VERSION "2021.24.4"

NS_ :

BS_:

BU_: VEH CH Receiver X

BA_DEF_ BO_ "GenMsgSendType" ENUM "Cyclic";
BA_DEF_ BO_ "GenMsgCycleTime" INT 0 10000;

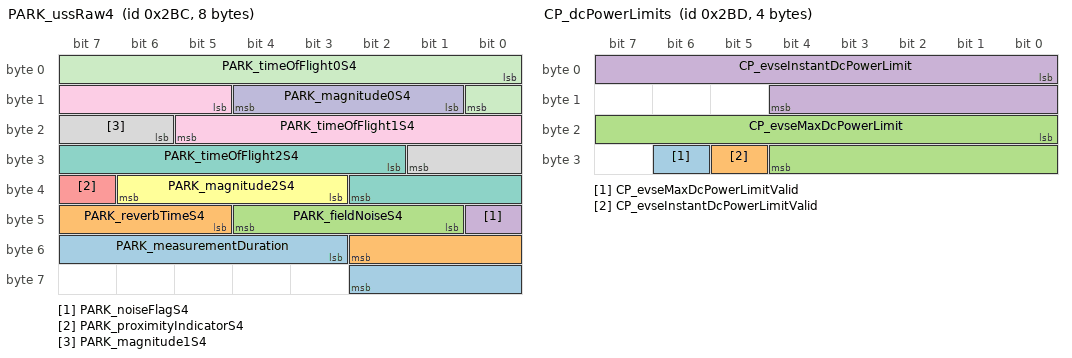
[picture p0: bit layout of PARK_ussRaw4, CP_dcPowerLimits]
BO_ 700 PARK_ussRaw4: 8 Vector__XXX
 SG_ PARK_measurementDuration : 51|8@1+ (0.0512,0) [0|0] "" Vector__XXX
 SG_ PARK_reverbTimeS4 : 45|6@1+ (0.0512,0) [0|0] "" Vector__XXX
 SG_ PARK_fieldNoiseS4 : 41|4@1+ (1,0) [0|0] "" Vector__XXX
 SG_ PARK_noiseFlagS4 : 40|1@1+ (1,0) [0|0] "" Vector__XXX
 SG_ PARK_proximityIndicatorS4 : 39|1@1+ (1,0) [0|0] "" Vector__XXX
 SG_ PARK_magnitude2S4 : 35|4@1+ (2,0) [0|0] "" Vector__XXX
 SG_ PARK_timeOfFlight2S4 : 26|9@1+ (0.0512,0) [0|0] "" Vector__XXX
 SG_ PARK_magnitude1S4 : 22|4@1+ (2,0) [0|0] "" Vector__XXX
 SG_ PARK_timeOfFlight1S4 : 13|9@1+ (0.0512,0) [0|0] "" Vector__XXX
 SG_ PARK_magnitude0S4 : 9|4@1+ (2,0) [0|0] "" Vector__XXX
 SG_ PARK_timeOfFlight0S4 : 0|9@1+ (0.0512,0) [0|0] "" Vector__XXX

BO_ 701 CP_dcPowerLimits: 4 Vector__XXX
 SG_ CP_evseMaxDcPowerLimitValid : 30|1@1+ (1,0) [0|0] "" Vector__XXX
 SG_ CP_evseInstantDcPowerLimitValid : 29|1@1+ (1,0) [0|0] "" Vector__XXX
 SG_ CP_evseMaxDcPowerLimit : 16|13@1+ (0.25,0) [0|0] "" Vector__XXX
 SG_ CP_evseInstantDcPowerLimit : 0|13@1+ (0.25,0) [0|0] "" Vector__XXX

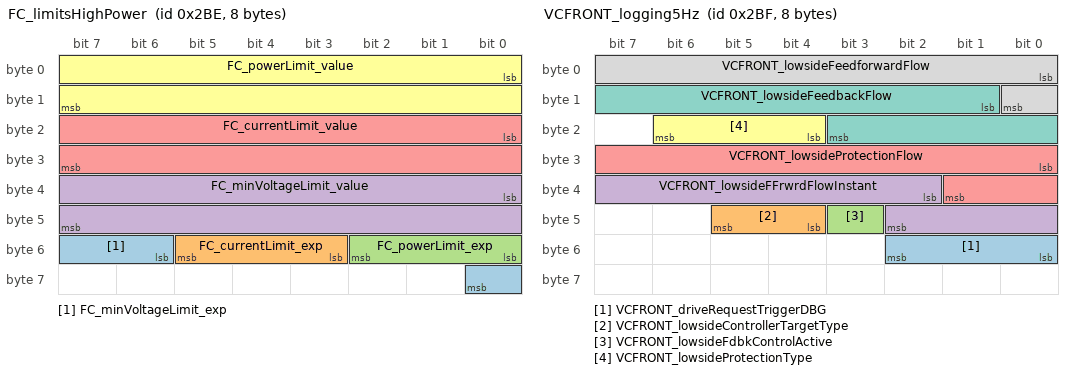
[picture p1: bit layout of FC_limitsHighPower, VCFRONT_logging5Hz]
BO_ 702 FC_limitsHighPower: 8 Vector__XXX
 SG_ FC_minVoltageLimit_exp : 54|3@1- (1,0) [0|0] "" Vector__XXX
 SG_ FC_currentLimit_exp : 51|3@1- (1,0) [0|0] "" Vector__XXX
 SG_ FC_powerLimit_exp : 48|3@1- (1,0) [0|0] "" Vector__XXX
 SG_ FC_minVoltageLimit_value : 32|16@1- (1,0) [0|0] "" Vector__XXX
 SG_ FC_currentLimit_value : 16|16@1- (1,0) [0|0] "" Vector__XXX
 SG_ FC_powerLimit_value : 0|16@1- (1,0) [0|0] "" Vector__XXX

BO_ 703 VCFRONT_logging5Hz: 8 Vector__XXX
 SG_ VCFRONT_driveRequestTriggerDBG : 48|3@1+ (1,0) [0|0] "" Vector__XXX
 SG_ VCFRONT_lowsideControllerTargetType : 44|2@1+ (1,0) [0|0] "" Vector__XXX
 SG_ VCFRONT_lowsideFdbkControlActive : 43|1@1+ (1,0) [0|0] "" Vector__XXX
 SG_ VCFRONT_lowsideFFrwrdFlowInstant : 34|9@1+ (0.2,0) [0|0] "" Vector__XXX
 SG_ VCFRONT_lowsideProtectionFlow : 24|10@1+ (0.1,0) [0|0] "" Vector__XXX
 SG_ VCFRONT_lowsideProtectionType : 20|3@1+ (1,0) [0|0] "" Vector__XXX
 SG_ VCFRONT_lowsideFeedbackFlow : 9|11@1- (0.1,0) [0|0] "" Vector__XXX
 SG_ VCFRONT_lowsideFeedforwardFlow : 0|9@1+ (0.2,0) [0|0] "" Vector__XXX

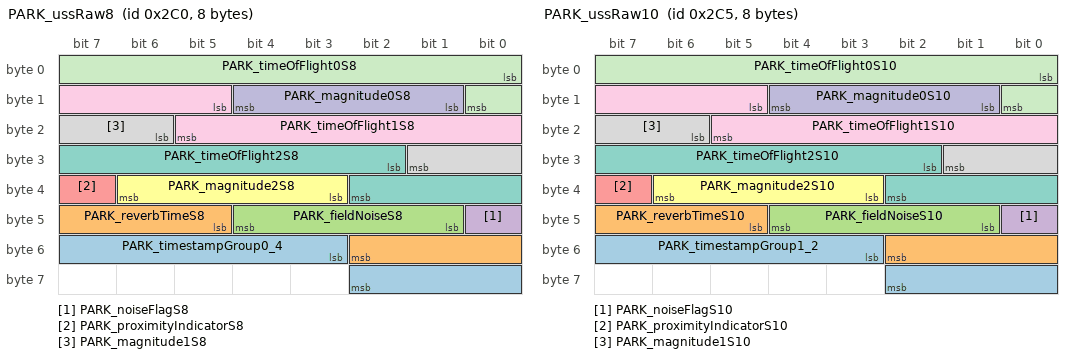
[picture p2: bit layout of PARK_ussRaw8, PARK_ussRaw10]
BO_ 704 PARK_ussRaw8: 8 Vector__XXX
 SG_ PARK_timestampGroup0_4 : 51|8@1+ (1,0) [0|0] "" Vector__XXX
 SG_ PARK_reverbTimeS8 : 45|6@1+ (0.0512,0) [0|0] "" Vector__XXX
 SG_ PARK_fieldNoiseS8 : 41|4@1+ (1,0) [0|0] "" Vector__XXX
 SG_ PARK_noiseFlagS8 : 40|1@1+ (1,0) [0|0] "" Vector__XXX
 SG_ PARK_proximityIndicatorS8 : 39|1@1+ (1,0) [0|0] "" Vector__XXX
 SG_ PARK_magnitude2S8 : 35|4@1+ (2,0) [0|0] "" Vector__XXX
 SG_ PARK_timeOfFlight2S8 : 26|9@1+ (0.0512,0) [0|0] "" Vector__XXX
 SG_ PARK_magnitude1S8 : 22|4@1+ (2,0) [0|0] "" Vector__XXX
 SG_ PARK_timeOfFlight1S8 : 13|9@1+ (0.0512,0) [0|0] "" Vector__XXX
 SG_ PARK_magnitude0S8 : 9|4@1+ (2,0) [0|0] "" Vector__XXX
 SG_ PARK_timeOfFlight0S8 : 0|9@1+ (0.0512,0) [0|0] "" Vector__XXX

BO_ 706 VCLEFT_windowStatus: 8 Vector__XXX
 SG_ VCLEFT_windowCalibratedLR m0 : 63|1@1+ (1,0) [0|0] "" Vector__XXX
 SG_ VCLEFT_windowSpeedTableStatusLR m1 : 62|2@1+ (1,0) [0|0] "" Vector__XXX
 SG_ VCLEFT_windowSpeedTableStatusLF m1 : 60|2@1+ (1,0) [0|0] "" Vector__XXX
 SG_ VCLEFT_windowVehGearStateLR m1 : 58|2@1+ (1,0) [0|0] "" Vector__XXX
 SG_ VCLEFT_windowVehGearStateLF m1 : 56|2@1+ (1,0) [0|0] "" Vector__XXX
 SG_ VCLEFT_windowPositionLR m0 : 54|9@1- (1.25,265) [0|0] "" Vector__XXX
 SG_ VCLEFT_windowPositionStateLR m1 : 52|3@1+ (1,0) [0|0] "" Vector__XXX
 SG_ VCLEFT_windowPositionStateLF m1 : 49|3@1+ (1,0) [0|0] "" Vector__XXX
 SG_ VCLEFT_windowCurrentLR m0 : 48|6@1- (0.5,0) [0|0] "" Vector__XXX
 SG_ VCLEFT_windowCtrlUnavailableLR m1 : 45|3@1+ (1,0) [0|0] "" Vector__XXX
 SG_ VCLEFT_windowControlStateLR m1 : 42|2@1+ (1,0) [0|0] "" Vector__XXX
 SG_ VCLEFT_windowDutyLR m0 : 40|6@1- (5,0) [0|0] "" Vector__XXX
 SG_ VCLEFT_windowCtrlUnavailableLF m1 : 38|3@1+ (1,0) [0|0] "" Vector__XXX
 SG_ VCLEFT_windowControlStateLF m1 : 35|2@1+ (1,0) [0|0] "" Vector__XXX
 SG_ VCLEFT_windowStateLR m0 : 33|4@1+ (1,0) [0|0] "" Vector__XXX
 SG_ VCLEFT_windowCalibratedLF m0 : 32|1@1+ (1,0) [0|0] "" Vector__XXX
 SG_ VCLEFT_windowStopReqReasonLR m1 : 31|4@1+ (1,0) [0|0] "" Vector__XXX
 SG_ VCLEFT_windowStopReasonLR m1 : 28|3@1+ (1,0) [0|0] "" Vector__XXX
 SG_ VCLEFT_windowThermalModeLR m1 : 26|2@1+ (1,0) [0|0] "" Vector__XXX
 SG_ VCLEFT_windowPositionLF m0 : 22|9@1- (1.25,265) [0|0] "" Vector__XXX
 SG_ VCLEFT_windowThermalTCLR m1 : 18|8@1+ (1,0) [0|0] "" Vector__XXX
 SG_ VCLEFT_windowCurrentLF m0 : 16|6@1- (0.5,0) [0|0] "" Vector__XXX
 SG_ VCLEFT_windowStopReqReasonLF m1 : 14|4@1+ (1,0) [0|0] "" Vector__XXX
 SG_ VCLEFT_windowTrimClearActiveRequest m0 : 14|2@1+ (1,0) [0|0] "" Vector__XXX
 SG_ VCLEFT_windowStopReasonLF m1 : 11|3@1+ (1,0) [0|0] "" Vector__XXX
 SG_ VCLEFT_windowThermalModeLF m1 : 9|2@1+ (1,0) [0|0] "" Vector__XXX
 SG_ VCLEFT_windowDutyLF m0 : 8|6@1- (5,0) [0|0] "" Vector__XXX
 SG_ VCLEFT_windowTrimClearMoveRequest m0 : 5|2@1+ (1,0) [0|0] "" Vector__XXX
 SG_ VCLEFT_windowStateLF m0 : 1|4@1+ (1,0) [0|0] "" Vector__XXX
 SG_ VCLEFT_windowThermalTCLF m1 : 1|8@1+ (1,0) [0|0] "" Vector__XXX
 SG_ VCLEFT_windowStatusIndex M : 0|1@1+ (1,0) [0|0] "" Vector__XXX

BO_ 707 VCRIGHT_windowStatus: 8 Vector__XXX
 SG_ VCRIGHT_windowCalibratedRR m0 : 63|1@1+ (1,0) [0|0] "" Vector__XXX
 SG_ VCRIGHT_windowSpeedTableStatusRR m1 : 62|2@1+ (1,0) [0|0] "" Vector__XXX
 SG_ VCRIGHT_windowSpeedTableStatusRF m1 : 60|2@1+ (1,0) [0|0] "" Vector__XXX
 SG_ VCRIGHT_windowVehGearStateRR m1 : 58|2@1+ (1,0) [0|0] "" Vector__XXX
 SG_ VCRIGHT_windowVehGearStateRF m1 : 56|2@1+ (1,0) [0|0] "" Vector__XXX
 SG_ VCRIGHT_windowPositionRR m0 : 54|9@1- (1.25,265) [0|0] "" Vector__XXX
 SG_ VCRIGHT_windowPositionStateRR m1 : 52|3@1+ (1,0) [0|0] "" Vector__XXX
 SG_ VCRIGHT_windowPositionStateRF m1 : 49|3@1+ (1,0) [0|0] "" Vector__XXX
 SG_ VCRIGHT_windowCurrentRR m0 : 48|6@1- (0.5,0) [0|0] "" Vector__XXX
 SG_ VCRIGHT_windowCtrlUnavailableRR m1 : 45|3@1+ (1,0) [0|0] "" Vector__XXX
 SG_ VCRIGHT_windowControlStateRR m1 : 42|2@1+ (1,0) [0|0] "" Vector__XXX
 SG_ VCRIGHT_windowDutyRR m0 : 40|6@1- (5,0) [0|0] "" Vector__XXX
 SG_ VCRIGHT_windowCtrlUnavailableRF m1 : 38|3@1+ (1,0) [0|0] "" Vector__XXX
 SG_ VCRIGHT_windowControlStateRF m1 : 35|2@1+ (1,0) [0|0] "" Vector__XXX
 SG_ VCRIGHT_windowStateRR m0 : 33|4@1+ (1,0) [0|0] "" Vector__XXX
 SG_ VCRIGHT_windowCalibratedRF m0 : 32|1@1+ (1,0) [0|0] "" Vector__XXX
 SG_ VCRIGHT_windowStopReqReasonRR m1 : 31|4@1+ (1,0) [0|0] "" Vector__XXX
 SG_ VCRIGHT_windowStopReasonRR m1 : 28|3@1+ (1,0) [0|0] "" Vector__XXX
 SG_ VCRIGHT_windowThermalModeRR m1 : 26|2@1+ (1,0) [0|0] "" Vector__XXX
 SG_ VCRIGHT_windowPositionRF m0 : 22|9@1- (1.25,265) [0|0] "" Vector__XXX
 SG_ VCRIGHT_windowThermalTCRR m1 : 18|8@1+ (1,0) [0|0] "" Vector__XXX
 SG_ VCRIGHT_windowCurrentRF m0 : 16|6@1- (0.5,0) [0|0] "" Vector__XXX
 SG_ VCRIGHT_windowStopReqReasonRF m1 : 14|4@1+ (1,0) [0|0] "" Vector__XXX
 SG_ VCRIGHT_windowTrimClearActiveRequest m0 : 14|2@1+ (1,0) [0|0] "" Vector__XXX
 SG_ VCRIGHT_windowStopReasonRF m1 : 11|3@1+ (1,0) [0|0] "" Vector__XXX
 SG_ VCRIGHT_windowThermalModeRF m1 : 9|2@1+ (1,0) [0|0] "" Vector__XXX
 SG_ VCRIGHT_windowDutyRF m0 : 8|6@1- (5,0) [0|0] "" Vector__XXX
 SG_ VCRIGHT_windowTrimClearMoveRequest m0 : 5|2@1+ (1,0) [0|0] "" Vector__XXX
 SG_ VCRIGHT_windowStateRF m0 : 1|4@1+ (1,0) [0|0] "" Vector__XXX
 SG_ VCRIGHT_windowThermalTCRF m1 : 1|8@1+ (1,0) [0|0] "" Vector__XXX
 SG_ VCRIGHT_windowStatusIndex M : 0|1@1+ (1,0) [0|0] "" Vector__XXX

BO_ 709 PARK_ussRaw10: 8 Vector__XXX
 SG_ PARK_timestampGroup1_2 : 51|8@1+ (1,0) [0|0] "" Vector__XXX
 SG_ PARK_reverbTimeS10 : 45|6@1+ (0.0512,0) [0|0] "" Vector__XXX
 SG_ PARK_fieldNoiseS10 : 41|4@1+ (1,0) [0|0] "" Vector__XXX
 SG_ PARK_noiseFlagS10 : 40|1@1+ (1,0) [0|0] "" Vector__XXX
 SG_ PARK_proximityIndicatorS10 : 39|1@1+ (1,0) [0|0] "" Vector__XXX
 SG_ PARK_magnitude2S10 : 35|4@1+ (2,0) [0|0] "" Vector__XXX
 SG_ PARK_timeOfFlight2S10 : 26|9@1+ (0.0512,0) [0|0] "" Vector__XXX
 SG_ PARK_magnitude1S10 : 22|4@1+ (2,0) [0|0] "" Vector__XXX
 SG_ PARK_timeOfFlight1S10 : 13|9@1+ (0.0512,0) [0|0] "" Vector__XXX
 SG_ PARK_magnitude0S10 : 9|4@1+ (2,0) [0|0] "" Vector__XXX
 SG_ PARK_timeOfFlight0S10 : 0|9@1+ (0.0512,0) [0|0] "" Vector__XXX

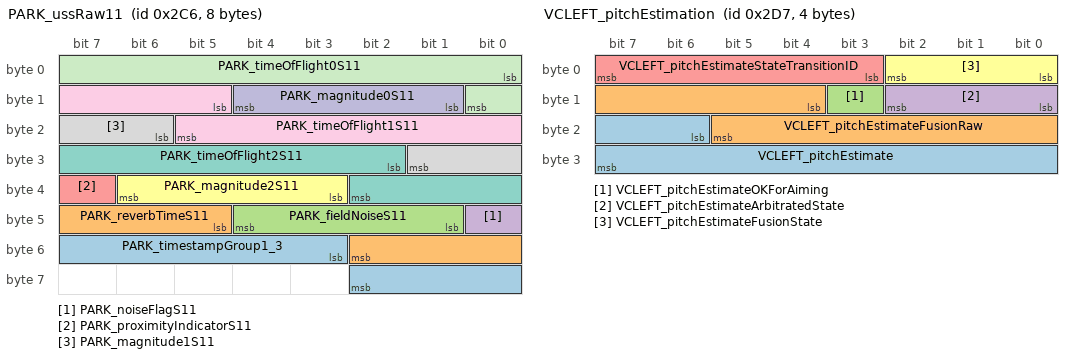
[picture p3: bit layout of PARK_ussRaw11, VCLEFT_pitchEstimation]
BO_ 710 PARK_ussRaw11: 8 Vector__XXX
 SG_ PARK_timestampGroup1_3 : 51|8@1+ (1,0) [0|0] "" Vector__XXX
 SG_ PARK_reverbTimeS11 : 45|6@1+ (0.0512,0) [0|0] "" Vector__XXX
 SG_ PARK_fieldNoiseS11 : 41|4@1+ (1,0) [0|0] "" Vector__XXX
 SG_ PARK_noiseFlagS11 : 40|1@1+ (1,0) [0|0] "" Vector__XXX
 SG_ PARK_proximityIndicatorS11 : 39|1@1+ (1,0) [0|0] "" Vector__XXX
 SG_ PARK_magnitude2S11 : 35|4@1+ (2,0) [0|0] "" Vector__XXX
 SG_ PARK_timeOfFlight2S11 : 26|9@1+ (0.0512,0) [0|0] "" Vector__XXX
 SG_ PARK_magnitude1S11 : 22|4@1+ (2,0) [0|0] "" Vector__XXX
 SG_ PARK_timeOfFlight1S11 : 13|9@1+ (0.0512,0) [0|0] "" Vector__XXX
 SG_ PARK_magnitude0S11 : 9|4@1+ (2,0) [0|0] "" Vector__XXX
 SG_ PARK_timeOfFlight0S11 : 0|9@1+ (0.0512,0) [0|0] "" Vector__XXX

BO_ 711 CMPD_faultsAndExtras: 8 Vector__XXX
 SG_ CMPD_inputLVVoltage : 56|8@1+ (0.1,0) [0|0] "" Vector__XXX
 SG_ CMPD_inverterTemperature : 48|8@1+ (1,-40) [0|0] "" Vector__XXX
 SG_ CMPD_IGBTTemperature : 40|8@1+ (1,-40) [0|0] "" Vector__XXX
 SG_ CMPD_overloadDetectionOfSpeed : 32|1@1+ (1,0) [0|0] "" Vector__XXX
 SG_ CMPD_overloadRestrictionCurrent : 31|1@1+ (1,0) [0|0] "" Vector__XXX
 SG_ CMPD_overloadLossOfSync : 30|1@1+ (1,0) [0|0] "" Vector__XXX
 SG_ CMPD_overloadStartFaultDetection : 29|1@1+ (1,0) [0|0] "" Vector__XXX
 SG_ CMPD_overloadStatus : 27|2@1+ (1,0) [0|0] "" Vector__XXX
 SG_ CMPD_overCurrent : 26|1@1+ (1,0) [0|0] "" Vector__XXX
 SG_ CMPD_failedStartRepeated : 25|1@1+ (1,0) [0|0] "" Vector__XXX
 SG_ CMPD_failedStart : 24|1@1+ (1,0) [0|0] "" Vector__XXX
 SG_ CMPD_underTemperature : 23|1@1+ (1,0) [0|0] "" Vector__XXX
 SG_ CMPD_overTemperature : 22|1@1+ (1,0) [0|0] "" Vector__XXX
 SG_ CMPD_warnOverTemperature : 21|1@1+ (1,0) [0|0] "" Vector__XXX
 SG_ CMPD_shortCircuit : 20|1@1+ (1,0) [0|0] "" Vector__XXX
 SG_ CMPD_inverterOpenCircuit : 19|1@1+ (1,0) [0|0] "" Vector__XXX
 SG_ CMPD_internalPowerSupplyFault : 18|1@1+ (1,0) [0|0] "" Vector__XXX
 SG_ CMPD_selfTestFailCPU : 17|1@1+ (1,0) [0|0] "" Vector__XXX
 SG_ CMPD_currentSnsError : 16|1@1+ (1,0) [0|0] "" Vector__XXX
 SG_ CMPD_tempSnsFaultCPU : 15|1@1+ (1,0) [0|0] "" Vector__XXX
 SG_ CMPD_tempSnsFaultIPM2 : 14|1@1+ (1,0) [0|0] "" Vector__XXX
 SG_ CMPD_tempSnsFaultIPM1 : 13|1@1+ (1,0) [0|0] "" Vector__XXX
 SG_ CMPD_HVUnderVoltage : 12|1@1+ (1,0) [0|0] "" Vector__XXX
 SG_ CMPD_HVOverVoltage : 11|1@1+ (1,0) [0|0] "" Vector__XXX
 SG_ CMPD_LVOverVoltage : 10|1@1+ (1,0) [0|0] "" Vector__XXX
 SG_ CMPD_LVUnderVoltage : 9|1@1+ (1,0) [0|0] "" Vector__XXX
 SG_ CMPD_VCFRONTCANTimeout : 8|1@1+ (1,0) [0|0] "" Vector__XXX
 SG_ CMPD_limitOverCurrentHVDC : 2|1@1+ (1,0) [0|0] "" Vector__XXX
 SG_ CMPD_limitOverCurrentPhase : 1|1@1+ (1,0) [0|0] "" Vector__XXX
 SG_ CMPD_limitUnderVoltage : 0|1@1+ (1,0) [0|0] "" Vector__XXX

BO_ 727 VCLEFT_pitchEstimation: 4 Vector__XXX
 SG_ VCLEFT_pitchEstimate : 22|10@1- (0.0002,0) [0|0] "" Vector__XXX
 SG_ VCLEFT_pitchEstimateFusionRaw : 12|10@1- (0.0002,0) [0|0] "" Vector__XXX
 SG_ VCLEFT_pitchEstimateOKForAiming : 11|1@1+ (1,0) [0|0] "" Vector__XXX
 SG_ VCLEFT_pitchEstimateArbitratedState : 8|3@1+ (1,0) [0|0] "" Vector__XXX
 SG_ VCLEFT_pitchEstimateStateTransitionID : 3|5@1+ (1,0) [0|0] "" Vector__XXX
 SG_ VCLEFT_pitchEstimateFusionState : 0|3@1+ (1,0) [0|0] "" Vector__XXX

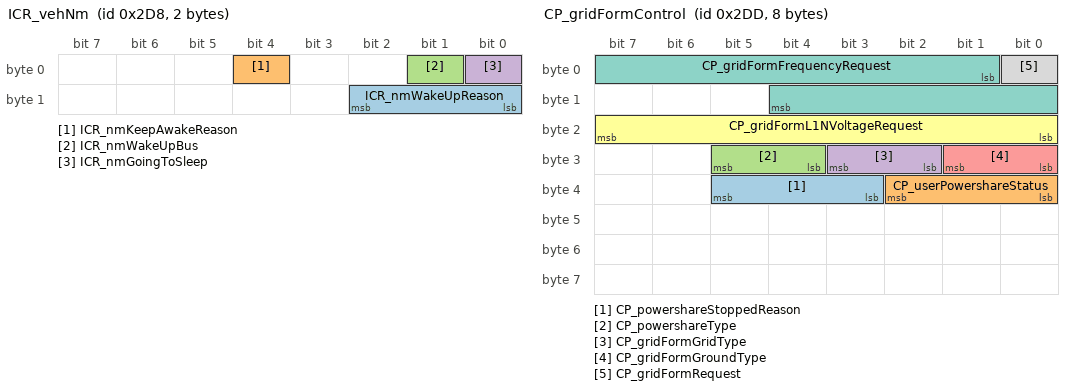
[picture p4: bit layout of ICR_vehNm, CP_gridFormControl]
BO_ 728 ICR_vehNm: 2 Vector__XXX
 SG_ ICR_nmWakeUpReason : 8|3@1+ (1,0) [0|0] "" Vector__XXX
 SG_ ICR_nmKeepAwakeReason : 4|1@1+ (1,0) [0|0] "" Vector__XXX
 SG_ ICR_nmWakeUpBus : 1|1@1+ (1,0) [0|0] "" Vector__XXX
 SG_ ICR_nmGoingToSleep : 0|1@1+ (1,0) [0|0] "" Vector__XXX

BO_ 733 CP_gridFormControl: 8 Vector__XXX
 SG_ CP_powershareStoppedReason : 35|3@1+ (1,0) [0|0] "" Vector__XXX
 SG_ CP_userPowershareStatus : 32|3@1+ (1,0) [0|0] "" Vector__XXX
 SG_ CP_powershareType : 28|2@1+ (1,0) [0|0] "" Vector__XXX
 SG_ CP_gridFormGridType : 26|2@1+ (1,0) [0|0] "" Vector__XXX
 SG_ CP_gridFormGroundType : 24|2@1+ (1,0) [0|0] "" Vector__XXX
 SG_ CP_gridFormL1NVoltageRequest : 16|8@1+ (1,40) [0|0] "" Vector__XXX
 SG_ CP_gridFormFrequencyRequest : 1|12@1+ (0.01,40) [0|0] "" Vector__XXX
 SG_ CP_gridFormRequest : 0|1@1+ (1,0) [0|0] "" Vector__XXX

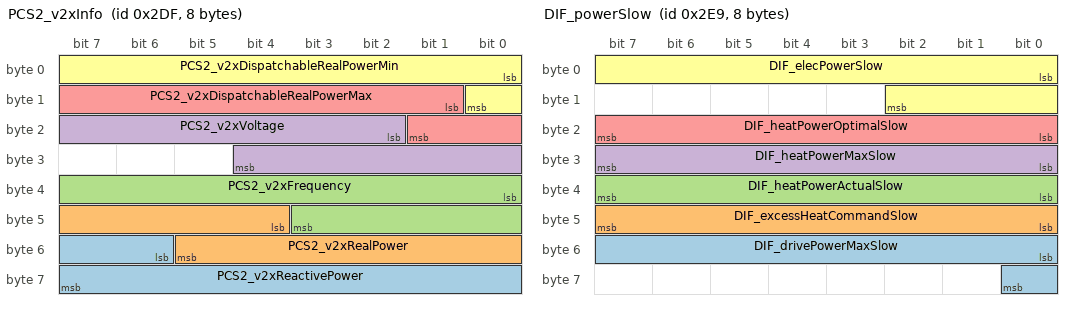
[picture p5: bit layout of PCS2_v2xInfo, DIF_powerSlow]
BO_ 735 PCS2_v2xInfo: 8 Vector__XXX
 SG_ PCS2_v2xReactivePower : 54|10@1- (0.05,0) [0|0] "" Vector__XXX
 SG_ PCS2_v2xRealPower : 44|10@1- (0.05,0) [0|0] "" Vector__XXX
 SG_ PCS2_v2xFrequency : 32|12@1+ (0.01,40) [0|0] "" Vector__XXX
 SG_ PCS2_v2xVoltage : 18|11@1+ (0.2,0) [0|0] "" Vector__XXX
 SG_ PCS2_v2xDispatchableRealPowerMax : 9|9@1+ (0.05,0) [0|0] "" Vector__XXX
 SG_ PCS2_v2xDispatchableRealPowerMin : 0|9@1- (0.05,-9.95) [0|0] "" Vector__XXX

BO_ 738 VCLEFT_seatStatus2: 8 Vector__XXX
 SG_ VC_AH_1RowLeftSeatHeatVentHealth m0 : 62|2@1+ (1,0) [0|0] "" Vector__XXX
 SG_ VC_AH_2RowCenterSeatHeatVentHealth m4 : 62|2@1+ (1,0) [0|0] "" Vector__XXX
 SG_ VC_AH_2RowLeftSeatHeatVentHealth m3 : 62|2@1+ (1,0) [0|0] "" Vector__XXX
 SG_ VC_AH_2RowRightSeatHeatVentHealth m5 : 62|2@1+ (1,0) [0|0] "" Vector__XXX
 SG_ VCLEFT_2RowSeatCenterSwitchVoltage m7 : 54|10@1+ (0.01,0) [0|0] "" Vector__XXX
 SG_ VCLEFT_rearCenterBuckleVoltage m2 : 52|8@1+ (0.02,0) [0|0] "" Vector__XXX
 SG_ VCLEFT_frontSeatHeatPowered m0 : 45|1@1+ (1,0) [0|0] "" Vector__XXX
 SG_ VCLEFT_rearCHeatPowered m4 : 45|1@1+ (1,0) [0|0] "" Vector__XXX
 SG_ VCLEFT_rearLBackHeatPowered m1 : 45|1@1+ (1,0) [0|0] "" Vector__XXX
 SG_ VCLEFT_rearLHeatPowered m3 : 45|1@1+ (1,0) [0|0] "" Vector__XXX
 SG_ VCLEFT_rearRCushionHeatPowered m5 : 45|1@1+ (1,0) [0|0] "" Vector__XXX
 SG_ VCLEFT_2RowSeatEasyEntrySwitchVoltage m7 : 44|10@1+ (0.01,0) [0|0] "" Vector__XXX
 SG_ VCLEFT_frontSeatHeatInhibited m0 : 44|1@1+ (1,0) [0|0] "" Vector__XXX
 SG_ VCLEFT_rearCHeatInhibited m4 : 44|1@1+ (1,0) [0|0] "" Vector__XXX
 SG_ VCLEFT_rearLBackHeatInhibited m1 : 44|1@1+ (1,0) [0|0] "" Vector__XXX
 SG_ VCLEFT_rearLHeatInhibited m3 : 44|1@1+ (1,0) [0|0] "" Vector__XXX
 SG_ VCLEFT_rearRCushionHeatInhibited m5 : 44|1@1+ (1,0) [0|0] "" Vector__XXX
 SG_ VCLEFT_rearRightOccupancyVoltage m2 : 44|8@1+ (0.02,0) [0|0] "" Vector__XXX
 SG_ VCLEFT_2RowSeatCenterActuatorDuty m6 : 40|12@1- (0.1,0) [0|0] "" Vector__XXX
 SG_ VCLEFT_frontSeatHeatTmpTarget m0 : 36|8@1- (0.5,0) [0|0] "" Vector__XXX
 SG_ VCLEFT_rearCHeatTmpTarget m4 : 36|8@1- (0.5,0) [0|0] "" Vector__XXX
 SG_ VCLEFT_rearCenterOccupancyVoltage m2 : 36|8@1+ (0.02,0) [0|0] "" Vector__XXX
 SG_ VCLEFT_rearLBackHeatTmpTarget m1 : 36|8@1- (0.5,0) [0|0] "" Vector__XXX
 SG_ VCLEFT_rearLHeatTmpTarget m3 : 36|8@1- (0.5,0) [0|0] "" Vector__XXX
 SG_ VCLEFT_rearRCushionHeatTmpTarget m5 : 36|8@1- (0.5,0) [0|0] "" Vector__XXX
 SG_ VCLEFT_2RowSeatReclineSwitchVoltage m7 : 34|10@1+ (0.01,0) [0|0] "" Vector__XXX
 SG_ VCLEFT_2RowSeatTrackPositionSwitch m9 : 31|2@1+ (1,0) [0|0] "" Vector__XXX
 SG_ VCLEFT_2RowSeatCenterActuatorCurrent m6 : 28|12@1- (0.01,0) [0|0] "" Vector__XXX
 SG_ VCLEFT_2RowSeatEasyEntryState m9 : 28|3@1+ (1,0) [0|0] "" Vector__XXX
 SG_ VCLEFT_rearLeftOccupancyVoltage m2 : 28|8@1+ (0.02,0) [0|0] "" Vector__XXX
 SG_ VCLEFT_frontSeatHeatTmp m0 : 24|12@1- (0.05,0) [0|0] "" Vector__XXX
 SG_ VCLEFT_frontSeatLiftTiltSwitchVoltage m7 : 24|10@1+ (0.01,0) [0|0] "" Vector__XXX
 SG_ VCLEFT_rearCHeatTmp m4 : 24|12@1- (0.05,0) [0|0] "" Vector__XXX
 SG_ VCLEFT_rearLBackHeatTmp m1 : 24|12@1- (0.05,0) [0|0] "" Vector__XXX
 SG_ VCLEFT_rearLHeatTmp m3 : 24|12@1- (0.05,0) [0|0] "" Vector__XXX
 SG_ VCLEFT_rearRCushionHeatTmp m5 : 24|12@1- (0.05,0) [0|0] "" Vector__XXX
 SG_ VCLEFT_rearLeftBuckleVoltage m2 : 20|8@1+ (0.02,0) [0|0] "" Vector__XXX
 SG_ VCLEFT_2RowSeatReclineActuatorDuty m6 : 16|12@1- (0.1,0) [0|0] "" Vector__XXX
 SG_ VCLEFT_2RowSeatTrackActuatorDuty m9 : 16|12@1- (0.1,0) [0|0] "" Vector__XXX
 SG_ VCLEFT_frontSeatHeatDuty m0 : 16|8@1+ (1,0) [0|0] "" Vector__XXX
 SG_ VCLEFT_rearCHeatDuty m4 : 16|8@1+ (1,0) [0|0] "" Vector__XXX
 SG_ VCLEFT_rearLBackHeatDuty m1 : 16|8@1+ (1,0) [0|0] "" Vector__XXX
 SG_ VCLEFT_rearLHeatDuty m3 : 16|8@1+ (1,0) [0|0] "" Vector__XXX
 SG_ VCLEFT_rearRCushionHeatDuty m5 : 16|8@1+ (1,0) [0|0] "" Vector__XXX
 SG_ VCLEFT_frontSeatLumbarSwitchVoltage m7 : 14|10@1+ (0.01,0) [0|0] "" Vector__XXX
 SG_ VCLEFT_trunkFoldFlatRightSwitchVoltage m8 : 14|10@1+ (0.01,0) [0|0] "" Vector__XXX
 SG_ VCLEFT_frontBuckleVoltage m2 : 12|8@1+ (0.02,0) [0|0] "" Vector__XXX
 SG_ VCLEFT_2RowSeatReclineActuatorCurrent m6 : 4|12@1- (0.01,0) [0|0] "" Vector__XXX
 SG_ VCLEFT_2RowSeatTrackActuatorCurrent m9 : 4|12@1- (0.01,0) [0|0] "" Vector__XXX
 SG_ VCLEFT_frontOccupancyVoltage m2 : 4|8@1+ (0.02,0) [0|0] "" Vector__XXX
 SG_ VCLEFT_frontSeatHeatCurrent m0 : 4|12@1+ (0.01,0) [0|0] "" Vector__XXX
 SG_ VCLEFT_frontSeatTrackBackrestSwitchVoltage m7 : 4|10@1+ (0.01,0) [0|0] "" Vector__XXX
 SG_ VCLEFT_rearCHeatCurrent m4 : 4|12@1+ (0.01,0) [0|0] "" Vector__XXX
 SG_ VCLEFT_rearLBackHeatCurrent m1 : 4|12@1+ (0.01,0) [0|0] "" Vector__XXX
 SG_ VCLEFT_rearLHeatCurrent m3 : 4|12@1+ (0.01,0) [0|0] "" Vector__XXX
 SG_ VCLEFT_rearRCushionHeatCurrent m5 : 4|12@1+ (0.01,0) [0|0] "" Vector__XXX
 SG_ VCLEFT_trunkFoldFlatLeftSwitchVoltage m8 : 4|10@1+ (0.004887585532746823,0) [0|0] "" Vector__XXX
 SG_ VCLEFT_seatStatus2Index M : 0|4@1+ (1,0) [0|0] "" Vector__XXX

BO_ 739 VCRIGHT_seatStatus2: 7 Vector__XXX
 SG_ VC_AH_1RowRightSeatHeatVentHealth m0 : 54|2@1+ (1,0) [0|0] "" Vector__XXX
 SG_ VCRIGHT_occupantClassificationHoldState m4 : 46|2@1+ (1,0) [0|0] "" Vector__XXX
 SG_ VCRIGHT_frontSeatHeatPowered m0 : 45|1@1+ (1,0) [0|0] "" Vector__XXX
 SG_ VCRIGHT_rearCSeatHeatPowered m2 : 45|1@1+ (1,0) [0|0] "" Vector__XXX
 SG_ VCRIGHT_rearLSeatHeatPowered m1 : 45|1@1+ (1,0) [0|0] "" Vector__XXX
 SG_ VCRIGHT_rearRSeatHeatPowered m3 : 45|1@1+ (1,0) [0|0] "" Vector__XXX
 SG_ VCRIGHT_2RowSeatEasyEntrySwitchVoltage m7 : 44|10@1+ (0.01,0) [0|0] "" Vector__XXX
 SG_ VCRIGHT_frontSeatHeatInhibited m0 : 44|1@1+ (1,0) [0|0] "" Vector__XXX
 SG_ VCRIGHT_rearCSeatHeatInhibited m2 : 44|1@1+ (1,0) [0|0] "" Vector__XXX
 SG_ VCRIGHT_rearLSeatHeatInhibited m1 : 44|1@1+ (1,0) [0|0] "" Vector__XXX
 SG_ VCRIGHT_rearRSeatHeatInhibited m3 : 44|1@1+ (1,0) [0|0] "" Vector__XXX
 SG_ VCRIGHT_frontSeatHeatTmpTarget m0 : 36|8@1- (0.5,0) [0|0] "" Vector__XXX
 SG_ VCRIGHT_rearCSeatHeatTmpTarget m2 : 36|8@1- (0.5,0) [0|0] "" Vector__XXX
 SG_ VCRIGHT_rearLSeatHeatTmpTarget m1 : 36|8@1- (0.5,0) [0|0] "" Vector__XXX
 SG_ VCRIGHT_rearRSeatHeatTmpTarget m3 : 36|8@1- (0.5,0) [0|0] "" Vector__XXX
 SG_ VCRIGHT_2RowSeatReclineSwitchVoltage m7 : 34|10@1+ (0.01,0) [0|0] "" Vector__XXX
 SG_ VCRIGHT_rearRightBuckleVoltage m4 : 34|10@1+ (0.01,0) [0|0] "" Vector__XXX
 SG_ VCRIGHT_ocsIEEState m10 : 32|3@1+ (1,0) [0|0] "" Vector__XXX
 SG_ VCRIGHT_2RowSeatTrackPositionSwitch m9 : 31|2@1+ (1,0) [0|0] "" Vector__XXX
 SG_ VCRIGHT_2RowSeatEasyEntryState m9 : 28|3@1+ (1,0) [0|0] "" Vector__XXX
 SG_ VCRIGHT_3RUSBPortsCurrentAvg m6 : 28|8@1+ (0.01,0) [0|0] "" Vector__XXX
 SG_ VCRIGHT_frontSeatHeatTmp m0 : 24|12@1- (0.05,0) [0|0] "" Vector__XXX
 SG_ VCRIGHT_frontSeatLiftTiltSwitchVoltage m7 : 24|10@1+ (0.01,0) [0|0] "" Vector__XXX
 SG_ VCRIGHT_rearCSeatHeatTmp m2 : 24|12@1- (0.05,0) [0|0] "" Vector__XXX
 SG_ VCRIGHT_rearCenterBuckleVoltage m4 : 24|10@1+ (0.01,0) [0|0] "" Vector__XXX
 SG_ VCRIGHT_rearLSeatHeatTmp m1 : 24|12@1- (0.05,0) [0|0] "" Vector__XXX
 SG_ VCRIGHT_rearRSeatHeatTmp m3 : 24|12@1- (0.05,0) [0|0] "" Vector__XXX
 SG_ VCRIGHT_ocsIEEPowerCurrent m10 : 20|12@1+ (0.001,0) [0|0] "" Vector__XXX
 SG_ VCRIGHT_ocsIEESnsrPassSeatCalRespSts m10 : 18|2@1+ (1,0) [0|0] "" Vector__XXX
 SG_ VCRIGHT_ocsIEEReqOfClrOfFlt m10 : 17|1@1+ (1,0) [0|0] "" Vector__XXX
 SG_ VCRIGHT_2RowSeatReclineActuatorDuty m6 : 16|12@1- (0.1,0) [0|0] "" Vector__XXX
 SG_ VCRIGHT_2RowSeatTrackActuatorDuty m9 : 16|12@1- (0.1,0) [0|0] "" Vector__XXX
 SG_ VCRIGHT_frontSeatHeatDuty m0 : 16|8@1+ (1,0) [0|0] "" Vector__XXX
 SG_ VCRIGHT_ocsIEEReqOfPassSeatCal m10 : 16|1@1+ (1,0) [0|0] "" Vector__XXX
 SG_ VCRIGHT_rearCSeatHeatDuty m2 : 16|8@1+ (1,0) [0|0] "" Vector__XXX
 SG_ VCRIGHT_rearLSeatHeatDuty m1 : 16|8@1+ (1,0) [0|0] "" Vector__XXX
 SG_ VCRIGHT_rearRSeatHeatDuty m3 : 16|8@1+ (1,0) [0|0] "" Vector__XXX
 SG_ VCRIGHT_ocsIEEFltResp8 m10 : 15|1@1+ (1,0) [0|0] "" Vector__XXX
 SG_ VCRIGHT_3RowSeatRightReclineSwitchVoltage m8 : 14|10@1+ (0.01,0) [0|0] "" Vector__XXX
 SG_ VCRIGHT_frontBuckleVoltage m4 : 14|10@1+ (0.01,0) [0|0] "" Vector__XXX
 SG_ VCRIGHT_frontSeatLumbarSwitchVoltage m7 : 14|10@1+ (0.01,0) [0|0] "" Vector__XXX
 SG_ VCRIGHT_ocsIEEFltResp7 m10 : 14|1@1+ (1,0) [0|0] "" Vector__XXX
 SG_ VCRIGHT_ocsIEEFltResp6 m10 : 13|1@1+ (1,0) [0|0] "" Vector__XXX
 SG_ VCRIGHT_ocsIEEFltResp5 m10 : 12|1@1+ (1,0) [0|0] "" Vector__XXX
 SG_ VCRIGHT_ocsIEEFltResp4 m10 : 11|1@1+ (1,0) [0|0] "" Vector__XXX
 SG_ VCRIGHT_ocsIEEFltResp3 m10 : 10|1@1+ (1,0) [0|0] "" Vector__XXX
 SG_ VCRIGHT_ocsIEEFltResp2 m10 : 9|1@1+ (1,0) [0|0] "" Vector__XXX
 SG_ VCRIGHT_ocsIEEFltResp1 m10 : 8|1@1+ (1,0) [0|0] "" Vector__XXX
 SG_ VCRIGHT_ocsIEEMIA m10 : 7|1@1+ (1,0) [0|0] "" Vector__XXX
 SG_ VCRIGHT_ocsIEEEcuFailr m10 : 6|1@1+ (1,0) [0|0] "" Vector__XXX
 SG_ VCRIGHT_2RowSeatReclineActuatorCurrent m6 : 4|12@1- (0.01,0) [0|0] "" Vector__XXX
 SG_ VCRIGHT_2RowSeatTrackActuatorCurrent m9 : 4|12@1- (0.01,0) [0|0] "" Vector__XXX
 SG_ VCRIGHT_3RowSeatLeftReclineSwitchVoltage m8 : 4|10@1+ (0.01,0) [0|0] "" Vector__XXX
 SG_ VCRIGHT_frontOccupancyVoltage m4 : 4|10@1+ (0.01,0) [0|0] "" Vector__XXX
 SG_ VCRIGHT_frontSeatHeatCurrent m0 : 4|12@1+ (0.01,0) [0|0] "" Vector__XXX
 SG_ VCRIGHT_frontSeatTrackBackrestSwitchVoltage m7 : 4|10@1+ (0.01,0) [0|0] "" Vector__XXX
 SG_ VCRIGHT_ocsIEEAirbAllwdSts m10 : 4|2@1+ (1,0) [0|0] "" Vector__XXX
 SG_ VCRIGHT_rearCSeatHeatCurrent m2 : 4|12@1+ (0.01,0) [0|0] "" Vector__XXX
 SG_ VCRIGHT_rearLSeatHeatCurrent m1 : 4|12@1+ (0.01,0) [0|0] "" Vector__XXX
 SG_ VCRIGHT_rearRSeatHeatCurrent m3 : 4|12@1+ (0.01,0) [0|0] "" Vector__XXX
 SG_ VCRIGHT_seatStatus2Index M : 0|4@1+ (1,0) [0|0] "" Vector__XXX

BO_ 740 PCS2_logging: 8 Vector__XXX
 SG_ PCS2_dcdcAThermalLimited m11 : 63|1@1+ (1,0) [0|0] "" Vector__XXX
 SG_ PCS2_dcdcBThermalLimited m72 : 63|1@1+ (1,0) [0|0] "" Vector__XXX
 SG_ PCS2_mfgFuncTestVoltageEmuMeasEn m12 : 63|1@1+ (1,0) [0|0] "" Vector__XXX
 SG_ PCS2_latchedLineConfiguration m135 : 62|2@1+ (1,0) [0|0] "" Vector__XXX
 SG_ PCS2_mfgFuncTestBottomBoardEnabl m12 : 62|1@1+ (1,0) [0|0] "" Vector__XXX
 SG_ PCS2_mfgFuncTestTopBoardEnable m12 : 61|1@1+ (1,0) [0|0] "" Vector__XXX
 SG_ PCS2_pcs2_pwm_xbar_HV_BATT_OV_OR m35 : 61|1@1+ (1,0) [0|0] "" Vector__XXX
 SG_ PCS2_legHardTiedToNeutral m135 : 60|2@1+ (1,0) [0|0] "" Vector__XXX
 SG_ PCS2_pcs2_pwm_xbar_HV_BUS_OV_OR_ m35 : 60|1@1+ (1,0) [0|0] "" Vector__XXX
 SG_ PCS2_pcs2lite_pwm_xbar_HV_BUS_OV m36 : 60|1@1+ (1,0) [0|0] "" Vector__XXX
 SG_ PCS2_pcsci_pwm_xbar_HV_BUS_OV_OR m37 : 60|1@1+ (1,0) [0|0] "" Vector__XXX
 SG_ PCS2_pcs2_pwm_xbar_LV_BUS_OV_OR_ m35 : 59|1@1+ (1,0) [0|0] "" Vector__XXX
 SG_ PCS2_pcs2lite_pwm_xbar_LV_BUS_OV m36 : 59|1@1+ (1,0) [0|0] "" Vector__XXX
 SG_ PCS2_pcsci_pwm_xbar_LV_BUS_OV_OR m37 : 59|1@1+ (1,0) [0|0] "" Vector__XXX
 SG_ PCS2_pcs2_pwm_xbar_HVDC_OC m35 : 58|1@1+ (1,0) [0|0] "" Vector__XXX
 SG_ PCS2_pcs2lite_pwm_xbar_HVDC_OC m36 : 58|1@1+ (1,0) [0|0] "" Vector__XXX
 SG_ PCS2_pcsci_pwm_xbar_HVDC_OC m37 : 58|1@1+ (1,0) [0|0] "" Vector__XXX
 SG_ PCS2_pcs2_pwm_xbar_TEMPSENSE m35 : 57|1@1+ (1,0) [0|0] "" Vector__XXX
 SG_ PCS2_pcs2lite_pwm_xbar_BUCK_0000 m36 : 57|1@1+ (1,0) [0|0] "" Vector__XXX
 SG_ PCS2_acManagerOperatingMode m135 : 56|4@1+ (1,0) [0|0] "" Vector__XXX
 SG_ PCS2_baseCurrentLimitDeratingFac m149 : 56|7@1+ (0.01,0) [0|0] "" Vector__XXX
 SG_ PCS2_dcdcAHalfBusCompensationPiO m7 : 56|7@1- (1,0) [0|0] "" Vector__XXX
 SG_ PCS2_dcdcBHalfBusCompensationPiO m68 : 56|7@1- (1,0) [0|0] "" Vector__XXX
 SG_ PCS2_lite_buck_boost_cbc_leakybu m32 : 56|8@1+ (0.1,0) [0|0] "" Vector__XXX
 SG_ PCS2_pcs2_pwm_xbar_DCDCB_CO_0000 m35 : 56|1@1+ (1,0) [0|0] "" Vector__XXX
 SG_ PCS2_pcs2lite_pwm_xbar_DCDC_0000 m36 : 56|1@1+ (1,0) [0|0] "" Vector__XXX
 SG_ PCS2_pcsci_pwm_xbar_DCDCB_C_0000 m37 : 56|1@1+ (1,0) [0|0] "" Vector__XXX
 SG_ PCS2_phase_diff_pre_relay_L2N_L3 m141 : 56|8@1+ (1,0) [0|0] "" Vector__XXX
 SG_ PCS2_L2L3_pllLocked m133 : 55|1@1+ (1,0) [0|0] "" Vector__XXX
 SG_ PCS2_L3N_pllLocked m132 : 55|1@1+ (1,0) [0|0] "" Vector__XXX
 SG_ PCS2_dcdcB_hvTempIrrational m88 : 55|1@1+ (1,0) [0|0] "" Vector__XXX
 SG_ PCS2_lite_dcac_ac3TempIrrational m84 : 55|1@1+ (1,0) [0|0] "" Vector__XXX
 SG_ PCS2_pcs2_pwm_xbar_DCDCA_CO_0000 m35 : 55|1@1+ (1,0) [0|0] "" Vector__XXX
 SG_ PCS2_pcs2lite_pwm_xbar_DCAC_0000 m36 : 55|1@1+ (1,0) [0|0] "" Vector__XXX
 SG_ PCS2_L1L3_pllLocked m133 : 54|1@1+ (1,0) [0|0] "" Vector__XXX
 SG_ PCS2_L2N_pllLocked m132 : 54|1@1+ (1,0) [0|0] "" Vector__XXX
 SG_ PCS2_dcdcALvModelTemp m11 : 54|9@1- (1,106) [0|0] "" Vector__XXX
 SG_ PCS2_dcdcBLvModelTemp m72 : 54|9@1- (1,106) [0|0] "" Vector__XXX
 SG_ PCS2_lite_dcdc_hvTempIrrational m85 : 54|1@1+ (1,0) [0|0] "" Vector__XXX
 SG_ PCS2_pcs2_pwm_xbar_CYCLOB_C_0000 m35 : 54|1@1+ (1,0) [0|0] "" Vector__XXX
 SG_ PCS2_pcs2lite_pwm_xbar_BUCK_BOOS m36 : 54|1@1+ (1,0) [0|0] "" Vector__XXX
 SG_ PCS2_L1L2_pllLocked m133 : 53|1@1+ (1,0) [0|0] "" Vector__XXX
 SG_ PCS2_L1N_pllLocked m132 : 53|1@1+ (1,0) [0|0] "" Vector__XXX
 SG_ PCS2_cycloBBlockedReason m135 : 53|3@1+ (1,0) [0|0] "" Vector__XXX
 SG_ PCS2_dcOffsetL2L3Voltage m204 : 53|9@1- (4,0) [0|0] "" Vector__XXX
 SG_ PCS2_dcdc_CoolantOutTemp m81 : 53|11@1- (0.15,70.05) [0|0] "" Vector__XXX
 SG_ PCS2_pcs2_pwm_xbar_CYCLOA_C_0000 m35 : 53|1@1+ (1,0) [0|0] "" Vector__XXX
 SG_ PCS2_pcs2lite_pwm_xbar_CYCL_0000 m36 : 53|1@1+ (1,0) [0|0] "" Vector__XXX
 SG_ PCS2_cyclo_A_ln_device_temp m144 : 52|11@1+ (0.1,0) [0|0] "" Vector__XXX
 SG_ PCS2_cyclo_A_ln_device_temp_max m145 : 52|11@1+ (0.1,0) [0|0] "" Vector__XXX
 SG_ PCS2_cyclo_B_ln_device_temp m196 : 52|11@1+ (0.1,0) [0|0] "" Vector__XXX
 SG_ PCS2_cyclo_B_ln_device_temp_max m197 : 52|11@1+ (0.1,0) [0|0] "" Vector__XXX
 SG_ PCS2_mfgFuncTestIOXWriteRetry m14 : 52|10@1+ (1,0) [0|0] "" Vector__XXX
 SG_ PCS2_pcs2_pwm_xbar_LN_OC m35 : 52|1@1+ (1,0) [0|0] "" Vector__XXX
 SG_ PCS2_pcs2lite_pwm_xbar_LN_OC m36 : 52|1@1+ (1,0) [0|0] "" Vector__XXX
 SG_ PCS2_BuckBoostState m4 : 51|3@1+ (1,0) [0|0] "" Vector__XXX
 SG_ PCS2_dcdcAHvBottomVoltage m0 : 51|13@1+ (0.1,0) [0|0] "" Vector__XXX
 SG_ PCS2_dcdcBHvBottomVoltage m64 : 51|13@1+ (0.1,0) [0|0] "" Vector__XXX
 SG_ PCS2_dcdcLvVoltageMax_10s m66 : 51|13@1+ (0.01,0) [0|0] "" Vector__XXX
 SG_ PCS2_pcs2_pwm_xbar_L3N_CMPSS_OC m35 : 51|1@1+ (1,0) [0|0] "" Vector__XXX
 SG_ PCS2_pcs2lite_pwm_xbar_L3N_CMPSS m36 : 51|1@1+ (1,0) [0|0] "" Vector__XXX
 SG_ PCS2_cycloABlockedReason m135 : 50|3@1+ (1,0) [0|0] "" Vector__XXX
 SG_ PCS2_cycloA_tank_zcd_measur_0000 m156 : 50|14@1+ (0.1,150) [0|0] "" Vector__XXX
 SG_ PCS2_cycloB_tank_zcd_measur_0000 m203 : 50|14@1+ (0.1,150) [0|0] "" Vector__XXX
 SG_ PCS2_pcs2_pwm_xbar_L2N_CMPSS_OC m35 : 50|1@1+ (1,0) [0|0] "" Vector__XXX
 SG_ PCS2_pcs2lite_pwm_xbar_L2N_CMPSS m36 : 50|1@1+ (1,0) [0|0] "" Vector__XXX
 SG_ PCS2_dcdcALvCurrentEstimated m2 : 49|13@1- (0.1,0) [0|0] "" Vector__XXX
 SG_ PCS2_dcdcBLvCurrentEstimated m65 : 49|13@1- (0.1,0) [0|0] "" Vector__XXX
 SG_ PCS2_mfg_dcdcx_LUT_is_committed m13 : 49|1@1+ (1,0) [0|0] "" Vector__XXX
 SG_ PCS2_pcs2_pwm_xbar_CYCLOB_TANK_Z m35 : 49|1@1+ (1,0) [0|0] "" Vector__XXX
 SG_ PCS2_pcs2lite_pwm_xbar_CYCLOA_TA m36 : 49|1@1+ (1,0) [0|0] "" Vector__XXX
 SG_ PCS2_IONVMM_ServerState m4 : 48|3@1+ (1,0) [0|0] "" Vector__XXX
 SG_ PCS2_acGndNVrms m128 : 48|10@1+ (0.5,0) [0|0] "" Vector__XXX
 SG_ PCS2_acSurgeCurrentLimit m147 : 48|10@1+ (0.1,0) [0|0] "" Vector__XXX
 SG_ PCS2_bmsLimitDeratingFactor m148 : 48|7@1+ (0.01,0) [0|0] "" Vector__XXX
 SG_ PCS2_cycloATankMagInductance m137 : 48|15@1+ (0.1,0) [0|0] "" Vector__XXX
 SG_ PCS2_cycloBTankMagInductance m193 : 48|15@1+ (0.1,0) [0|0] "" Vector__XXX
 SG_ PCS2_cycloChargingCurrentCo_0001 m139 : 48|10@1+ (0.1,0) [0|0] "" Vector__XXX
 SG_ PCS2_dcdcAHalfBusCompensati_0000 m7 : 48|7@1- (1,0) [0|0] "" Vector__XXX
 SG_ PCS2_dcdcBHalfBusCompensati_0000 m68 : 48|7@1- (1,0) [0|0] "" Vector__XXX
 SG_ PCS2_hvToAcVoltageRatioDeratingF m149 : 48|7@1+ (0.01,0) [0|0] "" Vector__XXX
 SG_ PCS2_lite_BuckBoostInductance m38 : 48|10@1+ (0.05,0) [0|0] "" Vector__XXX
 SG_ PCS2_lite_buck_duty_max_10s m32 : 48|7@1+ (0.01,0) [0|0] "" Vector__XXX
 SG_ PCS2_mfgFuncTestIOXWrActual m15 : 48|16@1+ (1,0) [0|0] "" Vector__XXX
 SG_ PCS2_mfg_dc_tank_LUT_is_committe m13 : 48|1@1+ (1,0) [0|0] "" Vector__XXX
 SG_ PCS2_pcs2_pwm_xbar_L1N_CMPSS_OC m35 : 48|1@1+ (1,0) [0|0] "" Vector__XXX
 SG_ PCS2_pcs2lite_pwm_xbar_L1N_CMPSS m36 : 48|1@1+ (1,0) [0|0] "" Vector__XXX
 SG_ PCS2_phase_diff_pre_relay_L1N_L3 m141 : 48|8@1+ (1,0) [0|0] "" Vector__XXX
 SG_ PCS2_mfgFuncTestResult m12 : 47|14@1- (0.01,0) [0|0] "" Vector__XXX
 SG_ PCS2_mfg_ac_tank_LUT_is_committe m13 : 47|1@1+ (1,0) [0|0] "" Vector__XXX
 SG_ PCS2_pcs2_pwm_xbar_DCDCB_TANK_ZC m35 : 47|1@1+ (1,0) [0|0] "" Vector__XXX
 SG_ PCS2_mfg_ac_line_LUT_is_committe m13 : 46|1@1+ (1,0) [0|0] "" Vector__XXX
 SG_ PCS2_pcs2_pwm_xbar_DCDCB_I_TANK m35 : 46|1@1+ (1,0) [0|0] "" Vector__XXX
 SG_ PCS2_pcs2lite_pwm_xbar_DCDCB_I_T m36 : 46|1@1+ (1,0) [0|0] "" Vector__XXX
 SG_ PCS2_pcsci_pwm_xbar_DCDCB_I_TANK m37 : 46|1@1+ (1,0) [0|0] "" Vector__XXX
 SG_ PCS2_pcs2_pwm_xbar_DCDCA_I_TANK m35 : 45|1@1+ (1,0) [0|0] "" Vector__XXX
 SG_ PCS2_pcsci_pwm_xbar_CP_RESERVED m37 : 45|1@1+ (1,0) [0|0] "" Vector__XXX
 SG_ PCS2_acL3PreRelayChassisVrms m138 : 44|9@1+ (1,0) [0|0] "" Vector__XXX
 SG_ PCS2_acLNArms m130 : 44|12@1+ (0.1,0) [0|0] "" Vector__XXX
 SG_ PCS2_dcOffsetL1L3Voltage m204 : 44|9@1- (4,0) [0|0] "" Vector__XXX
 SG_ PCS2_dcdcB_hvTemp m88 : 44|11@1- (0.15,70.05) [0|0] "" Vector__XXX
 SG_ PCS2_lite_dcac_ac3Temp m84 : 44|11@1- (0.15,70.05) [0|0] "" Vector__XXX
 SG_ PCS2_pcs2_pwm_xbar_CYCLOB_I_TANK m35 : 44|1@1+ (1,0) [0|0] "" Vector__XXX
 SG_ PCS2_pcsci_pwm_xbar_CP_LATCH_OC m37 : 44|1@1+ (1,0) [0|0] "" Vector__XXX
 SG_ PCS2_coolantTemp m89 : 43|11@1- (0.15,70.05) [0|0] "" Vector__XXX
 SG_ PCS2_coolantTempMax_10s m82 : 43|11@1- (0.15,70.05) [0|0] "" Vector__XXX
 SG_ PCS2_coolantTempMin_10s m94 : 43|11@1- (0.15,70.05) [0|0] "" Vector__XXX
 SG_ PCS2_cycloAC_L3NPeakV m136 : 43|11@1+ (0.5,0) [0|0] "" Vector__XXX
 SG_ PCS2_cycloBLineTransientRetryCou m135 : 43|7@1+ (0.1,0) [0|0] "" Vector__XXX
 SG_ PCS2_dcacA_dcTempIrrational m86 : 43|1@1+ (1,0) [0|0] "" Vector__XXX
 SG_ PCS2_dcacB_dcTempIrrational m87 : 43|1@1+ (1,0) [0|0] "" Vector__XXX
 SG_ PCS2_dcdcA_hvTempIrrational m88 : 43|1@1+ (1,0) [0|0] "" Vector__XXX
 SG_ PCS2_dcdcB_hvTempMax_10s m80 : 43|11@1- (0.15,70.05) [0|0] "" Vector__XXX
 SG_ PCS2_dcdcB_hvTempMin_10s m79 : 43|11@1- (0.15,70.05) [0|0] "" Vector__XXX
 SG_ PCS2_lite_dcac_dcTempIrrational m84 : 43|1@1+ (1,0) [0|0] "" Vector__XXX
 SG_ PCS2_lite_dcdc_hvTemp m85 : 43|11@1- (0.15,70.05) [0|0] "" Vector__XXX
 SG_ PCS2_mfg_nvm_num_tables_in_last_ m13 : 43|3@1+ (1,0) [0|0] "" Vector__XXX
 SG_ PCS2_pcs2_pwm_xbar_CYCLOA_I_TANK m35 : 43|1@1+ (1,0) [0|0] "" Vector__XXX
 SG_ PCS2_pcs2lite_pwm_xbar_CYCLOA_I_ m36 : 43|1@1+ (1,0) [0|0] "" Vector__XXX
 SG_ PCS2_dcdcBlvuvSurgeLocked m74 : 42|1@1+ (1,0) [0|0] "" Vector__XXX
 SG_ PCS2_dcdc_CoolantInTemp m81 : 42|11@1- (0.15,70.05) [0|0] "" Vector__XXX
 SG_ PCS2_pcs2_pwm_xbar_ANY_LN_OV m35 : 42|1@1+ (1,0) [0|0] "" Vector__XXX
 SG_ PCS2_pcs2lite_pwm_xbar_ANY_LN_OV m36 : 42|1@1+ (1,0) [0|0] "" Vector__XXX
 SG_ PCS2_cyclo_A_l3_device_temp m144 : 41|11@1+ (0.1,0) [0|0] "" Vector__XXX
 SG_ PCS2_cyclo_A_l3_device_temp_max m145 : 41|11@1+ (0.1,0) [0|0] "" Vector__XXX
 SG_ PCS2_cyclo_B_l3_device_temp m196 : 41|11@1+ (0.1,0) [0|0] "" Vector__XXX
 SG_ PCS2_cyclo_B_l3_device_temp_max m197 : 41|11@1+ (0.1,0) [0|0] "" Vector__XXX
 SG_ PCS2_pcs2_pwm_xbar_DCDCB_COMBINE m35 : 41|1@1+ (1,0) [0|0] "" Vector__XXX
 SG_ PCS2_pcs2lite_pwm_xbar_DCDCB_COM m36 : 41|1@1+ (1,0) [0|0] "" Vector__XXX
 SG_ PCS2_pcsci_pwm_xbar_DCDCB_COMBIN m37 : 41|1@1+ (1,0) [0|0] "" Vector__XXX
 SG_ PCS2_48V0RailSenseMin10s m27 : 40|13@1+ (0.01,0) [0|0] "" Vector__XXX
 SG_ PCS2_48V0_18V0_CurrentSenseMin10 m28 : 40|13@1- (0.01,0) [0|0] "" Vector__XXX
 SG_ PCS2_acFrequencyL2L3 m133 : 40|13@1+ (0.01,0) [0|0] "" Vector__XXX
 SG_ PCS2_acFrequencyL3N m132 : 40|13@1+ (0.01,0) [0|0] "" Vector__XXX
 SG_ PCS2_canBusOffOccurrencePer10s m4 : 40|7@1+ (1,0) [0|0] "" Vector__XXX
 SG_ PCS2_cycloAInductorLossDeratingF m143 : 40|7@1+ (0.01,0) [0|0] "" Vector__XXX
 SG_ PCS2_cycloA_C_tank m142 : 40|10@1+ (0.1,50) [0|0] "" Vector__XXX
 SG_ PCS2_cycloBInductorLossDeratingF m195 : 40|7@1+ (0.01,0) [0|0] "" Vector__XXX
 SG_ PCS2_cycloB_C_tank m194 : 40|10@1+ (0.1,50) [0|0] "" Vector__XXX
 SG_ PCS2_dcdcAHvImpedanceEstState m9 : 40|3@1+ (1,0) [0|0] "" Vector__XXX
 SG_ PCS2_dcdcATankMagInductance m8 : 40|15@1+ (0.1,0) [0|0] "" Vector__XXX
 SG_ PCS2_dcdcATxWindingModelHvCurren m11 : 40|14@1- (0.01,0) [0|0] "" Vector__XXX
 SG_ PCS2_dcdcA_C_tank m6 : 40|10@1+ (0.05,15) [0|0] "" Vector__XXX
 SG_ PCS2_dcdcBHvImpedanceEstState m70 : 40|3@1+ (1,0) [0|0] "" Vector__XXX
 SG_ PCS2_dcdcBTankMagInductance m69 : 40|15@1+ (0.1,0) [0|0] "" Vector__XXX
 SG_ PCS2_dcdcBTankSelfTestState m74 : 40|2@1+ (1,0) [0|0] "" Vector__XXX
 SG_ PCS2_dcdcBTxWindingModelHvCurren m72 : 40|14@1- (0.01,0) [0|0] "" Vector__XXX
 SG_ PCS2_dcdcB_C_tank m67 : 40|10@1+ (0.05,15) [0|0] "" Vector__XXX
 SG_ PCS2_hvBusEstimatedImpedanceLoga m73 : 40|16@1+ (10,0) [0|0] "" Vector__XXX
 SG_ PCS2_lite_buck_duty_min_10s m32 : 40|7@1+ (0.01,0) [0|0] "" Vector__XXX
 SG_ PCS2_mfgFuncTestCalCtrlFreq2_MHz m14 : 40|12@1+ (0.001,0) [0|0] "" Vector__XXX
 SG_ PCS2_mfg_nvm_gdps_id_end m13 : 40|3@1+ (1,0) [0|0] "" Vector__XXX
 SG_ PCS2_pcs2_pwm_xbar_DCDCA_COMBINE m35 : 40|1@1+ (1,0) [0|0] "" Vector__XXX
 SG_ PCS2_pcs2lite_pwm_xbar_DCAC_GDPS m36 : 40|1@1+ (1,0) [0|0] "" Vector__XXX
 SG_ PCS2_phase_diff_pre_relay_L1N_L2 m141 : 40|8@1+ (1,0) [0|0] "" Vector__XXX
 SG_ PCS2_cycloBRetryCount m135 : 39|4@1+ (1,0) [0|0] "" Vector__XXX
 SG_ PCS2_dcdcAlvuvSurgeLocked m17 : 39|1@1+ (1,0) [0|0] "" Vector__XXX
 SG_ PCS2_pcs2_pwm_xbar_CYCLOB_COMBIN m35 : 39|1@1+ (1,0) [0|0] "" Vector__XXX
 SG_ PCS2_pcs2lite_pwm_xbar_TEMPSENSE m36 : 39|1@1+ (1,0) [0|0] "" Vector__XXX
 SG_ PCS2_pcsci_pwm_xbar_DATA_TEMPSEN m37 : 39|1@1+ (1,0) [0|0] "" Vector__XXX
 SG_ PCS2_acGndN m128 : 38|10@1- (1,0) [0|0] "" Vector__XXX
 SG_ PCS2_acLNContinuousCurrentLimit m149 : 38|10@1+ (0.1,0) [0|0] "" Vector__XXX
 SG_ PCS2_acLNGeneratedHeatI2TCpLimit m159 : 38|10@1+ (0.1,0) [0|0] "" Vector__XXX
 SG_ PCS2_acLNGeneratedHeatI2THwLimit m150 : 38|10@1+ (0.1,0) [0|0] "" Vector__XXX
 SG_ PCS2_acLNTransientCurrentLimit m147 : 38|10@1+ (0.1,0) [0|0] "" Vector__XXX
 SG_ PCS2_cycloChargingCurrentCo_0000 m139 : 38|10@1+ (0.1,0) [0|0] "" Vector__XXX
 SG_ PCS2_dcdcABursting m17 : 38|1@1+ (1,0) [0|0] "" Vector__XXX
 SG_ PCS2_dcdcAHalfBusBotVoltageMax_1 m7 : 38|10@1+ (1,0) [0|0] "" Vector__XXX
 SG_ PCS2_dcdcAHvTopVoltage m0 : 38|13@1+ (0.1,0) [0|0] "" Vector__XXX
 SG_ PCS2_dcdcBBursting m74 : 38|1@1+ (1,0) [0|0] "" Vector__XXX
 SG_ PCS2_dcdcBHalfBusBotVoltageMax_1 m68 : 38|10@1+ (1,0) [0|0] "" Vector__XXX
 SG_ PCS2_dcdcBHvTopVoltage m64 : 38|13@1+ (0.1,0) [0|0] "" Vector__XXX
 SG_ PCS2_dcdcLvVoltageMin_10s m66 : 38|13@1+ (0.01,0) [0|0] "" Vector__XXX
 SG_ PCS2_lite_BoostCurrentValleyMax1 m38 : 38|10@1+ (0.05,0) [0|0] "" Vector__XXX
 SG_ PCS2_pcs2_pwm_xbar_CYCLOA_COMBIN m35 : 38|1@1+ (1,0) [0|0] "" Vector__XXX
 SG_ PCS2_pcs2lite_pwm_xbar_CYCLOA_CO m36 : 38|1@1+ (1,0) [0|0] "" Vector__XXX
 SG_ PCS2_dcdcAPowerLimit m2 : 37|12@1+ (1,0) [0|0] "" Vector__XXX
 SG_ PCS2_dcdcBPowerLimit m65 : 37|12@1+ (1,0) [0|0] "" Vector__XXX
 SG_ PCS2_ipcCpu0ToCpu3TotalPeriodicL m18 : 37|9@1+ (1,0) [0|0] "" Vector__XXX
 SG_ PCS2_ipcCpu1ToCpu3TotalPeriodicL m75 : 37|9@1+ (1,0) [0|0] "" Vector__XXX
 SG_ PCS2_ipcCpu2ToCpu3TotalPeriodicL m154 : 37|9@1+ (1,0) [0|0] "" Vector__XXX
 SG_ PCS2_ipcCpu3ToCpu2TotalPeriodicL m200 : 37|9@1+ (1,0) [0|0] "" Vector__XXX
 SG_ PCS2_pcs2lite_pwm_xbar_DCDC_GDPS m36 : 37|1@1+ (1,0) [0|0] "" Vector__XXX
 SG_ PCS2_cycloA_tank_zcd_measured_fr m156 : 36|14@1+ (0.1,150) [0|0] "" Vector__XXX
 SG_ PCS2_cycloB_tank_zcd_measured_fr m203 : 36|14@1+ (0.1,150) [0|0] "" Vector__XXX
 SG_ PCS2_mfg_nvm_gdps_id_begin m13 : 36|3@1+ (1,0) [0|0] "" Vector__XXX
 SG_ PCS2_pcs2_pwm_xbar_CYCLOB_SECOND m35 : 36|1@1+ (1,0) [0|0] "" Vector__XXX
 SG_ PCS2_acL2PreRelayChassisVrms m138 : 35|9@1+ (1,0) [0|0] "" Vector__XXX
 SG_ PCS2_acLNCurrentLimitI2T m148 : 35|9@1+ (1,0) [0|0] "" Vector__XXX
 SG_ PCS2_cycloAC_NPeakCurrent m192 : 35|9@1+ (1,0) [0|0] "" Vector__XXX
 SG_ PCS2_cycloA_tank_zcd_half_p_0000 m155 : 35|9@1- (0.01,0) [0|0] "" Vector__XXX
 SG_ PCS2_cycloB_tank_zcd_half_p_0000 m202 : 35|9@1- (0.01,0) [0|0] "" Vector__XXX
 SG_ PCS2_dcOffsetL1L2Voltage m204 : 35|9@1- (4,0) [0|0] "" Vector__XXX
 SG_ PCS2_dcdcA_tank_zcd_half_pr_0000 m20 : 35|9@1- (0.01,0) [0|0] "" Vector__XXX
 SG_ PCS2_dcdcB_tank_zcd_half_pr_0000 m77 : 35|9@1- (0.01,0) [0|0] "" Vector__XXX
 SG_ PCS2_pcs2_pwm_xbar_CYCLOA_SECOND m35 : 35|1@1+ (1,0) [0|0] "" Vector__XXX
 SG_ PCS2_pcs2lite_pwm_xbar_CYCLOA_SE m36 : 35|1@1+ (1,0) [0|0] "" Vector__XXX
 SG_ PCS2_dcdcATransientPowerNotEnoug m19 : 34|1@1+ (1,0) [0|0] "" Vector__XXX
 SG_ PCS2_dcdcBTransientPowerNotEnoug m76 : 34|1@1+ (1,0) [0|0] "" Vector__XXX
 SG_ PCS2_pcs2_pwm_xbar_CYCLOA_TANK_Z m35 : 34|1@1+ (1,0) [0|0] "" Vector__XXX
 SG_ PCS2_dcdcACloseToPowerLimit m19 : 33|1@1+ (1,0) [0|0] "" Vector__XXX
 SG_ PCS2_dcdcBCloseToPowerLimit m76 : 33|1@1+ (1,0) [0|0] "" Vector__XXX
 SG_ PCS2_mfgFuncTestSwitchingFreq m12 : 33|14@1+ (0.1,150) [0|0] "" Vector__XXX
 SG_ PCS2_pcs2_pwm_xbar_ANY_LN_OC m35 : 33|1@1+ (1,0) [0|0] "" Vector__XXX
 SG_ PCS2_pcs2lite_pwm_xbar_ANY_LN_OC m36 : 33|1@1+ (1,0) [0|0] "" Vector__XXX
 SG_ PCS2_10V0RailSenseMin10s m24 : 32|12@1+ (0.01,0) [0|0] "" Vector__XXX
 SG_ PCS2_13V5RailSenseMin10s m29 : 32|12@1+ (0.01,0) [0|0] "" Vector__XXX
 SG_ PCS2_18V0RailSenseMin10s m16 : 32|12@1+ (0.01,0) [0|0] "" Vector__XXX
 SG_ PCS2_1V6RailSenseMin10s m26 : 32|12@1+ (0.01,0) [0|0] "" Vector__XXX
 SG_ PCS2_4V5RailSenseMin10s m25 : 32|12@1+ (0.01,0) [0|0] "" Vector__XXX
 SG_ PCS2_FC_N_VSense m31 : 32|12@1- (1,0) [0|0] "" Vector__XXX
 SG_ PCS2_acL3Arms m130 : 32|12@1+ (0.1,0) [0|0] "" Vector__XXX
 SG_ PCS2_ambientTemp m89 : 32|11@1- (0.15,70.05) [0|0] "" Vector__XXX
 SG_ PCS2_ambientTempMax_10s m82 : 32|11@1- (0.15,70.05) [0|0] "" Vector__XXX
 SG_ PCS2_ambientTempMin_10s m94 : 32|11@1- (0.15,70.05) [0|0] "" Vector__XXX
 SG_ PCS2_cabinAndBedL2L3LifetimekVAh m153 : 32|24@1+ (0.01,0) [0|0] "" Vector__XXX
 SG_ PCS2_cpGridFormLifetimekVAh m151 : 32|24@1+ (0.01,0) [0|0] "" Vector__XXX
 SG_ PCS2_cycloAC_L2L3PeakV m160 : 32|11@1+ (0.5,0) [0|0] "" Vector__XXX
 SG_ PCS2_cycloAC_L2NPeakV m136 : 32|11@1+ (0.5,0) [0|0] "" Vector__XXX
 SG_ PCS2_cycloAJunctionTempDeratingF m143 : 32|7@1+ (0.01,0) [0|0] "" Vector__XXX
 SG_ PCS2_cycloALineTransientRetryCou m135 : 32|7@1+ (0.1,0) [0|0] "" Vector__XXX
 SG_ PCS2_cycloATankCapacitance m137 : 32|10@1+ (0.1,50) [0|0] "" Vector__XXX
 SG_ PCS2_cycloBJunctionTempDeratingF m195 : 32|7@1+ (0.01,0) [0|0] "" Vector__XXX
 SG_ PCS2_cycloBTankCapacitance m193 : 32|10@1+ (0.1,50) [0|0] "" Vector__XXX
 SG_ PCS2_cyclo_A_hvdc_oc_count m146 : 32|8@1+ (1,0) [0|0] "" Vector__XXX
 SG_ PCS2_cyclo_B_hvdc_oc_count m198 : 32|8@1+ (1,0) [0|0] "" Vector__XXX
 SG_ PCS2_dcacA_dcTemp m86 : 32|11@1- (0.15,70.05) [0|0] "" Vector__XXX
 SG_ PCS2_dcacA_dcTempMax_10s m91 : 32|11@1- (0.15,70.05) [0|0] "" Vector__XXX
 SG_ PCS2_dcacA_dcTempMin_10s m90 : 32|11@1- (0.15,70.05) [0|0] "" Vector__XXX
 SG_ PCS2_dcacB_dcTemp m87 : 32|11@1- (0.15,70.05) [0|0] "" Vector__XXX
 SG_ PCS2_dcacB_dcTempMax_10s m93 : 32|11@1- (0.15,70.05) [0|0] "" Vector__XXX
 SG_ PCS2_dcacB_dcTempMin_10s m92 : 32|11@1- (0.15,70.05) [0|0] "" Vector__XXX
 SG_ PCS2_dcdcAVoltageErrorTooLarge m19 : 32|1@1+ (1,0) [0|0] "" Vector__XXX
 SG_ PCS2_dcdcA_hvTemp m88 : 32|11@1- (0.15,70.05) [0|0] "" Vector__XXX
 SG_ PCS2_dcdcA_hvTempMax_10s m80 : 32|11@1- (0.15,70.05) [0|0] "" Vector__XXX
 SG_ PCS2_dcdcA_hvTempMin_10s m79 : 32|11@1- (0.15,70.05) [0|0] "" Vector__XXX
 SG_ PCS2_dcdcBVoltageErrorTooLarge m76 : 32|1@1+ (1,0) [0|0] "" Vector__XXX
 SG_ PCS2_lite_buck_duty m32 : 32|7@1+ (0.01,0) [0|0] "" Vector__XXX
 SG_ PCS2_lite_dcac_dcTemp m84 : 32|11@1- (0.15,70.05) [0|0] "" Vector__XXX
 SG_ PCS2_lite_dcdc_LV_C_Temp m85 : 32|11@1- (0.15,70.05) [0|0] "" Vector__XXX
 SG_ PCS2_lite_lvBiasRailSenseMin10s m33 : 32|12@1+ (0.01,0) [0|0] "" Vector__XXX
 SG_ PCS2_mfgFuncTestCalPiReference2 m14 : 32|5@1+ (1,0) [0|0] "" Vector__XXX
 SG_ PCS2_mfgFuncTestIOXWrExpected m15 : 32|16@1+ (1,0) [0|0] "" Vector__XXX
 SG_ PCS2_pcs2_pwm_xbar_DCDCA_TANK_ZC m35 : 32|1@1+ (1,0) [0|0] "" Vector__XXX
 SG_ PCS2_pcs2lite_pwm_xbar_DCDCB_TAN m36 : 32|1@1+ (1,0) [0|0] "" Vector__XXX
 SG_ PCS2_pcsci_pwm_xbar_DCDCB_TANK_Z m37 : 32|1@1+ (1,0) [0|0] "" Vector__XXX
 SG_ PCS2_phase_diff_L1L3_L2L3 m141 : 32|8@1+ (1,0) [0|0] "" Vector__XXX
 SG_ PCS2_remoteFilteredCoolantTemp m4 : 32|8@1- (1,46) [0|0] "" Vector__XXX
 SG_ PCS2_totalOutletLifetimekVAh m152 : 32|24@1+ (0.01,0) [0|0] "" Vector__XXX
 SG_ PCS2_dcacA_ac2TempIrrational m86 : 31|1@1+ (1,0) [0|0] "" Vector__XXX
 SG_ PCS2_dcacB_ac2TempIrrational m87 : 31|1@1+ (1,0) [0|0] "" Vector__XXX
 SG_ PCS2_dcdcATankCapacitance m8 : 31|9@1+ (0.05,15) [0|0] "" Vector__XXX
 SG_ PCS2_dcdcATxWindingModelTemp m11 : 31|9@1- (1,106) [0|0] "" Vector__XXX
 SG_ PCS2_dcdcBTankCapacitance m69 : 31|9@1+ (0.05,15) [0|0] "" Vector__XXX
 SG_ PCS2_dcdcBTxWindingModelTemp m72 : 31|9@1- (1,106) [0|0] "" Vector__XXX
 SG_ PCS2_dcdcB_lv1TempIrrational m98 : 31|1@1+ (1,0) [0|0] "" Vector__XXX
 SG_ PCS2_dcdcB_lv2TempIrrational m88 : 31|1@1+ (1,0) [0|0] "" Vector__XXX
 SG_ PCS2_dcdc_LVLeftTemp m81 : 31|11@1- (0.15,70.05) [0|0] "" Vector__XXX
 SG_ PCS2_mfgFuncTestACTankMosfetCoun m12 : 31|2@1+ (1,0) [0|0] "" Vector__XXX
 SG_ PCS2_cyclo_A_l2_device_temp m144 : 30|11@1+ (0.1,0) [0|0] "" Vector__XXX
 SG_ PCS2_cyclo_A_l2_device_temp_max m145 : 30|11@1+ (0.1,0) [0|0] "" Vector__XXX
 SG_ PCS2_cyclo_B_l2_device_temp m196 : 30|11@1+ (0.1,0) [0|0] "" Vector__XXX
 SG_ PCS2_cyclo_B_l2_device_temp_max m197 : 30|11@1+ (0.1,0) [0|0] "" Vector__XXX
 SG_ PCS2_mfgFuncTestCalPiCtrlEnable2 m14 : 30|1@1+ (1,0) [0|0] "" Vector__XXX
 SG_ PCS2_acL2L3Vrms m129 : 28|10@1+ (0.5,0) [0|0] "" Vector__XXX
 SG_ PCS2_acL3ContinuousCurrentLimit m149 : 28|10@1+ (0.1,0) [0|0] "" Vector__XXX
 SG_ PCS2_acL3GeneratedHeatI2TCpLimit m159 : 28|10@1+ (0.1,0) [0|0] "" Vector__XXX
 SG_ PCS2_acL3GeneratedHeatI2THwLimit m150 : 28|10@1+ (0.1,0) [0|0] "" Vector__XXX
 SG_ PCS2_acL3NVrms m128 : 28|10@1+ (0.5,0) [0|0] "" Vector__XXX
 SG_ PCS2_acL3TransientCurrentLimit m147 : 28|10@1+ (0.1,0) [0|0] "" Vector__XXX
 SG_ PCS2_acRelayState m157 : 28|3@1+ (1,0) [0|0] "" Vector__XXX
 SG_ PCS2_cycloChargingCurrentCommand m139 : 28|10@1+ (0.1,0) [0|0] "" Vector__XXX
 SG_ PCS2_dcdcAHalfBusBotVoltageMin_1 m7 : 28|10@1+ (1,0) [0|0] "" Vector__XXX
 SG_ PCS2_dcdcBHalfBusBotVoltageMin_1 m68 : 28|10@1+ (1,0) [0|0] "" Vector__XXX
 SG_ PCS2_ipcCpu0ToCpu2TotalPeriodicL m18 : 28|9@1+ (1,0) [0|0] "" Vector__XXX
 SG_ PCS2_ipcCpu1ToCpu2TotalPeriodicL m75 : 28|9@1+ (1,0) [0|0] "" Vector__XXX
 SG_ PCS2_ipcCpu2ToCpu1TotalPeriodicL m154 : 28|9@1+ (1,0) [0|0] "" Vector__XXX
 SG_ PCS2_ipcCpu3ToCpu1TotalPeriodicL m200 : 28|9@1+ (1,0) [0|0] "" Vector__XXX
 SG_ PCS2_lite_BoostCurrentValley m38 : 28|10@1+ (0.05,0) [0|0] "" Vector__XXX
 SG_ PCS2_mfgFuncTestACLineMosfetCoun m12 : 28|3@1+ (1,0) [0|0] "" Vector__XXX
 SG_ PCS2_acL3ChassisVrms m138 : 26|9@1+ (1,0) [0|0] "" Vector__XXX
 SG_ PCS2_acL3CurrentLimitI2T m148 : 26|9@1+ (1,0) [0|0] "" Vector__XXX
 SG_ PCS2_cycloAC_L3PeakCurrent m192 : 26|9@1+ (1,0) [0|0] "" Vector__XXX
 SG_ PCS2_cycloA_tank_zcd_half_prd_me m155 : 26|9@1- (0.01,0) [0|0] "" Vector__XXX
 SG_ PCS2_cycloB_tank_zcd_half_prd_me m202 : 26|9@1- (0.01,0) [0|0] "" Vector__XXX
 SG_ PCS2_dcOffsetL3NVoltage m204 : 26|9@1- (4,0) [0|0] "" Vector__XXX
 SG_ PCS2_dcdcA_tank_zcd_half_prd_mea m20 : 26|9@1- (0.01,0) [0|0] "" Vector__XXX
 SG_ PCS2_dcdcB_tank_zcd_half_prd_mea m77 : 26|9@1- (0.01,0) [0|0] "" Vector__XXX
 SG_ PCS2_pcs2_pwm_xbar_time_index m35 : 26|6@1+ (1,0) [0|0] "" Vector__XXX
 SG_ PCS2_pcs2lite_pwm_xbar_time_inde m36 : 26|6@1+ (1,0) [0|0] "" Vector__XXX
 SG_ PCS2_pcsci_pwm_xbar_time_index m37 : 26|6@1+ (1,0) [0|0] "" Vector__XXX
 SG_ PCS2_L2L3LatchedExpectedWhileCha m140 : 25|1@1+ (1,0) [0|0] "" Vector__XXX
 SG_ PCS2_48V0RailSenseMax10s m27 : 24|13@1+ (0.01,0) [0|0] "" Vector__XXX
 SG_ PCS2_48V0_18V0_CurrentSenseMax10 m28 : 24|13@1- (0.01,0) [0|0] "" Vector__XXX
 SG_ PCS2_L1L3LatchedExpectedWhileCha m140 : 24|1@1+ (1,0) [0|0] "" Vector__XXX
 SG_ PCS2_acFrequencyL1L3 m133 : 24|13@1+ (0.01,0) [0|0] "" Vector__XXX
 SG_ PCS2_acFrequencyL2N m132 : 24|13@1+ (0.01,0) [0|0] "" Vector__XXX
 SG_ PCS2_cpu0Task1kHzUtilizationPerc m23 : 24|8@1+ (1,0) [0|0] "" Vector__XXX
 SG_ PCS2_cpu1Task1kHzUtilizationPerc m95 : 24|8@1+ (1,0) [0|0] "" Vector__XXX
 SG_ PCS2_cpu2Task1kHzUtilizationPerc m158 : 24|8@1+ (1,0) [0|0] "" Vector__XXX
 SG_ PCS2_cpu3Task1kHzUtilizationPerc m206 : 24|8@1+ (1,0) [0|0] "" Vector__XXX
 SG_ PCS2_cycloADcTempDeratingFactor m143 : 24|7@1+ (0.01,0) [0|0] "" Vector__XXX
 SG_ PCS2_cycloARetryCount m135 : 24|4@1+ (1,0) [0|0] "" Vector__XXX
 SG_ PCS2_cycloA_L_magnetizing m142 : 24|15@1+ (0.1,0) [0|0] "" Vector__XXX
 SG_ PCS2_cycloBDcTempDeratingFactor m195 : 24|7@1+ (0.01,0) [0|0] "" Vector__XXX
 SG_ PCS2_cycloB_L_magnetizing m194 : 24|15@1+ (0.1,0) [0|0] "" Vector__XXX
 SG_ PCS2_dcacHvBusCurrent m134 : 24|15@1- (0.01,0) [0|0] "" Vector__XXX
 SG_ PCS2_dcdcACmdSwitchingFreq_min_1 m21 : 24|14@1+ (0.1,150) [0|0] "" Vector__XXX
 SG_ PCS2_dcdcAHvVoltageFiltered m0 : 24|14@1+ (0.1,0) [0|0] "" Vector__XXX
 SG_ PCS2_dcdcAHvVoltageMax_10s m5 : 24|14@1+ (0.1,0) [0|0] "" Vector__XXX
 SG_ PCS2_dcdcAHvVoltageTarget m9 : 24|14@1+ (0.1,0) [0|0] "" Vector__XXX
 SG_ PCS2_dcdcALvCurrentCommand m2 : 24|13@1- (0.1,0) [0|0] "" Vector__XXX
 SG_ PCS2_dcdcAMinFaultDurationTicks m17 : 24|14@1+ (1,0) [0|0] "" Vector__XXX
 SG_ PCS2_dcdcA_L_magnetizing m6 : 24|15@1+ (0.1,0) [0|0] "" Vector__XXX
 SG_ PCS2_dcdcBCmdSwitchingFreq_min_1 m78 : 24|14@1+ (0.1,150) [0|0] "" Vector__XXX
 SG_ PCS2_dcdcBHvVoltageFiltered m64 : 24|14@1+ (0.1,0) [0|0] "" Vector__XXX
 SG_ PCS2_dcdcBHvVoltageMax_10s m66 : 24|14@1+ (0.1,0) [0|0] "" Vector__XXX
 SG_ PCS2_dcdcBHvVoltageTarget m70 : 24|14@1+ (0.1,0) [0|0] "" Vector__XXX
 SG_ PCS2_dcdcBLvCurrentCommand m65 : 24|13@1- (0.1,0) [0|0] "" Vector__XXX
 SG_ PCS2_dcdcBMinFaultDurationTicks m74 : 24|14@1+ (1,0) [0|0] "" Vector__XXX
 SG_ PCS2_dcdcB_L_magnetizing m67 : 24|15@1+ (0.1,0) [0|0] "" Vector__XXX
 SG_ PCS2_dcdcHvBusCurrent m83 : 24|15@1- (0.01,0) [0|0] "" Vector__XXX
 SG_ PCS2_hvBusEstimatedImpedanceLine m73 : 24|16@1+ (10,0) [0|0] "" Vector__XXX
 SG_ PCS2_lite_boost_duty_max_10s m32 : 24|7@1+ (0.01,0) [0|0] "" Vector__XXX
 SG_ PCS2_llcControllerFreqMHzMin10s m4 : 24|8@1+ (0.01,0) [0|0] "" Vector__XXX
 SG_ PCS2_mfgFuncTestCalCtrlFreq_MHz m13 : 24|12@1+ (0.001,0) [0|0] "" Vector__XXX
 SG_ PCS2_microgridHeartbeat2hzRms m201 : 24|8@1+ (0.001,0) [0|0] "" Vector__XXX
 SG_ PCS2_phase_diff_L2N_L3N m141 : 24|8@1+ (1,0) [0|0] "" Vector__XXX
 SG_ PCS2_L1L2LatchedExpectedWhileCha m140 : 23|1@1+ (1,0) [0|0] "" Vector__XXX
 SG_ PCS2_cycloBEnableRequest m135 : 23|1@1+ (1,0) [0|0] "" Vector__XXX
 SG_ PCS2_L3NLatchedExpectedWhileChar m140 : 22|1@1+ (1,0) [0|0] "" Vector__XXX
 SG_ PCS2_cycloACmdSwitchingFreq_min_ m156 : 22|14@1+ (0.1,150) [0|0] "" Vector__XXX
 SG_ PCS2_cycloAEnableRequest m135 : 22|1@1+ (1,0) [0|0] "" Vector__XXX
 SG_ PCS2_cycloBCmdSwitchingFreq_min_ m203 : 22|14@1+ (0.1,150) [0|0] "" Vector__XXX
 SG_ PCS2_L2NLatchedExpectedWhileChar m140 : 21|1@1+ (1,0) [0|0] "" Vector__XXX
 SG_ PCS2_10V0RailSenseMax10s m24 : 20|12@1+ (0.01,0) [0|0] "" Vector__XXX
 SG_ PCS2_13V5RailSenseMax10s m29 : 20|12@1+ (0.01,0) [0|0] "" Vector__XXX
 SG_ PCS2_18V0RailSenseMax10s m16 : 20|12@1+ (0.01,0) [0|0] "" Vector__XXX
 SG_ PCS2_1V6RailSenseMax10s m26 : 20|12@1+ (0.01,0) [0|0] "" Vector__XXX
 SG_ PCS2_4V5RailSenseMax10s m25 : 20|12@1+ (0.01,0) [0|0] "" Vector__XXX
 SG_ PCS2_FC_P_VSense m31 : 20|12@1- (1,0) [0|0] "" Vector__XXX
 SG_ PCS2_L1NLatchedExpectedWhileChar m140 : 20|1@1+ (1,0) [0|0] "" Vector__XXX
 SG_ PCS2_acL2Arms m130 : 20|12@1+ (0.1,0) [0|0] "" Vector__XXX
 SG_ PCS2_cycloATankLeakInductance m137 : 20|11@1+ (0.1,0) [0|0] "" Vector__XXX
 SG_ PCS2_cycloBTankLeakInductance m193 : 20|11@1+ (0.1,0) [0|0] "" Vector__XXX
 SG_ PCS2_dcacA_ac2Temp m86 : 20|11@1- (0.15,70.05) [0|0] "" Vector__XXX
 SG_ PCS2_dcacB_ac2Temp m87 : 20|11@1- (0.15,70.05) [0|0] "" Vector__XXX
 SG_ PCS2_dcdcASmDischargeRetryCnt m17 : 20|4@1+ (1,0) [0|0] "" Vector__XXX
 SG_ PCS2_dcdcATankLeakInductance m8 : 20|11@1+ (0.1,0) [0|0] "" Vector__XXX
 SG_ PCS2_dcdcBSmDischargeRetryCnt m74 : 20|4@1+ (1,0) [0|0] "" Vector__XXX
 SG_ PCS2_dcdcBTankLeakInductance m69 : 20|11@1+ (0.1,0) [0|0] "" Vector__XXX
 SG_ PCS2_dcdcB_lv1Temp m98 : 20|11@1- (0.15,70.05) [0|0] "" Vector__XXX
 SG_ PCS2_dcdcB_lv2Temp m88 : 20|11@1- (0.15,70.05) [0|0] "" Vector__XXX
 SG_ PCS2_dcdc_LVRightTemp m81 : 20|11@1- (0.15,70.05) [0|0] "" Vector__XXX
 SG_ PCS2_lite_lvBiasRailSenseMax10s m33 : 20|12@1+ (0.01,0) [0|0] "" Vector__XXX
 SG_ PCS2_L2L3ExpectedWhileCharging m140 : 19|1@1+ (1,0) [0|0] "" Vector__XXX
 SG_ PCS2_cycloAC_L1L3PeakV m160 : 19|11@1+ (0.5,0) [0|0] "" Vector__XXX
 SG_ PCS2_cycloAC_L1NPeakV m136 : 19|11@1+ (0.5,0) [0|0] "" Vector__XXX
 SG_ PCS2_cycloBStageStateMachineStat m135 : 19|3@1+ (1,0) [0|0] "" Vector__XXX
 SG_ PCS2_cyclo_A_l1_device_temp m144 : 19|11@1+ (0.1,0) [0|0] "" Vector__XXX
 SG_ PCS2_cyclo_A_l1_device_temp_max m145 : 19|11@1+ (0.1,0) [0|0] "" Vector__XXX
 SG_ PCS2_cyclo_B_l1_device_temp m196 : 19|11@1+ (0.1,0) [0|0] "" Vector__XXX
 SG_ PCS2_cyclo_B_l1_device_temp_max m197 : 19|11@1+ (0.1,0) [0|0] "" Vector__XXX
 SG_ PCS2_dcacA_ac1TempIrrational m86 : 19|1@1+ (1,0) [0|0] "" Vector__XXX
 SG_ PCS2_dcacA_ac2TempMax_10s m91 : 19|11@1- (0.15,70.05) [0|0] "" Vector__XXX
 SG_ PCS2_dcacA_ac2TempMin_10s m90 : 19|11@1- (0.15,70.05) [0|0] "" Vector__XXX
 SG_ PCS2_dcacB_ac1TempIrrational m87 : 19|1@1+ (1,0) [0|0] "" Vector__XXX
 SG_ PCS2_dcacB_ac2TempMax_10s m93 : 19|11@1- (0.15,70.05) [0|0] "" Vector__XXX
 SG_ PCS2_dcacB_ac2TempMin_10s m92 : 19|11@1- (0.15,70.05) [0|0] "" Vector__XXX
 SG_ PCS2_dcacB_transformerTemp m89 : 19|11@1- (0.15,70.05) [0|0] "" Vector__XXX
 SG_ PCS2_dcacB_transformerTempMax_10 m82 : 19|11@1- (0.15,70.05) [0|0] "" Vector__XXX
 SG_ PCS2_dcacB_transformerTempMin_10 m94 : 19|11@1- (0.15,70.05) [0|0] "" Vector__XXX
 SG_ PCS2_dcdcA_lv1TempIrrational m98 : 19|1@1+ (1,0) [0|0] "" Vector__XXX
 SG_ PCS2_dcdcA_lv2TempIrrational m88 : 19|1@1+ (1,0) [0|0] "" Vector__XXX
 SG_ PCS2_dcdcB_lv2TempMax_10s m80 : 19|11@1- (0.15,70.05) [0|0] "" Vector__XXX
 SG_ PCS2_dcdcB_lv2TempMin_10s m79 : 19|11@1- (0.15,70.05) [0|0] "" Vector__XXX
 SG_ PCS2_dcdc_hvTempIrrational m81 : 19|1@1+ (1,0) [0|0] "" Vector__XXX
 SG_ PCS2_ipcCpu0ToCpu1TotalPeriodicL m18 : 19|9@1+ (1,0) [0|0] "" Vector__XXX
 SG_ PCS2_ipcCpu1ToCpu0TotalPeriodicL m75 : 19|9@1+ (1,0) [0|0] "" Vector__XXX
 SG_ PCS2_ipcCpu2ToCpu0TotalPeriodicL m154 : 19|9@1+ (1,0) [0|0] "" Vector__XXX
 SG_ PCS2_ipcCpu3ToCpu0TotalPeriodicL m200 : 19|9@1+ (1,0) [0|0] "" Vector__XXX
 SG_ PCS2_lite_coolantOutTemp m84 : 19|11@1- (0.15,70.05) [0|0] "" Vector__XXX
 SG_ PCS2_lite_dcdc_LV_B_Temp m85 : 19|11@1- (0.15,70.05) [0|0] "" Vector__XXX
 SG_ PCS2_L1L3ExpectedWhileCharging m140 : 18|1@1+ (1,0) [0|0] "" Vector__XXX
 SG_ PCS2_acL1L3Vrms m129 : 18|10@1+ (0.5,0) [0|0] "" Vector__XXX
 SG_ PCS2_acL2ContinuousCurrentLimit m149 : 18|10@1+ (0.1,0) [0|0] "" Vector__XXX
 SG_ PCS2_acL2GeneratedHeatI2TCpLimit m159 : 18|10@1+ (0.1,0) [0|0] "" Vector__XXX
 SG_ PCS2_acL2GeneratedHeatI2THwLimit m150 : 18|10@1+ (0.1,0) [0|0] "" Vector__XXX
 SG_ PCS2_acL2NVrms m128 : 18|10@1+ (0.5,0) [0|0] "" Vector__XXX
 SG_ PCS2_acL2TransientCurrentLimit m147 : 18|10@1+ (0.1,0) [0|0] "" Vector__XXX
 SG_ PCS2_acL3NPreRelayVrms m157 : 18|10@1+ (0.5,0) [0|0] "" Vector__XXX
 SG_ PCS2_aggregatedWithUserChargingC m139 : 18|10@1+ (0.1,0) [0|0] "" Vector__XXX
 SG_ PCS2_cycloXcapHealthCheckStatus m22 : 18|2@1+ (1,0) [0|0] "" Vector__XXX
 SG_ PCS2_dcdcAHalfBusTopVoltageMax_1 m7 : 18|10@1+ (1,0) [0|0] "" Vector__XXX
 SG_ PCS2_dcdcBHalfBusTopVoltageMax_1 m68 : 18|10@1+ (1,0) [0|0] "" Vector__XXX
 SG_ PCS2_dcdcBStageModeRequest m1 : 18|2@1+ (1,0) [0|0] "" Vector__XXX
 SG_ PCS2_lite_BoostCurrentPeakMax10s m38 : 18|10@1+ (0.05,0) [0|0] "" Vector__XXX
 SG_ PCS2_mfgFuncTestID m12 : 18|10@1+ (1,0) [0|0] "" Vector__XXX
 SG_ PCS2_mfgFuncTestIOXWrRetryHWM m15 : 18|10@1+ (1,0) [0|0] "" Vector__XXX
 SG_ PCS2_L1L2ExpectedWhileCharging m140 : 17|1@1+ (1,0) [0|0] "" Vector__XXX
 SG_ PCS2_acL2ChassisVrms m138 : 17|9@1+ (1,0) [0|0] "" Vector__XXX
 SG_ PCS2_acL2CurrentLimitI2T m148 : 17|9@1+ (1,0) [0|0] "" Vector__XXX
 SG_ PCS2_cycloAC_L2PeakCurrent m192 : 17|9@1+ (1,0) [0|0] "" Vector__XXX
 SG_ PCS2_cycloA_tank_zcd_event_pu_mi m155 : 17|9@1- (0.01,0) [0|0] "" Vector__XXX
 SG_ PCS2_cycloB_tank_zcd_event_pu_mi m202 : 17|9@1- (0.01,0) [0|0] "" Vector__XXX
 SG_ PCS2_dcOffsetL2NVoltage m204 : 17|9@1- (4,0) [0|0] "" Vector__XXX
 SG_ PCS2_dcOffsetL3NPreRelayVoltage m205 : 17|9@1- (4,0) [0|0] "" Vector__XXX
 SG_ PCS2_dcdcALvMosfetModelHvCurrent m11 : 17|14@1- (0.01,0) [0|0] "" Vector__XXX
 SG_ PCS2_dcdcA_tank_zcd_event_pu_min m20 : 17|9@1- (0.01,0) [0|0] "" Vector__XXX
 SG_ PCS2_dcdcBHvMosfetModelHvCurrent m96 : 17|14@1- (0.01,0) [0|0] "" Vector__XXX
 SG_ PCS2_dcdcBLvMosfetModelHvCurrent m72 : 17|14@1- (0.01,0) [0|0] "" Vector__XXX
 SG_ PCS2_dcdcB_tank_zcd_event_pu_min m77 : 17|9@1- (0.01,0) [0|0] "" Vector__XXX
 SG_ PCS2_L3NExpectedWhileCharging m140 : 16|1@1+ (1,0) [0|0] "" Vector__XXX
 SG_ PCS2_cpu0Task5kHzUtilizationPerc m23 : 16|8@1+ (1,0) [0|0] "" Vector__XXX
 SG_ PCS2_cpu1Task5kHzUtilizationPerc m95 : 16|8@1+ (1,0) [0|0] "" Vector__XXX
 SG_ PCS2_cpu2Task5kHzUtilizationPerc m158 : 16|8@1+ (1,0) [0|0] "" Vector__XXX
 SG_ PCS2_cpu3Task5kHzUtilizationPerc m206 : 16|8@1+ (1,0) [0|0] "" Vector__XXX
 SG_ PCS2_cycloAStageStateMachineStat m135 : 16|3@1+ (1,0) [0|0] "" Vector__XXX
 SG_ PCS2_cycloATxTempDeratingFactor m143 : 16|7@1+ (0.01,0) [0|0] "" Vector__XXX
 SG_ PCS2_cycloBMosfetHealthCheckStat m22 : 16|2@1+ (1,0) [0|0] "" Vector__XXX
 SG_ PCS2_cycloBTxTempDeratingFactor m195 : 16|7@1+ (0.01,0) [0|0] "" Vector__XXX
 SG_ PCS2_dcdcADeltaEnergy m19 : 16|16@1+ (1,0) [0|0] "" Vector__XXX
 SG_ PCS2_dcdcASmPrechargeRetryCnt m17 : 16|4@1+ (1,0) [0|0] "" Vector__XXX
 SG_ PCS2_dcdcAStageModeRequest m1 : 16|2@1+ (1,0) [0|0] "" Vector__XXX
 SG_ PCS2_dcdcBDeltaEnergy m76 : 16|16@1+ (1,0) [0|0] "" Vector__XXX
 SG_ PCS2_dcdcBSmPrechargeRetryCnt m74 : 16|4@1+ (1,0) [0|0] "" Vector__XXX
 SG_ PCS2_gridFrequency m131 : 16|13@1+ (0.01,0) [0|0] "" Vector__XXX
 SG_ PCS2_ipcCpu0ToCpu3MaxSuccessiveL m18 : 16|3@1+ (1,0) [0|0] "" Vector__XXX
 SG_ PCS2_ipcCpu1ToCpu3MaxSuccessiveL m75 : 16|3@1+ (1,0) [0|0] "" Vector__XXX
 SG_ PCS2_ipcCpu2ToCpu3MaxSuccessiveL m154 : 16|3@1+ (1,0) [0|0] "" Vector__XXX
 SG_ PCS2_ipcCpu3ToCpu2MaxSuccessiveL m200 : 16|3@1+ (1,0) [0|0] "" Vector__XXX
 SG_ PCS2_lite_boost_duty_min_10s m32 : 16|7@1+ (0.01,0) [0|0] "" Vector__XXX
 SG_ PCS2_llcControllerFreqMHzMax10s m4 : 16|8@1+ (0.01,0) [0|0] "" Vector__XXX
 SG_ PCS2_mfgFuncTestCalPiReference m13 : 16|5@1+ (1,0) [0|0] "" Vector__XXX
 SG_ PCS2_mfgFuncTestResult2 m14 : 16|14@1- (0.01,0) [0|0] "" Vector__XXX
 SG_ PCS2_microgridHeartbeat1hzRms m201 : 16|8@1+ (0.001,0) [0|0] "" Vector__XXX
 SG_ PCS2_phase_diff_L1N_L3N m141 : 16|8@1+ (1,0) [0|0] "" Vector__XXX
 SG_ PCS2_L2NExpectedWhileCharging m140 : 15|1@1+ (1,0) [0|0] "" Vector__XXX
 SG_ PCS2_L1NExpectedWhileCharging m140 : 14|1@1+ (1,0) [0|0] "" Vector__XXX
 SG_ PCS2_cycloAMosfetHealthCheckStat m22 : 14|2@1+ (1,0) [0|0] "" Vector__XXX
 SG_ PCS2_cycloNumWire m131 : 14|2@1+ (1,0) [0|0] "" Vector__XXX
 SG_ PCS2_L2L3AvailableForCharging m140 : 13|1@1+ (1,0) [0|0] "" Vector__XXX
 SG_ PCS2_L1L3AvailableForCharging m140 : 12|1@1+ (1,0) [0|0] "" Vector__XXX
 SG_ PCS2_cycloBGdpsHealthCheckStatus m22 : 12|2@1+ (1,0) [0|0] "" Vector__XXX
 SG_ PCS2_dcdcBStateMachineState m1 : 12|3@1+ (1,0) [0|0] "" Vector__XXX
 SG_ PCS2_gridFormStateMachineState m135 : 12|3@1+ (1,0) [0|0] "" Vector__XXX
 SG_ PCS2_mfgFuncTestBlockID m12 : 12|6@1+ (1,0) [0|0] "" Vector__XXX
 SG_ PCS2_mfgFuncTestCalIterativeCtrl m14 : 12|1@1+ (1,0) [0|0] "" Vector__XXX
 SG_ PCS2_mfgFuncTestCalPiCtrlEnable m13 : 12|1@1+ (1,0) [0|0] "" Vector__XXX
 SG_ PCS2_L1L2AvailableForCharging m140 : 11|1@1+ (1,0) [0|0] "" Vector__XXX
 SG_ PCS2_dcdcASmLvRegulationRetryCnt m17 : 11|4@1+ (1,0) [0|0] "" Vector__XXX
 SG_ PCS2_dcdcBSmLvRegulationRetryCnt m74 : 11|4@1+ (1,0) [0|0] "" Vector__XXX
 SG_ PCS2_ipcCpu0ToCpu2MaxSuccessiveL m18 : 11|3@1+ (1,0) [0|0] "" Vector__XXX
 SG_ PCS2_ipcCpu1ToCpu2MaxSuccessiveL m75 : 11|3@1+ (1,0) [0|0] "" Vector__XXX
 SG_ PCS2_ipcCpu2ToCpu1MaxSuccessiveL m154 : 11|3@1+ (1,0) [0|0] "" Vector__XXX
 SG_ PCS2_ipcCpu3ToCpu1MaxSuccessiveL m200 : 11|3@1+ (1,0) [0|0] "" Vector__XXX
 SG_ PCS2_latchedInternalPhaseConfig m131 : 11|3@1+ (1,0) [0|0] "" Vector__XXX
 SG_ PCS2_mfgFuncTestImpedanceMeasEna m13 : 11|1@1+ (1,0) [0|0] "" Vector__XXX
 SG_ PCS2_L3NAvailableForCharging m140 : 10|1@1+ (1,0) [0|0] "" Vector__XXX
 SG_ PCS2_cutloopStatus m34 : 10|2@1+ (1,0) [0|0] "" Vector__XXX
 SG_ PCS2_cycloAGdpsHealthCheckStatus m22 : 10|2@1+ (1,0) [0|0] "" Vector__XXX
 SG_ PCS2_L2NAvailableForCharging m140 : 9|1@1+ (1,0) [0|0] "" Vector__XXX
 SG_ PCS2_dcdcAStateMachineState m1 : 9|3@1+ (1,0) [0|0] "" Vector__XXX
 SG_ PCS2_hvcEfuseState m34 : 9|1@1+ (1,0) [0|0] "" Vector__XXX
 SG_ PCS2_10V0RailSense m24 : 8|12@1+ (0.01,0) [0|0] "" Vector__XXX
 SG_ PCS2_13V5RailSense m29 : 8|12@1+ (0.01,0) [0|0] "" Vector__XXX
 SG_ PCS2_18V0RailSense m16 : 8|12@1+ (0.01,0) [0|0] "" Vector__XXX
 SG_ PCS2_1V6RailSense m26 : 8|12@1+ (0.01,0) [0|0] "" Vector__XXX
 SG_ PCS2_2V5Ref_V m30 : 8|12@1+ (0.01,0) [0|0] "" Vector__XXX
 SG_ PCS2_48V0RailSense m27 : 8|13@1+ (0.01,0) [0|0] "" Vector__XXX
 SG_ PCS2_48V0_18V0_CurrentSense m28 : 8|13@1- (0.01,0) [0|0] "" Vector__XXX
 SG_ PCS2_4V5RailSense m25 : 8|12@1+ (0.01,0) [0|0] "" Vector__XXX
 SG_ PCS2_FC_VSense m31 : 8|12@1- (1,0) [0|0] "" Vector__XXX
 SG_ PCS2_L1NAvailableForCharging m140 : 8|1@1+ (1,0) [0|0] "" Vector__XXX
 SG_ PCS2_acChargeLifetimekVAh m151 : 8|24@1+ (0.01,0) [0|0] "" Vector__XXX
 SG_ PCS2_acFrequencyL1L2 m133 : 8|13@1+ (0.01,0) [0|0] "" Vector__XXX
 SG_ PCS2_acFrequencyL1N m132 : 8|13@1+ (0.01,0) [0|0] "" Vector__XXX
 SG_ PCS2_acL1Arms m130 : 8|12@1+ (0.1,0) [0|0] "" Vector__XXX
 SG_ PCS2_acL1ChassisVrms m138 : 8|9@1+ (1,0) [0|0] "" Vector__XXX
 SG_ PCS2_acL1ContinuousCurrentLimit m149 : 8|10@1+ (0.1,0) [0|0] "" Vector__XXX
 SG_ PCS2_acL1CurrentLimitI2T m148 : 8|9@1+ (1,0) [0|0] "" Vector__XXX
 SG_ PCS2_acL1GeneratedHeatI2TCpLimit m159 : 8|10@1+ (0.1,0) [0|0] "" Vector__XXX
 SG_ PCS2_acL1GeneratedHeatI2THwLimit m150 : 8|10@1+ (0.1,0) [0|0] "" Vector__XXX
 SG_ PCS2_acL1L2Vrms m129 : 8|10@1+ (0.5,0) [0|0] "" Vector__XXX
 SG_ PCS2_acL1NVrms m128 : 8|10@1+ (0.5,0) [0|0] "" Vector__XXX
 SG_ PCS2_acL1TransientCurrentLimit m147 : 8|10@1+ (0.1,0) [0|0] "" Vector__XXX
 SG_ PCS2_acL2NPreRelayVrms m157 : 8|10@1+ (0.5,0) [0|0] "" Vector__XXX
 SG_ PCS2_aggregatedChargingCurrentLi m139 : 8|10@1+ (0.1,0) [0|0] "" Vector__XXX
 SG_ PCS2_cabinAndBedL1L2LifetimekVAh m153 : 8|24@1+ (0.01,0) [0|0] "" Vector__XXX
 SG_ PCS2_cabinOnlyL2L3LifetimekVAh m152 : 8|24@1+ (0.01,0) [0|0] "" Vector__XXX
 SG_ PCS2_chgMainStateMachineState m135 : 8|4@1+ (1,0) [0|0] "" Vector__XXX
 SG_ PCS2_cpu0IsrUtilizationPercentag m23 : 8|8@1+ (1,0) [0|0] "" Vector__XXX
 SG_ PCS2_cpu1IsrUtilizationPercentag m95 : 8|8@1+ (1,0) [0|0] "" Vector__XXX
 SG_ PCS2_cpu2IsrUtilizationPercentag m158 : 8|8@1+ (1,0) [0|0] "" Vector__XXX
 SG_ PCS2_cpu3IsrUtilizationPercentag m206 : 8|8@1+ (1,0) [0|0] "" Vector__XXX
 SG_ PCS2_cycloAC_L1L2PeakV m160 : 8|11@1+ (0.5,0) [0|0] "" Vector__XXX
 SG_ PCS2_cycloAC_L1PeakCurrent m192 : 8|9@1+ (1,0) [0|0] "" Vector__XXX
 SG_ PCS2_cycloAC_chassisNPeakV m136 : 8|11@1+ (0.5,0) [0|0] "" Vector__XXX
 SG_ PCS2_cycloACmdSwitchingFreq_max_ m156 : 8|14@1+ (0.1,150) [0|0] "" Vector__XXX
 SG_ PCS2_cycloASurgeCombinedDerating m143 : 8|7@1+ (0.01,0) [0|0] "" Vector__XXX
 SG_ PCS2_cycloATankLeakFreq m137 : 8|12@1+ (0.1,0) [0|0] "" Vector__XXX
 SG_ PCS2_cycloA_L_tank m142 : 8|11@1+ (0.1,0) [0|0] "" Vector__XXX
 SG_ PCS2_cycloA_tank_zcd_event_pu_ma m155 : 8|9@1- (0.01,0) [0|0] "" Vector__XXX
 SG_ PCS2_cycloBCmdSwitchingFreq_max_ m203 : 8|14@1+ (0.1,150) [0|0] "" Vector__XXX
 SG_ PCS2_cycloBSurgeCombinedDerating m195 : 8|7@1+ (0.01,0) [0|0] "" Vector__XXX
 SG_ PCS2_cycloBTankLeakFreq m193 : 8|12@1+ (0.1,0) [0|0] "" Vector__XXX
 SG_ PCS2_cycloB_L_tank m194 : 8|11@1+ (0.1,0) [0|0] "" Vector__XXX
 SG_ PCS2_cycloB_tank_zcd_event_pu_ma m202 : 8|9@1- (0.01,0) [0|0] "" Vector__XXX
 SG_ PCS2_cyclo_A_hv_device_temp m144 : 8|11@1+ (0.1,0) [0|0] "" Vector__XXX
 SG_ PCS2_cyclo_A_hv_device_temp_max m145 : 8|11@1+ (0.1,0) [0|0] "" Vector__XXX
 SG_ PCS2_cyclo_A_i_tank_loss m146 : 8|17@1+ (1000000000000,0) [0|0] "" Vector__XXX
 SG_ PCS2_cyclo_B_hv_device_temp m196 : 8|11@1+ (0.1,0) [0|0] "" Vector__XXX
 SG_ PCS2_cyclo_B_hv_device_temp_max m197 : 8|11@1+ (0.1,0) [0|0] "" Vector__XXX
 SG_ PCS2_cyclo_B_i_tank_loss m198 : 8|17@1+ (1000000000000,0) [0|0] "" Vector__XXX
 SG_ PCS2_dcOffsetL1NVoltage m204 : 8|9@1- (4,0) [0|0] "" Vector__XXX
 SG_ PCS2_dcOffsetL2NPreRelayVoltage m205 : 8|9@1- (4,0) [0|0] "" Vector__XXX
 SG_ PCS2_dcacA_ac1Temp m86 : 8|11@1- (0.15,70.05) [0|0] "" Vector__XXX
 SG_ PCS2_dcacA_ac1TempMax_10s m91 : 8|11@1- (0.15,70.05) [0|0] "" Vector__XXX
 SG_ PCS2_dcacA_ac1TempMin_10s m90 : 8|11@1- (0.15,70.05) [0|0] "" Vector__XXX
 SG_ PCS2_dcacA_transformerTemp m89 : 8|11@1- (0.15,70.05) [0|0] "" Vector__XXX
 SG_ PCS2_dcacA_transformerTempMax_10 m82 : 8|11@1- (0.15,70.05) [0|0] "" Vector__XXX
 SG_ PCS2_dcacA_transformerTempMin_10 m94 : 8|11@1- (0.15,70.05) [0|0] "" Vector__XXX
 SG_ PCS2_dcacB_ac1Temp m87 : 8|11@1- (0.15,70.05) [0|0] "" Vector__XXX
 SG_ PCS2_dcacB_ac1TempMax_10s m93 : 8|11@1- (0.15,70.05) [0|0] "" Vector__XXX
 SG_ PCS2_dcacB_ac1TempMin_10s m92 : 8|11@1- (0.15,70.05) [0|0] "" Vector__XXX
 SG_ PCS2_dcacHvBusVoltage m134 : 8|14@1+ (0.1,0) [0|0] "" Vector__XXX
 SG_ PCS2_dcdcACmdSwitchingFreq_max_1 m21 : 8|14@1+ (0.1,150) [0|0] "" Vector__XXX
 SG_ PCS2_dcdcAHalfBusTopVoltageMin_1 m7 : 8|10@1+ (1,0) [0|0] "" Vector__XXX
 SG_ PCS2_dcdcAHvCurrentCommand m2 : 8|13@1- (0.01,0) [0|0] "" Vector__XXX
 SG_ PCS2_dcdcAHvVoltage m0 : 8|14@1+ (0.1,0) [0|0] "" Vector__XXX
 SG_ PCS2_dcdcAHvVoltageMin_10s m5 : 8|14@1+ (0.1,0) [0|0] "" Vector__XXX
 SG_ PCS2_dcdcALifetimekWh m10 : 8|24@1+ (0.01,0) [0|0] "" Vector__XXX
 SG_ PCS2_dcdcALvMosfetModelTemp m11 : 8|9@1- (1,106) [0|0] "" Vector__XXX
 SG_ PCS2_dcdcALvVoltageTarget m9 : 8|13@1+ (0.01,0) [0|0] "" Vector__XXX
 SG_ PCS2_dcdcAPWMBlockedByArbitratio m19 : 8|1@1+ (1,0) [0|0] "" Vector__XXX
 SG_ PCS2_dcdcAStageManagerRetryCount m17 : 8|3@1+ (1,0) [0|0] "" Vector__XXX
 SG_ PCS2_dcdcATankLeakFreq m8 : 8|12@1+ (0.1,0) [0|0] "" Vector__XXX
 SG_ PCS2_dcdcA_L_tank m6 : 8|11@1+ (0.1,0) [0|0] "" Vector__XXX
 SG_ PCS2_dcdcA_lv1Temp m98 : 8|11@1- (0.15,70.05) [0|0] "" Vector__XXX
 SG_ PCS2_dcdcA_lv2Temp m88 : 8|11@1- (0.15,70.05) [0|0] "" Vector__XXX
 SG_ PCS2_dcdcA_lv2TempMax_10s m80 : 8|11@1- (0.15,70.05) [0|0] "" Vector__XXX
 SG_ PCS2_dcdcA_lv2TempMin_10s m79 : 8|11@1- (0.15,70.05) [0|0] "" Vector__XXX
 SG_ PCS2_dcdcA_tank_zcd_event_pu_max m20 : 8|9@1- (0.01,0) [0|0] "" Vector__XXX
 SG_ PCS2_dcdcBCmdSwitchingFreq_max_1 m78 : 8|14@1+ (0.1,150) [0|0] "" Vector__XXX
 SG_ PCS2_dcdcBHalfBusTopVoltageMin_1 m68 : 8|10@1+ (1,0) [0|0] "" Vector__XXX
 SG_ PCS2_dcdcBHvCurrentCommand m65 : 8|13@1- (0.01,0) [0|0] "" Vector__XXX
 SG_ PCS2_dcdcBHvMosfetModelTemp m96 : 8|9@1- (1,106) [0|0] "" Vector__XXX
 SG_ PCS2_dcdcBHvVoltage m64 : 8|14@1+ (0.1,0) [0|0] "" Vector__XXX
 SG_ PCS2_dcdcBHvVoltageMin_10s m66 : 8|14@1+ (0.1,0) [0|0] "" Vector__XXX
 SG_ PCS2_dcdcBLifetimekWh m71 : 8|24@1+ (0.01,0) [0|0] "" Vector__XXX
 SG_ PCS2_dcdcBLvMosfetModelTemp m72 : 8|9@1- (1,106) [0|0] "" Vector__XXX
 SG_ PCS2_dcdcBLvVoltageTarget m70 : 8|13@1+ (0.01,0) [0|0] "" Vector__XXX
 SG_ PCS2_dcdcBPWMBlockedByArbitratio m76 : 8|1@1+ (1,0) [0|0] "" Vector__XXX
 SG_ PCS2_dcdcBStageManagerRetryCount m74 : 8|3@1+ (1,0) [0|0] "" Vector__XXX
 SG_ PCS2_dcdcBTankLeakFreq m69 : 8|12@1+ (0.1,0) [0|0] "" Vector__XXX
 SG_ PCS2_dcdcB_L_tank m67 : 8|11@1+ (0.1,0) [0|0] "" Vector__XXX
 SG_ PCS2_dcdcB_tank_zcd_event_pu_max m77 : 8|9@1- (0.01,0) [0|0] "" Vector__XXX
 SG_ PCS2_dcdcGdpsHealthCheckStatus m22 : 8|2@1+ (1,0) [0|0] "" Vector__XXX
 SG_ PCS2_dcdcLvBusVoltage m83 : 8|13@1+ (0.01,0) [0|0] "" Vector__XXX
 SG_ PCS2_dcdcLvBusVoltageFiltered m3 : 8|13@1+ (0.01,0) [0|0] "" Vector__XXX
 SG_ PCS2_dcdcUsingInternalDefLvTarge m1 : 8|1@1+ (1,0) [0|0] "" Vector__XXX
 SG_ PCS2_dcdc_hvTemp m81 : 8|11@1- (0.15,70.05) [0|0] "" Vector__XXX
 SG_ PCS2_detectedInternalPhaseConfig m131 : 8|3@1+ (1,0) [0|0] "" Vector__XXX
 SG_ PCS2_hvBusEstimatedCapacitance m73 : 8|10@1+ (10,0) [0|0] "" Vector__XXX
 SG_ PCS2_hwZcdFaultRateMax60s m97 : 8|16@1+ (0.001,0) [0|0] "" Vector__XXX
 SG_ PCS2_ipcCpu0ToCpu1MaxSuccessiveL m18 : 8|3@1+ (1,0) [0|0] "" Vector__XXX
 SG_ PCS2_ipcCpu1ToCpu0MaxSuccessiveL m75 : 8|3@1+ (1,0) [0|0] "" Vector__XXX
 SG_ PCS2_ipcCpu2ToCpu0MaxSuccessiveL m154 : 8|3@1+ (1,0) [0|0] "" Vector__XXX
 SG_ PCS2_ipcCpu3ToCpu0MaxSuccessiveL m200 : 8|3@1+ (1,0) [0|0] "" Vector__XXX
 SG_ PCS2_lite_BoostCurrentPeak m38 : 8|10@1+ (0.05,0) [0|0] "" Vector__XXX
 SG_ PCS2_lite_ambientTemp m84 : 8|11@1- (0.15,70.05) [0|0] "" Vector__XXX
 SG_ PCS2_lite_boost_duty m32 : 8|7@1+ (0.01,0) [0|0] "" Vector__XXX
 SG_ PCS2_lite_dcdc_LV_A_Temp m85 : 8|11@1- (0.15,70.05) [0|0] "" Vector__XXX
 SG_ PCS2_lite_lvBiasRailSense m33 : 8|12@1+ (0.01,0) [0|0] "" Vector__XXX
 SG_ PCS2_llcControllerFreqMHz m4 : 8|8@1+ (0.01,0) [0|0] "" Vector__XXX
 SG_ PCS2_mfgFuncTestCalIterativeStat m14 : 8|4@1+ (1,0) [0|0] "" Vector__XXX
 SG_ PCS2_mfgFuncTestIOXWriteFailed m15 : 8|10@1+ (1,0) [0|0] "" Vector__XXX
 SG_ PCS2_mfgFuncTestState m12 : 8|4@1+ (1,0) [0|0] "" Vector__XXX
 SG_ PCS2_mfg_can_injection_msg_index m13 : 8|3@1+ (1,0) [0|0] "" Vector__XXX
 SG_ PCS2_microgridHeartbeatDetected m201 : 8|1@1+ (1,0) [0|0] "" Vector__XXX
 SG_ PCS2_phase_diff_L1N_L2N m141 : 8|8@1+ (1,0) [0|0] "" Vector__XXX
 SG_ PCS2_vcrEfuseState m34 : 8|1@1+ (1,0) [0|0] "" Vector__XXX
 SG_ PCS2_logMessageSelect M : 0|8@1+ (1,0) [0|0] "" Vector__XXX

BO_ 745 DIF_powerSlow: 8 Vector__XXX
 SG_ DIF_drivePowerMaxSlow : 48|9@1+ (1,0) [0|0] "" Vector__XXX
 SG_ DIF_excessHeatCommandSlow : 40|8@1+ (0.08,0) [0|0] "" Vector__XXX
 SG_ DIF_heatPowerActualSlow : 32|8@1+ (0.08,0) [0|0] "" Vector__XXX
 SG_ DIF_heatPowerMaxSlow : 24|8@1+ (0.08,0) [0|0] "" Vector__XXX
 SG_ DIF_heatPowerOptimalSlow : 16|8@1+ (0.08,0) [0|0] "" Vector__XXX
 SG_ DIF_elecPowerSlow : 0|11@1- (0.5,0) [0|0] "" Vector__XXX

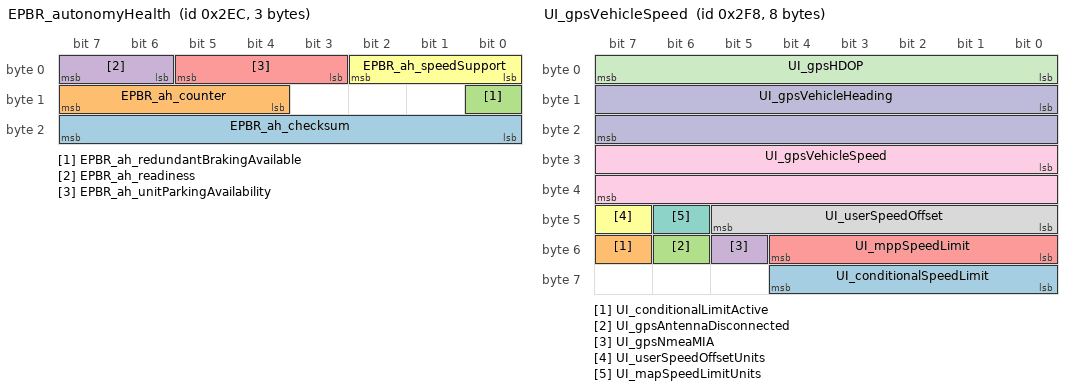
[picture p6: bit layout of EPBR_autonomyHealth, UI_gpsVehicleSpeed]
BO_ 748 EPBR_autonomyHealth: 3 Vector__XXX
 SG_ EPBR_ah_checksum : 16|8@1+ (1,0) [0|0] "" Vector__XXX
 SG_ EPBR_ah_counter : 12|4@1+ (1,0) [0|0] "" Vector__XXX
 SG_ EPBR_ah_redundantBrakingAvailable : 8|1@1+ (1,0) [0|0] "" Vector__XXX
 SG_ EPBR_ah_readiness : 6|2@1+ (1,0) [0|0] "" Vector__XXX
 SG_ EPBR_ah_unitParkingAvailability : 3|3@1+ (1,0) [0|0] "" Vector__XXX
 SG_ EPBR_ah_speedSupport : 0|3@1+ (1,0) [0|0] "" Vector__XXX

BO_ 760 UI_gpsVehicleSpeed: 8 Vector__XXX
 SG_ UI_conditionalSpeedLimit : 56|5@1+ (5,0) [0|0] "" Vector__XXX
 SG_ UI_conditionalLimitActive : 55|1@1+ (1,0) [0|0] "" Vector__XXX
 SG_ UI_gpsAntennaDisconnected : 54|1@1+ (1,0) [0|0] "" Vector__XXX
 SG_ UI_gpsNmeaMIA : 53|1@1+ (1,0) [0|0] "" Vector__XXX
 SG_ UI_mppSpeedLimit : 48|5@1+ (5,0) [0|0] "" Vector__XXX
 SG_ UI_userSpeedOffsetUnits : 47|1@1+ (1,0) [0|0] "" Vector__XXX
 SG_ UI_mapSpeedLimitUnits : 46|1@1+ (1,0) [0|0] "" Vector__XXX
 SG_ UI_userSpeedOffset : 40|6@1+ (1,-30) [0|0] "" Vector__XXX
 SG_ UI_gpsVehicleSpeed : 24|16@1+ (0.00390625,0) [0|0] "" Vector__XXX
 SG_ UI_gpsVehicleHeading : 8|16@1+ (0.0078125,0) [0|0] "" Vector__XXX
 SG_ UI_gpsHDOP : 0|8@1+ (0.1,0) [0|0] "" Vector__XXX

BO_ 761 VCSEC_additionalAuthInfo: 8 Vector__XXX
 SG_ VCSEC_NFCAuthFromCenterConsoleFormFactor m5 : 35|3@1+ (1,0) [0|0] "" Vector__XXX
 SG_ VCSEC_BLEDeviceWithinSummonRange m4 : 32|32@1+ (1,0) [0|0] "" Vector__XXX
 SG_ VCSEC_NFCAuthFromBPillarFormFactor m5 : 32|3@1+ (1,0) [0|0] "" Vector__XXX
 SG_ VCSEC_activeKeySHA1 m0 : 32|32@1+ (1,0) [0|0] "" Vector__XXX
 SG_ VCSEC_keyWithinSummonRange0 m1 : 32|32@1+ (1,0) [0|0] "" Vector__XXX
 SG_ VCSEC_keyWithinSummonRange1 m2 : 32|32@1+ (1,0) [0|0] "" Vector__XXX
 SG_ VCSEC_keyWithinSummonRange2 m3 : 32|32@1+ (1,0) [0|0] "" Vector__XXX
 SG_ VCSEC_AdditionalAuthInfoIndex M : 27|3@1+ (1,0) [0|0] "" Vector__XXX
 SG_ VCSEC_activeKeyReason m0 : 24|3@1+ (1,0) [0|0] "" Vector__XXX
 SG_ VCSEC_bleConnetionAttemptWLEntry : 19|5@1+ (1,0) [0|0] "" Vector__XXX
 SG_ VCSEC_bleDisconnectionReason : 11|8@1+ (1,0) [0|0] "" Vector__XXX
 SG_ VCSEC_bleChannelDisconnected : 7|4@1+ (1,0) [0|0] "" Vector__XXX
 SG_ VCSEC_activeKeyDebug : 2|5@1+ (1,0) [0|0] "" Vector__XXX
 SG_ VCSEC_algoUsedForSummonRange0 m1 : 0|1@1+ (1,0) [0|0] "" Vector__XXX
 SG_ VCSEC_algoUsedForSummonRange1 m2 : 0|1@1+ (1,0) [0|0] "" Vector__XXX
 SG_ VCSEC_algoUsedForSummonRange2 m3 : 0|1@1+ (1,0) [0|0] "" Vector__XXX

BO_ 775 PTC_faultsAndExtras: 8 Vector__XXX
 SG_ PTC_igbt15V : 56|8@1+ (0.25,0) [0|0] "" Vector__XXX
 SG_ PTC_failLeftCurrentHVSensorWng : 31|1@1+ (1,0) [0|0] "" Vector__XXX
 SG_ PTC_failRightCurrentHVSensorWng : 30|1@1+ (1,0) [0|0] "" Vector__XXX
 SG_ PTC_failRightIGBTShortWarning : 29|1@1+ (1,0) [0|0] "" Vector__XXX
 SG_ PTC_failLeftIGBTShortWarning : 28|1@1+ (1,0) [0|0] "" Vector__XXX
 SG_ PTC_failRightIGBTOpen : 27|1@1+ (1,0) [0|0] "" Vector__XXX
 SG_ PTC_failLeftIGBTOpen : 26|1@1+ (1,0) [0|0] "" Vector__XXX
 SG_ PTC_failIGBTDriverPermanent : 25|1@1+ (1,0) [0|0] "" Vector__XXX
 SG_ PTC_failIGBTDriverTemporary : 24|1@1+ (1,0) [0|0] "" Vector__XXX
 SG_ PTC_failRightIGBTShort : 23|1@1+ (1,0) [0|0] "" Vector__XXX
 SG_ PTC_failLeftIGBTShort : 22|1@1+ (1,0) [0|0] "" Vector__XXX
 SG_ PTC_failTempPCB : 21|1@1+ (1,0) [0|0] "" Vector__XXX
 SG_ PTC_failRightTempIGBT : 20|1@1+ (1,0) [0|0] "" Vector__XXX
 SG_ PTC_failTempOCP : 19|1@1+ (1,0) [0|0] "" Vector__XXX
 SG_ PTC_failLeftTempIGBT : 18|1@1+ (1,0) [0|0] "" Vector__XXX
 SG_ PTC_failRightCurrentHVSensor : 17|1@1+ (1,0) [0|0] "" Vector__XXX
 SG_ PTC_failLeftCurrentHVSensor : 16|1@1+ (1,0) [0|0] "" Vector__XXX
 SG_ PTC_failHighVoltageSensor : 15|1@1+ (1,0) [0|0] "" Vector__XXX
 SG_ PTC_failLowVoltageSensor : 14|1@1+ (1,0) [0|0] "" Vector__XXX
 SG_ PTC_faultCANTimeout : 13|1@1+ (1,0) [0|0] "" Vector__XXX
 SG_ PTC_faultRightThermalShutIGBT : 12|1@1+ (1,0) [0|0] "" Vector__XXX
 SG_ PTC_faultLeftThermalShutIGBT : 10|1@1+ (1,0) [0|0] "" Vector__XXX
 SG_ PTC_faultThermalShutPCB : 9|1@1+ (1,0) [0|0] "" Vector__XXX
 SG_ PTC_faultRightThermalShutOutlet : 8|1@1+ (1,0) [0|0] "" Vector__XXX
 SG_ PTC_faultLeftThermalShutOutlet : 7|1@1+ (1,0) [0|0] "" Vector__XXX
 SG_ PTC_faultRightOverCurrent : 6|1@1+ (1,0) [0|0] "" Vector__XXX
 SG_ PTC_faultLeftOverCurrent : 5|1@1+ (1,0) [0|0] "" Vector__XXX
 SG_ PTC_faultHVHigh : 4|1@1+ (1,0) [0|0] "" Vector__XXX
 SG_ PTC_faultHVLow : 3|1@1+ (1,0) [0|0] "" Vector__XXX
 SG_ PTC_faultLVHigh : 2|1@1+ (1,0) [0|0] "" Vector__XXX
 SG_ PTC_faultLVLow : 1|1@1+ (1,0) [0|0] "" Vector__XXX

BO_ 776 OCS1P_status: 8 Vector__XXX
 SG_ OCS1P_statusChecksum : 56|8@1+ (1,0) [0|0] "" Vector__XXX
 SG_ OCS1P_statusCounter : 52|4@1+ (1,0) [0|0] "" Vector__XXX
 SG_ OCS1P_classificationHeldCap : 51|1@1+ (1,0) [0|0] "" Vector__XXX
 SG_ OCS1P_seatbackStableCap : 50|1@1+ (1,0) [0|0] "" Vector__XXX
 SG_ OCS1P_cushionStableCap : 49|1@1+ (1,0) [0|0] "" Vector__XXX
 SG_ OCS1P_sandwichStable : 48|1@1+ (1,0) [0|0] "" Vector__XXX
 SG_ OCS1P_seatbackStable : 47|1@1+ (1,0) [0|0] "" Vector__XXX
 SG_ OCS1P_occupiedStateCap : 45|2@1+ (1,0) [0|0] "" Vector__XXX
 SG_ OCS1P_sbrBoundaryType : 43|1@1+ (1,0) [0|0] "" Vector__XXX
 SG_ OCS1P_sandwichBoundaryType : 42|1@1+ (1,0) [0|0] "" Vector__XXX
 SG_ OCS1P_noSandwichType : 40|2@1+ (1,0) [0|0] "" Vector__XXX
 SG_ OCS1P_sandwichDisabled : 39|1@1+ (1,0) [0|0] "" Vector__XXX
 SG_ OCS1P_classificationVariant : 36|3@1+ (1,0) [0|0] "" Vector__XXX
 SG_ OCS1P_classificationHoldState : 33|3@1+ (1,0) [0|0] "" Vector__XXX
 SG_ OCS1P_classificationExtHold : 32|1@1+ (1,0) [0|0] "" Vector__XXX
 SG_ OCS1P_cushionStable : 31|1@1+ (1,0) [0|0] "" Vector__XXX
 SG_ OCS1P_classificationHeld : 30|1@1+ (1,0) [0|0] "" Vector__XXX
 SG_ OCS1P_occupantClassificationCap : 25|3@1+ (1,0) [0|0] "" Vector__XXX
 SG_ OCS1P_occupantClassificationRawCap : 22|3@1+ (1,0) [0|0] "" Vector__XXX
 SG_ OCS1P_occupantClassificationSelf : 19|3@1+ (1,0) [0|0] "" Vector__XXX
 SG_ OCS1P_occupantClassificationRaw : 16|3@1+ (1,0) [0|0] "" Vector__XXX
 SG_ OCS1P_triggerSnapshot : 11|5@1+ (1,0) [0|0] "" Vector__XXX
 SG_ OCS1P_occupiedState : 9|2@1+ (1,0) [0|0] "" Vector__XXX
 SG_ OCS1P_occupantClassificationQF : 8|1@1+ (1,0) [0|0] "" Vector__XXX
 SG_ OCS1P_occupantClassification : 0|8@1+ (1,0) [0|0] "" Vector__XXX

BO_ 781 DAS_positioningEngineStatus: 8 Vector__XXX
 SG_ DAS_meoNumDdcpConstraints9 m1 : 56|2@1+ (1,0) [0|0] "" Vector__XXX
 SG_ DAS_meoNumDdcpConstraints8 m1 : 54|2@1+ (1,0) [0|0] "" Vector__XXX
 SG_ DAS_meoNumDdcpConstraints7 m1 : 52|2@1+ (1,0) [0|0] "" Vector__XXX
 SG_ DAS_meoNumDdcpConstraints6 m1 : 50|2@1+ (1,0) [0|0] "" Vector__XXX
 SG_ DAS_meoNumDdcpConstraints5 m1 : 48|2@1+ (1,0) [0|0] "" Vector__XXX
 SG_ DAS_meoNumDdcpConstraints4 m1 : 46|2@1+ (1,0) [0|0] "" Vector__XXX
 SG_ DAS_meoNumDdcpConstraints3 m1 : 44|2@1+ (1,0) [0|0] "" Vector__XXX
 SG_ DAS_meoNumDdcpConstraints2 m1 : 42|2@1+ (1,0) [0|0] "" Vector__XXX
 SG_ DAS_lastMeoResetReason m2 : 42|2@1+ (1,0) [0|0] "" Vector__XXX
 SG_ DAS_meoNumDdcpConstraints1 m1 : 40|2@1+ (1,0) [0|0] "" Vector__XXX
 SG_ DAS_meoResetCount m2 : 39|3@1+ (1,0) [0|0] "" Vector__XXX
 SG_ DAS_meoNumDdcpConstraints0 m1 : 38|2@1+ (1,0) [0|0] "" Vector__XXX
 SG_ DAS_meoNumSdprConstraints9 m1 : 36|2@1+ (1,0) [0|0] "" Vector__XXX
 SG_ DAS_meoFixType m2 : 36|3@1+ (1,0) [0|0] "" Vector__XXX
 SG_ DAS_meoNumSdprConstraints8 m1 : 34|2@1+ (1,0) [0|0] "" Vector__XXX
 SG_ DAS_meoGpsQualityLevel m2 : 33|3@1+ (1,0) [0|0] "" Vector__XXX
 SG_ DAS_meoNumSdprConstraints7 m1 : 32|2@1+ (1,0) [0|0] "" Vector__XXX
 SG_ DAS_meoNumSdprConstraints6 m1 : 30|2@1+ (1,0) [0|0] "" Vector__XXX
 SG_ DAS_meoNumSdprConstraints5 m1 : 28|2@1+ (1,0) [0|0] "" Vector__XXX
 SG_ DAS_meoNumSatellitesUsed m2 : 28|5@1+ (1,0) [0|0] "" Vector__XXX
 SG_ DAS_disableMonarch m3 : 28|1@1+ (1,0) [0|0] "" Vector__XXX
 SG_ DAS_orioleDisabled m3 : 27|1@1+ (1,0) [0|0] "" Vector__XXX
 SG_ DAS_meoHeadingValid m2 : 27|1@1+ (1,0) [0|0] "" Vector__XXX
 SG_ DAS_tdcpNumSatellitesUsed m0 : 26|5@1+ (1,0) [0|0] "" Vector__XXX
 SG_ DAS_meoNumSdprConstraints4 m1 : 26|2@1+ (1,0) [0|0] "" Vector__XXX
 SG_ DAS_bluefinEnabled m3 : 26|1@1+ (1,0) [0|0] "" Vector__XXX
 SG_ DAS_publishedGpsSource m3 : 24|2@1+ (1,0) [0|0] "" Vector__XXX
 SG_ DAS_meoNumSdprConstraints3 m1 : 24|2@1+ (1,0) [0|0] "" Vector__XXX
 SG_ DAS_meoHeadingAccuracyDeg m2 : 24|3@1+ (1,0) [0|0] "" Vector__XXX
 SG_ DAS_meoNumSdprConstraints2 m1 : 22|2@1+ (1,0) [0|0] "" Vector__XXX
 SG_ DAS_vioMultiGpsPeMeoVsRawGpsRotDiscrepDeg m3 : 21|3@1+ (1,0) [0|0] "" Vector__XXX
 SG_ DAS_tdcpSolutionStatus m0 : 21|5@1+ (1,0) [0|0] "" Vector__XXX
 SG_ DAS_meoNumSdprConstraints1 m1 : 20|2@1+ (1,0) [0|0] "" Vector__XXX
 SG_ DAS_vioMultiGpsPeSppTdcpVsRawGpsRotDiscrepDeg m3 : 18|3@1+ (1,0) [0|0] "" Vector__XXX
 SG_ DAS_meoVerticalAccuracyM m2 : 18|6@1+ (1,0) [0|0] "" Vector__XXX
 SG_ DAS_meoNumSdprConstraints0 m1 : 18|2@1+ (1,0) [0|0] "" Vector__XXX
 SG_ DAS_sppNumSatellitesUsed m0 : 16|5@1+ (1,0) [0|0] "" Vector__XXX
 SG_ DAS_vioMultiGpsPeMeoVsRawGpsTransDiscrepM m3 : 14|4@1+ (1,0) [0|0] "" Vector__XXX
 SG_ DAS_meoNodesSize m1 : 14|4@1+ (1,0) [0|0] "" Vector__XXX
 SG_ DAS_sppPdopM m0 : 13|3@1+ (1,0) [0|0] "" Vector__XXX
 SG_ DAS_meoHorizontalAccuracyM m2 : 12|6@1+ (1,0) [0|0] "" Vector__XXX
 SG_ DAS_vioMultiGpsPeSppTdcpVsRawGpsTransDiscrepM m3 : 10|4@1+ (1,0) [0|0] "" Vector__XXX
 SG_ DAS_vioMultiGpsPeMeoConsistentWithRawGps m3 : 9|1@1+ (1,0) [0|0] "" Vector__XXX
 SG_ DAS_sppSolutionStatus m0 : 9|4@1+ (1,0) [0|0] "" Vector__XXX
 SG_ DAS_meoSolverReportTotalTimeS m2 : 9|3@1+ (1,0) [0|0] "" Vector__XXX
 SG_ DAS_meoSolutionStatus m1 : 9|5@1+ (1,0) [0|0] "" Vector__XXX
 SG_ DAS_vioMultiGpsPeSppTdcpConsistentWithRawGps m3 : 8|1@1+ (1,0) [0|0] "" Vector__XXX
 SG_ DAS_vioMultiGpsPeCooldownActive m3 : 7|1@1+ (1,0) [0|0] "" Vector__XXX
 SG_ DAS_numParsedObservations m0 : 7|2@1+ (1,0) [0|0] "" Vector__XXX
 SG_ DAS_meoSolverReportTerminationType m2 : 6|3@1+ (1,0) [0|0] "" Vector__XXX
 SG_ DAS_hasParsedEphemerides m0 : 6|1@1+ (1,0) [0|0] "" Vector__XXX
 SG_ DAS_vioMultiGpsSelectedSource m3 : 4|3@1+ (1,0) [0|0] "" Vector__XXX
 SG_ DAS_positioningEngineTimesyncSource m0 : 4|2@1+ (1,0) [0|0] "" Vector__XXX
 SG_ DAS_meoVersion m1 : 4|5@1+ (1,0) [0|0] "" Vector__XXX
 SG_ DAS_meoSolverNumRuns m2 : 4|2@1+ (1,0) [0|0] "" Vector__XXX
 SG_ DAS_positioningEngineStatusMultiplexer M : 0|4@1+ (1,0) [0|0] "" Vector__XXX

BO_ 783 OCS1P_debugCushionMutCNTComp: 6 Vector__XXX
 SG_ OCS1P_deltaFreqCushionMut : 32|16@1- (1,0) [0|0] "" Vector__XXX
 SG_ OCS1P_cushionMutCNTFreqComp : 0|16@1+ (1,0) [0|0] "" Vector__XXX

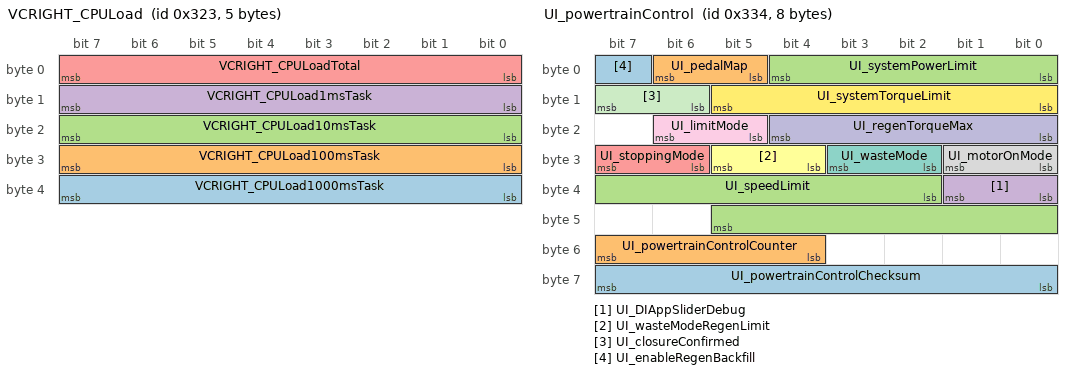
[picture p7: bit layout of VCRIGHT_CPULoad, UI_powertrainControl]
BO_ 803 VCRIGHT_CPULoad: 5 Vector__XXX
 SG_ VCRIGHT_CPULoad1000msTask : 32|8@1+ (1,0) [0|0] "" Vector__XXX
 SG_ VCRIGHT_CPULoad100msTask : 24|8@1+ (1,0) [0|0] "" Vector__XXX
 SG_ VCRIGHT_CPULoad10msTask : 16|8@1+ (1,0) [0|0] "" Vector__XXX
 SG_ VCRIGHT_CPULoad1msTask : 8|8@1+ (1,0) [0|0] "" Vector__XXX
 SG_ VCRIGHT_CPULoadTotal : 0|8@1+ (1,0) [0|0] "" Vector__XXX

BO_ 804 UI_gpsTime: 8 Vector__XXX
 SG_ UI_gpsTime : 0|64@1+ (1,0) [0|0] "" Vector__XXX

BO_ 807 USM_info: 8 Vector__XXX
 SG_ USM_infoComponentId m10 : 48|16@1+ (1,0) [0|0] "" Vector__XXX
 SG_ USM_infoSubUsageId m11 : 40|16@1+ (1,0) [0|0] "" Vector__XXX
 SG_ USM_infoSubcomponent1 m16 : 32|32@1+ (1,0) [0|0] "" Vector__XXX
 SG_ USM_infoHardwareId m10 : 32|16@1+ (1,0) [0|0] "" Vector__XXX
 SG_ USM_infoUsageId m11 : 24|16@1+ (1,0) [0|0] "" Vector__XXX
 SG_ USM_infoBootCrc m20 : 24|32@1+ (1,0) [0|0] "" Vector__XXX
 SG_ USM_infoBuildConfigId m10 : 16|16@1+ (1,0) [0|0] "" Vector__XXX
 SG_ USM_infoAssemblyId m11 : 16|8@1+ (1,0) [0|0] "" Vector__XXX
 SG_ USM_infoPlatformType m19 : 8|8@1+ (1,0) [0|0] "" Vector__XXX
 SG_ USM_infoPcbaId m11 : 8|8@1+ (1,0) [0|0] "" Vector__XXX
 SG_ USM_infoBuildType m10 : 8|3@1+ (1,0) [0|0] "" Vector__XXX
 SG_ USM_infoBootUdsProtoVersion m20 : 8|16@1+ (1,0) [0|0] "" Vector__XXX
 SG_ USM_infoBootGitHash m18 : 8|56@1+ (1,0) [0|0] "" Vector__XXX
 SG_ USM_infoAppGitHash m17 : 8|56@1+ (1,0) [0|0] "" Vector__XXX
 SG_ USM_infoAppCrc m13 : 8|32@1+ (1,0) [0|0] "" Vector__XXX
 SG_ USM_infoIndex M : 0|8@1+ (1,0) [0|0] "" Vector__XXX

BO_ 820 UI_powertrainControl: 8 Vector__XXX
 SG_ UI_powertrainControlChecksum : 56|8@1+ (1,0) [0|0] "" Vector__XXX
 SG_ UI_powertrainControlCounter : 52|4@1+ (1,0) [0|0] "" Vector__XXX
 SG_ UI_speedLimit : 34|12@1+ (0.1,0) [0|0] "" Vector__XXX
 SG_ UI_DIAppSliderDebug : 32|2@1+ (1,0) [0|0] "" Vector__XXX
 SG_ UI_stoppingMode : 30|2@1+ (1,0) [0|0] "" Vector__XXX
 SG_ UI_wasteModeRegenLimit : 28|2@1+ (1,0) [0|0] "" Vector__XXX
 SG_ UI_wasteMode : 26|2@1+ (1,0) [0|0] "" Vector__XXX
 SG_ UI_motorOnMode : 24|2@1+ (1,0) [0|0] "" Vector__XXX
 SG_ UI_limitMode : 21|2@1+ (1,0) [0|0] "" Vector__XXX
 SG_ UI_regenTorqueMax : 16|5@1+ (5,0) [0|0] "" Vector__XXX
 SG_ UI_closureConfirmed : 14|2@1+ (1,0) [0|0] "" Vector__XXX
 SG_ UI_systemTorqueLimit : 8|6@1+ (150,1000) [0|0] "" Vector__XXX
 SG_ UI_enableRegenBackfill : 7|1@1+ (1,0) [0|0] "" Vector__XXX
 SG_ UI_pedalMap : 5|2@1+ (1,0) [0|0] "" Vector__XXX
 SG_ UI_systemPowerLimit : 0|5@1+ (20,20) [0|0] "" Vector__XXX

BO_ 829 CP_plcInfo: 8 Vector__XXX
 SG_ CP_plcPibCrc : 32|32@1+ (1,0) [0|0] "" Vector__XXX
 SG_ CP_plcFwCrc : 0|32@1+ (1,0) [0|0] "" Vector__XXX

BO_ 833 VCFRONT1_alertMatrix: 8 Vector__XXX
 SG_ VCFRONT1_a060_engineeringBuild m0 : 63|1@1+ (1,0) [0|0] "" Vector__XXX
 SG_ VCFRONT1_a120_DI_DRIVE_MIA m1 : 63|1@1+ (1,0) [0|0] "" Vector__XXX
 SG_ VCFRONT1_a059_inputResistanceHig m0 : 62|1@1+ (1,0) [0|0] "" Vector__XXX
 SG_ VCFRONT1_a119_SCCM_MIA m1 : 62|1@1+ (1,0) [0|0] "" Vector__XXX
 SG_ VCFRONT1_a058_inputRHighSyncDebu m0 : 61|1@1+ (1,0) [0|0] "" Vector__XXX
 SG_ VCFRONT1_a118_VCFRONT_MIA m1 : 61|1@1+ (1,0) [0|0] "" Vector__XXX
 SG_ VCFRONT1_a117_VCLEFT_MIA m1 : 60|1@1+ (1,0) [0|0] "" Vector__XXX
 SG_ VCFRONT1_a177_mcuAudioEFuseTrip m2 : 60|1@1+ (1,0) [0|0] "" Vector__XXX
 SG_ VCFRONT1_a597_vcrightFastBlowPow m9 : 60|1@1+ (1,0) [0|0] "" Vector__XXX
 SG_ VCFRONT1_a116_VCRIGHT_MIA m1 : 59|1@1+ (1,0) [0|0] "" Vector__XXX
 SG_ VCFRONT1_a596_vcrightCurvePowerC m9 : 59|1@1+ (1,0) [0|0] "" Vector__XXX
 SG_ VCFRONT1_a115_VCSEC_MIA m1 : 58|1@1+ (1,0) [0|0] "" Vector__XXX
 SG_ VCFRONT1_a415_undervoltageSelfTe m6 : 58|1@1+ (1,0) [0|0] "" Vector__XXX
 SG_ VCFRONT1_a475_vnf1248Fault m7 : 58|1@1+ (1,0) [0|0] "" Vector__XXX
 SG_ VCFRONT1_a114_ESP_MIA m1 : 57|1@1+ (1,0) [0|0] "" Vector__XXX
 SG_ VCFRONT1_a414_undervoltageSelfTe m6 : 57|1@1+ (1,0) [0|0] "" Vector__XXX
 SG_ VCFRONT1_a113_UI_MIA m1 : 56|1@1+ (1,0) [0|0] "" Vector__XXX
 SG_ VCFRONT1_a112_EPBL_MIA m1 : 55|1@1+ (1,0) [0|0] "" Vector__XXX
 SG_ VCFRONT1_a111_EPBR_MIA m1 : 54|1@1+ (1,0) [0|0] "" Vector__XXX
 SG_ VCFRONT1_a591_vcrightFastBlowDet m9 : 54|1@1+ (1,0) [0|0] "" Vector__XXX
 SG_ VCFRONT1_a110_GTW_MIA m1 : 53|1@1+ (1,0) [0|0] "" Vector__XXX
 SG_ VCFRONT1_a590_vcrightPwrRational m9 : 53|1@1+ (1,0) [0|0] "" Vector__XXX
 SG_ VCFRONT1_a229_LVHealthCompromise m3 : 52|1@1+ (1,0) [0|0] "" Vector__XXX
 SG_ VCFRONT1_a108_DIF_MIA m1 : 51|1@1+ (1,0) [0|0] "" Vector__XXX
 SG_ VCFRONT1_a107_BMS_MIA m1 : 50|1@1+ (1,0) [0|0] "" Vector__XXX
 SG_ VCFRONT1_a046_Task1000msError m0 : 49|1@1+ (1,0) [0|0] "" Vector__XXX
 SG_ VCFRONT1_a106_PCS_MIA m1 : 49|1@1+ (1,0) [0|0] "" Vector__XXX
 SG_ VCFRONT1_a045_Task100msError m0 : 48|1@1+ (1,0) [0|0] "" Vector__XXX
 SG_ VCFRONT1_a105_TAS_MIA m1 : 48|1@1+ (1,0) [0|0] "" Vector__XXX
 SG_ VCFRONT1_a165_unxpctdEFuseLckout m2 : 48|1@1+ (1,0) [0|0] "" Vector__XXX
 SG_ VCFRONT1_a044_Task10msError m0 : 47|1@1+ (1,0) [0|0] "" Vector__XXX
 SG_ VCFRONT1_a104_DAS_MIA m1 : 47|1@1+ (1,0) [0|0] "" Vector__XXX
 SG_ VCFRONT1_a164_eFuseLckoutMissing m2 : 47|1@1+ (1,0) [0|0] "" Vector__XXX
 SG_ VCFRONT1_a043_Task1msError m0 : 46|1@1+ (1,0) [0|0] "" Vector__XXX
 SG_ VCFRONT1_a103_CP_MIA m1 : 46|1@1+ (1,0) [0|0] "" Vector__XXX
 SG_ VCFRONT1_a223_bridgeOvervoltageS m3 : 46|1@1+ (1,0) [0|0] "" Vector__XXX
 SG_ VCFRONT1_a042_HighStackUsage m0 : 45|1@1+ (1,0) [0|0] "" Vector__XXX
 SG_ VCFRONT1_a041_HighCPULoad m0 : 44|1@1+ (1,0) [0|0] "" Vector__XXX
 SG_ VCFRONT1_a581_harnessResistanceI m9 : 44|1@1+ (1,0) [0|0] "" Vector__XXX
 SG_ VCFRONT1_a040_Backtrace m0 : 43|1@1+ (1,0) [0|0] "" Vector__XXX
 SG_ VCFRONT1_a100_CANbus_MIA m1 : 43|1@1+ (1,0) [0|0] "" Vector__XXX
 SG_ VCFRONT1_a220_LVUnhealthy m3 : 43|1@1+ (1,0) [0|0] "" Vector__XXX
 SG_ VCFRONT1_a039_ProtFaultAddress m0 : 42|1@1+ (1,0) [0|0] "" Vector__XXX
 SG_ VCFRONT1_a038_ProtFaultInfo m0 : 41|1@1+ (1,0) [0|0] "" Vector__XXX
 SG_ VCFRONT1_a098_DIR_MIA m1 : 41|1@1+ (1,0) [0|0] "" Vector__XXX
 SG_ VCFRONT1_a578_vbusFusedLoadShedE m9 : 41|1@1+ (1,0) [0|0] "" Vector__XXX
 SG_ VCFRONT1_a037_MemManageFault m0 : 40|1@1+ (1,0) [0|0] "" Vector__XXX
 SG_ VCFRONT1_a036_UnknownIrq m0 : 39|1@1+ (1,0) [0|0] "" Vector__XXX
 SG_ VCFRONT1_a096_OCS1P_MIA m1 : 39|1@1+ (1,0) [0|0] "" Vector__XXX
 SG_ VCFRONT1_a216_powerCutoffImminen m3 : 39|1@1+ (1,0) [0|0] "" Vector__XXX
 SG_ VCFRONT1_a214_openCircuitDetecte m3 : 37|1@1+ (1,0) [0|0] "" Vector__XXX
 SG_ VCFRONT1_a574_frontDriveInverter m9 : 37|1@1+ (1,0) [0|0] "" Vector__XXX
 SG_ VCFRONT1_a031_UDSActive m0 : 34|1@1+ (1,0) [0|0] "" Vector__XXX
 SG_ VCFRONT1_a091_CMPD_MIA m1 : 34|1@1+ (1,0) [0|0] "" Vector__XXX
 SG_ VCFRONT1_a030_ECULogUploadReques m0 : 33|1@1+ (1,0) [0|0] "" Vector__XXX
 SG_ VCFRONT1_a090_APS_MIA m1 : 33|1@1+ (1,0) [0|0] "" Vector__XXX
 SG_ VCFRONT1_a029_CoreDump m0 : 32|1@1+ (1,0) [0|0] "" Vector__XXX
 SG_ VCFRONT1_a509_eFuseASICManagerSt m8 : 32|1@1+ (1,0) [0|0] "" Vector__XXX
 SG_ VCFRONT1_a028_UsageFault m0 : 31|1@1+ (1,0) [0|0] "" Vector__XXX
 SG_ VCFRONT1_a086_VCBATT_MIA m1 : 29|1@1+ (1,0) [0|0] "" Vector__XXX
 SG_ VCFRONT1_a266_EPAS2VoltageMismat m4 : 29|1@1+ (1,0) [0|0] "" Vector__XXX
 SG_ VCFRONT1_a205_overvoltageProtect m3 : 28|1@1+ (1,0) [0|0] "" Vector__XXX
 SG_ VCFRONT1_a144_EPAS3S_MIA m2 : 27|1@1+ (1,0) [0|0] "" Vector__XXX
 SG_ VCFRONT1_a204_undervoltageLoadsh m3 : 27|1@1+ (1,0) [0|0] "" Vector__XXX
 SG_ VCFRONT1_a264_iBoosterVoltageMis m4 : 27|1@1+ (1,0) [0|0] "" Vector__XXX
 SG_ VCFRONT1_a263_pcsVoltageMismatch m4 : 26|1@1+ (1,0) [0|0] "" Vector__XXX
 SG_ VCFRONT1_a022_TaskInitError m0 : 25|1@1+ (1,0) [0|0] "" Vector__XXX
 SG_ VCFRONT1_a082_VCFRONT2_MIA m1 : 25|1@1+ (1,0) [0|0] "" Vector__XXX
 SG_ VCFRONT1_a262_vcrightVoltageMism m4 : 25|1@1+ (1,0) [0|0] "" Vector__XXX
 SG_ VCFRONT1_a021_TaskSchedulerError m0 : 24|1@1+ (1,0) [0|0] "" Vector__XXX
 SG_ VCFRONT1_a081_VCFRONT1_MIA m1 : 24|1@1+ (1,0) [0|0] "" Vector__XXX
 SG_ VCFRONT1_a080_VCFRONT0_MIA m1 : 23|1@1+ (1,0) [0|0] "" Vector__XXX
 SG_ VCFRONT1_a019_BusFault m0 : 22|1@1+ (1,0) [0|0] "" Vector__XXX
 SG_ VCFRONT1_a079_VCBATT2_MIA m1 : 22|1@1+ (1,0) [0|0] "" Vector__XXX
 SG_ VCFRONT1_a018_HardFault m0 : 21|1@1+ (1,0) [0|0] "" Vector__XXX
 SG_ VCFRONT1_a078_VCBATT1_MIA m1 : 21|1@1+ (1,0) [0|0] "" Vector__XXX
 SG_ VCFRONT1_a017_NVMMStatusDbg m0 : 20|1@1+ (1,0) [0|0] "" Vector__XXX
 SG_ VCFRONT1_a077_VCBATT0_MIA m1 : 20|1@1+ (1,0) [0|0] "" Vector__XXX
 SG_ VCFRONT1_a617_APP_MIA m10 : 20|1@1+ (1,0) [0|0] "" Vector__XXX
 SG_ VCFRONT1_a016_NVMMRecordError m0 : 19|1@1+ (1,0) [0|0] "" Vector__XXX
 SG_ VCFRONT1_a496_exitDriveWarningDo m8 : 19|1@1+ (1,0) [0|0] "" Vector__XXX
 SG_ VCFRONT1_a015_NVMMError m0 : 18|1@1+ (1,0) [0|0] "" Vector__XXX
 SG_ VCFRONT1_a135_leftHeadlightEFuse m2 : 18|1@1+ (1,0) [0|0] "" Vector__XXX
 SG_ VCFRONT1_a134_hvContactorsEFuseT m2 : 17|1@1+ (1,0) [0|0] "" Vector__XXX
 SG_ VCFRONT1_a013_AlertManagerFault m0 : 16|1@1+ (1,0) [0|0] "" Vector__XXX
 SG_ VCFRONT1_a133_BRAKE_MIA m2 : 16|1@1+ (1,0) [0|0] "" Vector__XXX
 SG_ VCFRONT1_a253_pcsOvShutdownHighS m4 : 16|1@1+ (1,0) [0|0] "" Vector__XXX
 SG_ VCFRONT1_a012_CPUReset m0 : 15|1@1+ (1,0) [0|0] "" Vector__XXX
 SG_ VCFRONT1_a132_epas2EFuseTrip m2 : 15|1@1+ (1,0) [0|0] "" Vector__XXX
 SG_ VCFRONT1_a252_pcsOvShutdownSelfT m4 : 15|1@1+ (1,0) [0|0] "" Vector__XXX
 SG_ VCFRONT1_a131_PCSCOMMON_MIA m2 : 14|1@1+ (1,0) [0|0] "" Vector__XXX
 SG_ VCFRONT1_a191_exitDriveDomainDow m3 : 14|1@1+ (1,0) [0|0] "" Vector__XXX
 SG_ VCFRONT1_a251_pcsOvShutdownSelfT m4 : 14|1@1+ (1,0) [0|0] "" Vector__XXX
 SG_ VCFRONT1_a491_vnf1248Configurati m8 : 14|1@1+ (1,0) [0|0] "" Vector__XXX
 SG_ VCFRONT1_a130_autopilot2EFuseTri m2 : 13|1@1+ (1,0) [0|0] "" Vector__XXX
 SG_ VCFRONT1_a250_pcsOvShutdownTripp m4 : 13|1@1+ (1,0) [0|0] "" Vector__XXX
 SG_ VCFRONT1_a490_vnf1248SelfTestFai m8 : 13|1@1+ (1,0) [0|0] "" Vector__XXX
 SG_ VCFRONT1_a129_pcsEFuseTrip m2 : 12|1@1+ (1,0) [0|0] "" Vector__XXX
 SG_ VCFRONT1_a249_pcsOvClampTripped m4 : 12|1@1+ (1,0) [0|0] "" Vector__XXX
 SG_ VCFRONT1_a489_vnf1248SelfTestDeb m8 : 12|1@1+ (1,0) [0|0] "" Vector__XXX
 SG_ VCFRONT1_a128_vcrightEFuseTrip m2 : 11|1@1+ (1,0) [0|0] "" Vector__XXX
 SG_ VCFRONT1_a188_sleepFailed m3 : 11|1@1+ (1,0) [0|0] "" Vector__XXX
 SG_ VCFRONT1_a127_iBoosterEFuseTrip m2 : 10|1@1+ (1,0) [0|0] "" Vector__XXX
 SG_ VCFRONT1_a006_CANTX_cyclicError m0 : 9|1@1+ (1,0) [0|0] "" Vector__XXX
 SG_ VCFRONT1_a126_EPAS3P_MIA m2 : 9|1@1+ (1,0) [0|0] "" Vector__XXX
 SG_ VCFRONT1_a486_undervoltageSelfTe m8 : 9|1@1+ (1,0) [0|0] "" Vector__XXX
 SG_ VCFRONT1_a005_CANTXError m0 : 8|1@1+ (1,0) [0|0] "" Vector__XXX
 SG_ VCFRONT1_a125_SCCM_MIA m2 : 8|1@1+ (1,0) [0|0] "" Vector__XXX
 SG_ VCFRONT1_a485_uvSelfTestLoadUnat m8 : 8|1@1+ (1,0) [0|0] "" Vector__XXX
 SG_ VCFRONT1_a064_busSleepReqTimeout m1 : 7|1@1+ (1,0) [0|0] "" Vector__XXX
 SG_ VCFRONT1_a124_BB_MIA m2 : 7|1@1+ (1,0) [0|0] "" Vector__XXX
 SG_ VCFRONT1_a484_undervoltageSelfTe m8 : 7|1@1+ (1,0) [0|0] "" Vector__XXX
 SG_ VCFRONT1_a003_SWAssertion m0 : 6|1@1+ (1,0) [0|0] "" Vector__XXX
 SG_ VCFRONT1_a063_SwitchFault m1 : 6|1@1+ (1,0) [0|0] "" Vector__XXX
 SG_ VCFRONT1_a423_rtosSleepFailed m7 : 6|1@1+ (1,0) [0|0] "" Vector__XXX
 SG_ VCFRONT1_a002_PowerLossReset m0 : 5|1@1+ (1,0) [0|0] "" Vector__XXX
 SG_ VCFRONT1_a062_XCPWasConnected m1 : 5|1@1+ (1,0) [0|0] "" Vector__XXX
 SG_ VCFRONT1_a122_ICR_MIA m2 : 5|1@1+ (1,0) [0|0] "" Vector__XXX
 SG_ VCFRONT1_a482_lvBridgeEFuseTrip m8 : 5|1@1+ (1,0) [0|0] "" Vector__XXX
 SG_ VCFRONT1_a001_WatchdogReset m0 : 4|1@1+ (1,0) [0|0] "" Vector__XXX
 SG_ VCFRONT1_a061_XCPConnected m1 : 4|1@1+ (1,0) [0|0] "" Vector__XXX
 SG_ VCFRONT1_matrixIndex M : 0|4@1+ (1,0) [0|0] "" Vector__XXX

BO_ 834 VCFRONT2_alertMatrix: 8 Vector__XXX
 SG_ VCFRONT2_a060_engineeringBuild m0 : 63|1@1+ (1,0) [0|0] "" Vector__XXX
 SG_ VCFRONT2_a120_DI_DRIVE_MIA m1 : 63|1@1+ (1,0) [0|0] "" Vector__XXX
 SG_ VCFRONT2_a240_lowSideCompromised m3 : 63|1@1+ (1,0) [0|0] "" Vector__XXX
 SG_ VCFRONT2_a360_ungracefulAccPlusE m5 : 63|1@1+ (1,0) [0|0] "" Vector__XXX
 SG_ VCFRONT2_a420_holidayParty m6 : 63|1@1+ (1,0) [0|0] "" Vector__XXX
 SG_ VCFRONT2_a540_radiatorSteamDetec m8 : 63|1@1+ (1,0) [0|0] "" Vector__XXX
 SG_ VCFRONT2_a059_inputResistanceHig m0 : 62|1@1+ (1,0) [0|0] "" Vector__XXX
 SG_ VCFRONT2_a119_SCCM_MIA m1 : 62|1@1+ (1,0) [0|0] "" Vector__XXX
 SG_ VCFRONT2_a539_ccrExvCalibInitDeb m8 : 62|1@1+ (1,0) [0|0] "" Vector__XXX
 SG_ VCFRONT2_a058_inputRHighSyncDebu m0 : 61|1@1+ (1,0) [0|0] "" Vector__XXX
 SG_ VCFRONT2_a118_VCFRONT_MIA m1 : 61|1@1+ (1,0) [0|0] "" Vector__XXX
 SG_ VCFRONT2_a178_compLiquidPumpOut m2 : 61|1@1+ (1,0) [0|0] "" Vector__XXX
 SG_ VCFRONT2_a298_radiatorLowAirFlow m4 : 61|1@1+ (1,0) [0|0] "" Vector__XXX
 SG_ VCFRONT2_a538_cclExvCalibInitDeb m8 : 61|1@1+ (1,0) [0|0] "" Vector__XXX
 SG_ VCFRONT2_a117_VCLEFT_MIA m1 : 60|1@1+ (1,0) [0|0] "" Vector__XXX
 SG_ VCFRONT2_a537_lccExvCalibInitDeb m8 : 60|1@1+ (1,0) [0|0] "" Vector__XXX
 SG_ VCFRONT2_a116_VCRIGHT_MIA m1 : 59|1@1+ (1,0) [0|0] "" Vector__XXX
 SG_ VCFRONT2_a176_vehicleInSelfTest m2 : 59|1@1+ (1,0) [0|0] "" Vector__XXX
 SG_ VCFRONT2_a236_batTempSnsIrration m3 : 59|1@1+ (1,0) [0|0] "" Vector__XXX
 SG_ VCFRONT2_a356_refrigSysLockout m5 : 59|1@1+ (1,0) [0|0] "" Vector__XXX
 SG_ VCFRONT2_a536_recircExvCalibInit m8 : 59|1@1+ (1,0) [0|0] "" Vector__XXX
 SG_ VCFRONT2_a115_VCSEC_MIA m1 : 58|1@1+ (1,0) [0|0] "" Vector__XXX
 SG_ VCFRONT2_a235_ptTempSnsIrrationa m3 : 58|1@1+ (1,0) [0|0] "" Vector__XXX
 SG_ VCFRONT2_a355_coolantSysLockout m5 : 58|1@1+ (1,0) [0|0] "" Vector__XXX
 SG_ VCFRONT2_a535_evapExvCalibInitDe m8 : 58|1@1+ (1,0) [0|0] "" Vector__XXX
 SG_ VCFRONT2_a054_compressorLowFlowU m0 : 57|1@1+ (1,0) [0|0] "" Vector__XXX
 SG_ VCFRONT2_a114_ESP_MIA m1 : 57|1@1+ (1,0) [0|0] "" Vector__XXX
 SG_ VCFRONT2_a174_driveNotAuthed m2 : 57|1@1+ (1,0) [0|0] "" Vector__XXX
 SG_ VCFRONT2_a294_leftSideRepeaterLi m4 : 57|1@1+ (1,0) [0|0] "" Vector__XXX
 SG_ VCFRONT2_a474_leftHeadlampIntern m7 : 57|1@1+ (1,0) [0|0] "" Vector__XXX
 SG_ VCFRONT2_a534_chillerExvCalibIni m8 : 57|1@1+ (1,0) [0|0] "" Vector__XXX
 SG_ VCFRONT2_a053_wiperCommErrorUser m0 : 56|1@1+ (1,0) [0|0] "" Vector__XXX
 SG_ VCFRONT2_a113_UI_MIA m1 : 56|1@1+ (1,0) [0|0] "" Vector__XXX
 SG_ VCFRONT2_a173_HVBlckdByMsmtch m2 : 56|1@1+ (1,0) [0|0] "" Vector__XXX
 SG_ VCFRONT2_a112_EPBL_MIA m1 : 55|1@1+ (1,0) [0|0] "" Vector__XXX
 SG_ VCFRONT2_a172_wsteHtBlckdByMsmtc m2 : 55|1@1+ (1,0) [0|0] "" Vector__XXX
 SG_ VCFRONT2_a232_lowSideControllerH m3 : 55|1@1+ (1,0) [0|0] "" Vector__XXX
 SG_ VCFRONT2_a111_EPBR_MIA m1 : 54|1@1+ (1,0) [0|0] "" Vector__XXX
 SG_ VCFRONT2_a171_driveBlckdByMsmtch m2 : 54|1@1+ (1,0) [0|0] "" Vector__XXX
 SG_ VCFRONT2_a471_hcm5Debug m7 : 54|1@1+ (1,0) [0|0] "" Vector__XXX
 SG_ VCFRONT2_a531_lowPowerIndexFlagg m8 : 54|1@1+ (1,0) [0|0] "" Vector__XXX
 SG_ VCFRONT2_a110_GTW_MIA m1 : 53|1@1+ (1,0) [0|0] "" Vector__XXX
 SG_ VCFRONT2_a470_implausiblePdPlDet m7 : 53|1@1+ (1,0) [0|0] "" Vector__XXX
 SG_ VCFRONT2_a289_ccRightExvFault m4 : 52|1@1+ (1,0) [0|0] "" Vector__XXX
 SG_ VCFRONT2_a409_invalidConfigurati m6 : 52|1@1+ (1,0) [0|0] "" Vector__XXX
 SG_ VCFRONT2_a469_prvPopDetected m7 : 52|1@1+ (1,0) [0|0] "" Vector__XXX
 SG_ VCFRONT2_a108_DIF_MIA m1 : 51|1@1+ (1,0) [0|0] "" Vector__XXX
 SG_ VCFRONT2_a288_ccLeftExvFault m4 : 51|1@1+ (1,0) [0|0] "" Vector__XXX
 SG_ VCFRONT2_a468_highPowerIndexFlag m7 : 51|1@1+ (1,0) [0|0] "" Vector__XXX
 SG_ VCFRONT2_a107_BMS_MIA m1 : 50|1@1+ (1,0) [0|0] "" Vector__XXX
 SG_ VCFRONT2_a167_leftHCMMIA m2 : 50|1@1+ (1,0) [0|0] "" Vector__XXX
 SG_ VCFRONT2_a287_lccExvFault m4 : 50|1@1+ (1,0) [0|0] "" Vector__XXX
 SG_ VCFRONT2_a467_lowPowerIndexFlagg m7 : 50|1@1+ (1,0) [0|0] "" Vector__XXX
 SG_ VCFRONT2_a046_Task1000msError m0 : 49|1@1+ (1,0) [0|0] "" Vector__XXX
 SG_ VCFRONT2_a106_PCS_MIA m1 : 49|1@1+ (1,0) [0|0] "" Vector__XXX
 SG_ VCFRONT2_a226_battPumpMIA m3 : 49|1@1+ (1,0) [0|0] "" Vector__XXX
 SG_ VCFRONT2_a286_recircExvFault m4 : 49|1@1+ (1,0) [0|0] "" Vector__XXX
 SG_ VCFRONT2_a466_highFlowIndexLowSu m7 : 49|1@1+ (1,0) [0|0] "" Vector__XXX
 SG_ VCFRONT2_a045_Task100msError m0 : 48|1@1+ (1,0) [0|0] "" Vector__XXX
 SG_ VCFRONT2_a105_TAS_MIA m1 : 48|1@1+ (1,0) [0|0] "" Vector__XXX
 SG_ VCFRONT2_a225_driveBlckdByShowro m3 : 48|1@1+ (1,0) [0|0] "" Vector__XXX
 SG_ VCFRONT2_a285_evaporatorExvFault m4 : 48|1@1+ (1,0) [0|0] "" Vector__XXX
 SG_ VCFRONT2_a465_lowFlowIndexHighSu m7 : 48|1@1+ (1,0) [0|0] "" Vector__XXX
 SG_ VCFRONT2_a585_bothHeadlampsInter m9 : 48|1@1+ (1,0) [0|0] "" Vector__XXX
 SG_ VCFRONT2_a044_Task10msError m0 : 47|1@1+ (1,0) [0|0] "" Vector__XXX
 SG_ VCFRONT2_a104_DAS_MIA m1 : 47|1@1+ (1,0) [0|0] "" Vector__XXX
 SG_ VCFRONT2_a284_chillerExvFault m4 : 47|1@1+ (1,0) [0|0] "" Vector__XXX
 SG_ VCFRONT2_a464_highFlowIndexHighS m7 : 47|1@1+ (1,0) [0|0] "" Vector__XXX
 SG_ VCFRONT2_a043_Task1msError m0 : 46|1@1+ (1,0) [0|0] "" Vector__XXX
 SG_ VCFRONT2_a103_CP_MIA m1 : 46|1@1+ (1,0) [0|0] "" Vector__XXX
 SG_ VCFRONT2_a163_compressorDisabled m2 : 46|1@1+ (1,0) [0|0] "" Vector__XXX
 SG_ VCFRONT2_a283_thmlFanLimitedByCu m4 : 46|1@1+ (1,0) [0|0] "" Vector__XXX
 SG_ VCFRONT2_a042_HighStackUsage m0 : 45|1@1+ (1,0) [0|0] "" Vector__XXX
 SG_ VCFRONT2_a162_compressorInhibite m2 : 45|1@1+ (1,0) [0|0] "" Vector__XXX
 SG_ VCFRONT2_a282_coolantLevelSensor m4 : 45|1@1+ (1,0) [0|0] "" Vector__XXX
 SG_ VCFRONT2_a041_HighCPULoad m0 : 44|1@1+ (1,0) [0|0] "" Vector__XXX
 SG_ VCFRONT2_a161_compressorSelfFaul m2 : 44|1@1+ (1,0) [0|0] "" Vector__XXX
 SG_ VCFRONT2_a281_alcoholInterlockBl m4 : 44|1@1+ (1,0) [0|0] "" Vector__XXX
 SG_ VCFRONT2_a040_Backtrace m0 : 43|1@1+ (1,0) [0|0] "" Vector__XXX
 SG_ VCFRONT2_a100_CANbus_MIA m1 : 43|1@1+ (1,0) [0|0] "" Vector__XXX
 SG_ VCFRONT2_a160_compressorInhibite m2 : 43|1@1+ (1,0) [0|0] "" Vector__XXX
 SG_ VCFRONT2_a280_refrigLiquidPresSn m4 : 43|1@1+ (1,0) [0|0] "" Vector__XXX
 SG_ VCFRONT2_a460_hardIsentropicTdFa m7 : 43|1@1+ (1,0) [0|0] "" Vector__XXX
 SG_ VCFRONT2_a039_ProtFaultAddress m0 : 42|1@1+ (1,0) [0|0] "" Vector__XXX
 SG_ VCFRONT2_a159_coolantValveFault m2 : 42|1@1+ (1,0) [0|0] "" Vector__XXX
 SG_ VCFRONT2_a279_refrigLiquidTempSn m4 : 42|1@1+ (1,0) [0|0] "" Vector__XXX
 SG_ VCFRONT2_a459_thermalFillAndDriv m7 : 42|1@1+ (1,0) [0|0] "" Vector__XXX
 SG_ VCFRONT2_a038_ProtFaultInfo m0 : 41|1@1+ (1,0) [0|0] "" Vector__XXX
 SG_ VCFRONT2_a098_DIR_MIA m1 : 41|1@1+ (1,0) [0|0] "" Vector__XXX
 SG_ VCFRONT2_a218_socMonitorDetected m3 : 41|1@1+ (1,0) [0|0] "" Vector__XXX
 SG_ VCFRONT2_a398_tempSensorCheckInc m6 : 41|1@1+ (1,0) [0|0] "" Vector__XXX
 SG_ VCFRONT2_a458_grosslyLowRefriger m7 : 41|1@1+ (1,0) [0|0] "" Vector__XXX
 SG_ VCFRONT2_a578_vbusFusedLowCurren m9 : 41|1@1+ (1,0) [0|0] "" Vector__XXX
 SG_ VCFRONT2_a037_MemManageFault m0 : 40|1@1+ (1,0) [0|0] "" Vector__XXX
 SG_ VCFRONT2_a217_battPumpCompromise m3 : 40|1@1+ (1,0) [0|0] "" Vector__XXX
 SG_ VCFRONT2_a397_temperatureSensorC m6 : 40|1@1+ (1,0) [0|0] "" Vector__XXX
 SG_ VCFRONT2_a457_liquidTempSensInte m7 : 40|1@1+ (1,0) [0|0] "" Vector__XXX
 SG_ VCFRONT2_a697_leftHeadlampNotAim m11 : 40|1@1+ (1,0) [0|0] "" Vector__XXX
 SG_ VCFRONT2_a036_UnknownIrq m0 : 39|1@1+ (1,0) [0|0] "" Vector__XXX
 SG_ VCFRONT2_a096_OCS1P_MIA m1 : 39|1@1+ (1,0) [0|0] "" Vector__XXX
 SG_ VCFRONT2_a396_coolantLevelLowUse m6 : 39|1@1+ (1,0) [0|0] "" Vector__XXX
 SG_ VCFRONT2_a456_liquidPresSensInte m7 : 39|1@1+ (1,0) [0|0] "" Vector__XXX
 SG_ VCFRONT2_a155_autopilotDriveNotA m2 : 38|1@1+ (1,0) [0|0] "" Vector__XXX
 SG_ VCFRONT2_a215_ptPumpMIA m3 : 38|1@1+ (1,0) [0|0] "" Vector__XXX
 SG_ VCFRONT2_a395_pressureSensorChec m6 : 38|1@1+ (1,0) [0|0] "" Vector__XXX
 SG_ VCFRONT2_a455_suctionTempSensInt m7 : 38|1@1+ (1,0) [0|0] "" Vector__XXX
 SG_ VCFRONT2_a214_ptPumpCompromised m3 : 37|1@1+ (1,0) [0|0] "" Vector__XXX
 SG_ VCFRONT2_a394_pressureSensorChec m6 : 37|1@1+ (1,0) [0|0] "" Vector__XXX
 SG_ VCFRONT2_a454_suctionPresSensInt m7 : 37|1@1+ (1,0) [0|0] "" Vector__XXX
 SG_ VCFRONT2_a153_userPresenceDispla m2 : 36|1@1+ (1,0) [0|0] "" Vector__XXX
 SG_ VCFRONT2_a273_wiperFrictionModel m4 : 36|1@1+ (1,0) [0|0] "" Vector__XXX
 SG_ VCFRONT2_a393_ambientTempNetwork m6 : 36|1@1+ (1,0) [0|0] "" Vector__XXX
 SG_ VCFRONT2_a453_dischargeTempSensI m7 : 36|1@1+ (1,0) [0|0] "" Vector__XXX
 SG_ VCFRONT2_a452_dischargePresSensI m7 : 35|1@1+ (1,0) [0|0] "" Vector__XXX
 SG_ VCFRONT2_a572_hvacCompressorEFus m9 : 35|1@1+ (1,0) [0|0] "" Vector__XXX
 SG_ VCFRONT2_a031_UDSActive m0 : 34|1@1+ (1,0) [0|0] "" Vector__XXX
 SG_ VCFRONT2_a091_CMPD_MIA m1 : 34|1@1+ (1,0) [0|0] "" Vector__XXX
 SG_ VCFRONT2_a451_refrigerantNotComm m7 : 34|1@1+ (1,0) [0|0] "" Vector__XXX
 SG_ VCFRONT2_a511_DCDCSaturationLoad m8 : 34|1@1+ (1,0) [0|0] "" Vector__XXX
 SG_ VCFRONT2_a571_headlampsAdaptedTo m9 : 34|1@1+ (1,0) [0|0] "" Vector__XXX
 SG_ VCFRONT2_a030_ECULogUploadReques m0 : 33|1@1+ (1,0) [0|0] "" Vector__XXX
 SG_ VCFRONT2_a090_APS_MIA m1 : 33|1@1+ (1,0) [0|0] "" Vector__XXX
 SG_ VCFRONT2_a150_pumpBatLowRPMCBang m2 : 33|1@1+ (1,0) [0|0] "" Vector__XXX
 SG_ VCFRONT2_a210_coolantValveCalib m3 : 33|1@1+ (1,0) [0|0] "" Vector__XXX
 SG_ VCFRONT2_a570_headlampsAdaptedTo m9 : 33|1@1+ (1,0) [0|0] "" Vector__XXX
 SG_ VCFRONT2_a630_leftHeadlampFactor m10 : 33|1@1+ (1,0) [0|0] "" Vector__XXX
 SG_ VCFRONT2_a029_CoreDump m0 : 32|1@1+ (1,0) [0|0] "" Vector__XXX
 SG_ VCFRONT2_a028_UsageFault m0 : 31|1@1+ (1,0) [0|0] "" Vector__XXX
 SG_ VCFRONT2_a568_leftDaytimeRunning m9 : 31|1@1+ (1,0) [0|0] "" Vector__XXX
 SG_ VCFRONT2_a447_cabinHVACUnavailab m7 : 30|1@1+ (1,0) [0|0] "" Vector__XXX
 SG_ VCFRONT2_a507_leftHeadlampAiming m8 : 30|1@1+ (1,0) [0|0] "" Vector__XXX
 SG_ VCFRONT2_a086_VCBATT_MIA m1 : 29|1@1+ (1,0) [0|0] "" Vector__XXX
 SG_ VCFRONT2_a386_exvMotorWarning m6 : 29|1@1+ (1,0) [0|0] "" Vector__XXX
 SG_ VCFRONT2_a446_cabinHVACUnavailab m7 : 29|1@1+ (1,0) [0|0] "" Vector__XXX
 SG_ VCFRONT2_a506_invalidRefrigerant m8 : 29|1@1+ (1,0) [0|0] "" Vector__XXX
 SG_ VCFRONT2_a566_leftFrontTurnLight m9 : 29|1@1+ (1,0) [0|0] "" Vector__XXX
 SG_ VCFRONT2_a385_ccRightExvWarning m6 : 28|1@1+ (1,0) [0|0] "" Vector__XXX
 SG_ VCFRONT2_a565_userPresenceDispla m9 : 28|1@1+ (1,0) [0|0] "" Vector__XXX
 SG_ VCFRONT2_a144_EPAS3S_MIA m2 : 27|1@1+ (1,0) [0|0] "" Vector__XXX
 SG_ VCFRONT2_a384_ccLeftExvWarning m6 : 27|1@1+ (1,0) [0|0] "" Vector__XXX
 SG_ VCFRONT2_a504_airInRefrigerantDe m8 : 27|1@1+ (1,0) [0|0] "" Vector__XXX
 SG_ VCFRONT2_a564_leftHeadlampAiming m9 : 27|1@1+ (1,0) [0|0] "" Vector__XXX
 SG_ VCFRONT2_a143_powerLossDuringSle m2 : 26|1@1+ (1,0) [0|0] "" Vector__XXX
 SG_ VCFRONT2_a383_lccExvWarning m6 : 26|1@1+ (1,0) [0|0] "" Vector__XXX
 SG_ VCFRONT2_a563_chargePortDoorOpen m9 : 26|1@1+ (1,0) [0|0] "" Vector__XXX
 SG_ VCFRONT2_a022_TaskInitError m0 : 25|1@1+ (1,0) [0|0] "" Vector__XXX
 SG_ VCFRONT2_a082_VCFRONT2_MIA m1 : 25|1@1+ (1,0) [0|0] "" Vector__XXX
 SG_ VCFRONT2_a142_exvMotorFault m2 : 25|1@1+ (1,0) [0|0] "" Vector__XXX
 SG_ VCFRONT2_a382_recircExvWarning m6 : 25|1@1+ (1,0) [0|0] "" Vector__XXX
 SG_ VCFRONT2_a622_pumpDetectsLowCool m10 : 25|1@1+ (1,0) [0|0] "" Vector__XXX
 SG_ VCFRONT2_a021_TaskSchedulerError m0 : 24|1@1+ (1,0) [0|0] "" Vector__XXX
 SG_ VCFRONT2_a081_VCFRONT1_MIA m1 : 24|1@1+ (1,0) [0|0] "" Vector__XXX
 SG_ VCFRONT2_a141_coolantTempBatSns m2 : 24|1@1+ (1,0) [0|0] "" Vector__XXX
 SG_ VCFRONT2_a381_evaporatorExvWarni m6 : 24|1@1+ (1,0) [0|0] "" Vector__XXX
 SG_ VCFRONT2_a621_coolantAirPurgeInc m10 : 24|1@1+ (1,0) [0|0] "" Vector__XXX
 SG_ VCFRONT2_a080_VCFRONT0_MIA m1 : 23|1@1+ (1,0) [0|0] "" Vector__XXX
 SG_ VCFRONT2_a140_coolantTempPtSns m2 : 23|1@1+ (1,0) [0|0] "" Vector__XXX
 SG_ VCFRONT2_a380_chillerExvWarning m6 : 23|1@1+ (1,0) [0|0] "" Vector__XXX
 SG_ VCFRONT2_a560_compressorHighSupe m9 : 23|1@1+ (1,0) [0|0] "" Vector__XXX
 SG_ VCFRONT2_a620_pumpAirLock m10 : 23|1@1+ (1,0) [0|0] "" Vector__XXX
 SG_ VCFRONT2_a019_BusFault m0 : 22|1@1+ (1,0) [0|0] "" Vector__XXX
 SG_ VCFRONT2_a079_VCBATT2_MIA m1 : 22|1@1+ (1,0) [0|0] "" Vector__XXX
 SG_ VCFRONT2_a139_refrigSuctPresSns m2 : 22|1@1+ (1,0) [0|0] "" Vector__XXX
 SG_ VCFRONT2_a499_loadShedPumpFlowRe m8 : 22|1@1+ (1,0) [0|0] "" Vector__XXX
 SG_ VCFRONT2_a018_HardFault m0 : 21|1@1+ (1,0) [0|0] "" Vector__XXX
 SG_ VCFRONT2_a078_VCBATT1_MIA m1 : 21|1@1+ (1,0) [0|0] "" Vector__XXX
 SG_ VCFRONT2_a138_refrigSuctTempSns m2 : 21|1@1+ (1,0) [0|0] "" Vector__XXX
 SG_ VCFRONT2_a378_wiperECUDebug m6 : 21|1@1+ (1,0) [0|0] "" Vector__XXX
 SG_ VCFRONT2_a618_cabinCoolingCapaci m10 : 21|1@1+ (1,0) [0|0] "" Vector__XXX
 SG_ VCFRONT2_a017_NVMMStatusDbg m0 : 20|1@1+ (1,0) [0|0] "" Vector__XXX
 SG_ VCFRONT2_a077_VCBATT0_MIA m1 : 20|1@1+ (1,0) [0|0] "" Vector__XXX
 SG_ VCFRONT2_a137_refrigDischPresSns m2 : 20|1@1+ (1,0) [0|0] "" Vector__XXX
 SG_ VCFRONT2_a377_wiperParkFault m6 : 20|1@1+ (1,0) [0|0] "" Vector__XXX
 SG_ VCFRONT2_a617_APP_MIA m10 : 20|1@1+ (1,0) [0|0] "" Vector__XXX
 SG_ VCFRONT2_a016_NVMMRecordError m0 : 19|1@1+ (1,0) [0|0] "" Vector__XXX
 SG_ VCFRONT2_a136_refrigDischTempSns m2 : 19|1@1+ (1,0) [0|0] "" Vector__XXX
 SG_ VCFRONT2_a015_NVMMError m0 : 18|1@1+ (1,0) [0|0] "" Vector__XXX
 SG_ VCFRONT2_a135_coolantLevelLow m2 : 18|1@1+ (1,0) [0|0] "" Vector__XXX
 SG_ VCFRONT2_a195_drveBlckdVltgeTooH m3 : 18|1@1+ (1,0) [0|0] "" Vector__XXX
 SG_ VCFRONT2_a254_pumpBatStopped m4 : 17|1@1+ (1,0) [0|0] "" Vector__XXX
 SG_ VCFRONT2_a374_lccInletSolenoidFa m6 : 17|1@1+ (1,0) [0|0] "" Vector__XXX
 SG_ VCFRONT2_a614_coolantSysDriverle m10 : 17|1@1+ (1,0) [0|0] "" Vector__XXX
 SG_ VCFRONT2_a013_AlertManagerFault m0 : 16|1@1+ (1,0) [0|0] "" Vector__XXX
 SG_ VCFRONT2_a133_BRAKE_MIA m2 : 16|1@1+ (1,0) [0|0] "" Vector__XXX
 SG_ VCFRONT2_a012_CPUReset m0 : 15|1@1+ (1,0) [0|0] "" Vector__XXX
 SG_ VCFRONT2_a612_selfTestsBlockingD m10 : 15|1@1+ (1,0) [0|0] "" Vector__XXX
 SG_ VCFRONT2_a131_PCSCOMMON_MIA m2 : 14|1@1+ (1,0) [0|0] "" Vector__XXX
 SG_ VCFRONT2_a251_UIWakeupTrigger m4 : 14|1@1+ (1,0) [0|0] "" Vector__XXX
 SG_ VCFRONT2_a611_poorRadiatorHeatRe m10 : 14|1@1+ (1,0) [0|0] "" Vector__XXX
 SG_ VCFRONT2_a250_headlampsNotAimed m4 : 13|1@1+ (1,0) [0|0] "" Vector__XXX
 SG_ VCFRONT2_a490_coolantPumpsNotIde m8 : 13|1@1+ (1,0) [0|0] "" Vector__XXX
 SG_ VCFRONT2_a610_driveEntryDelayed m10 : 13|1@1+ (1,0) [0|0] "" Vector__XXX
 SG_ VCFRONT2_a009_LCCPurgeAttempted m0 : 12|1@1+ (1,0) [0|0] "" Vector__XXX
 SG_ VCFRONT2_a249_coolantValveBadMod m4 : 12|1@1+ (1,0) [0|0] "" Vector__XXX
 SG_ VCFRONT2_a369_reducedPowerDischa m6 : 12|1@1+ (1,0) [0|0] "" Vector__XXX
 SG_ VCFRONT2_a489_ValveStuckFlagged m8 : 12|1@1+ (1,0) [0|0] "" Vector__XXX
 SG_ VCFRONT2_a669_thermalHVPowerBudg m11 : 12|1@1+ (1,0) [0|0] "" Vector__XXX
 SG_ VCFRONT2_a008_adaptiveHeadlights m0 : 11|1@1+ (1,0) [0|0] "" Vector__XXX
 SG_ VCFRONT2_a188_sleepFailed m3 : 11|1@1+ (1,0) [0|0] "" Vector__XXX
 SG_ VCFRONT2_a368_dischargeRoutineEx m6 : 11|1@1+ (1,0) [0|0] "" Vector__XXX
 SG_ VCFRONT2_a187_busesNotSleeping m3 : 10|1@1+ (1,0) [0|0] "" Vector__XXX
 SG_ VCFRONT2_a247_evapSolenoidFault m4 : 10|1@1+ (1,0) [0|0] "" Vector__XXX
 SG_ VCFRONT2_a367_dischargeRoutineEn m6 : 10|1@1+ (1,0) [0|0] "" Vector__XXX
 SG_ VCFRONT2_a667_leftHeadlampRegion m11 : 10|1@1+ (1,0) [0|0] "" Vector__XXX
 SG_ VCFRONT2_a006_CANTX_cyclicError m0 : 9|1@1+ (1,0) [0|0] "" Vector__XXX
 SG_ VCFRONT2_a126_EPAS3P_MIA m2 : 9|1@1+ (1,0) [0|0] "" Vector__XXX
 SG_ VCFRONT2_a186_noDriveChgCableCon m3 : 9|1@1+ (1,0) [0|0] "" Vector__XXX
 SG_ VCFRONT2_a366_burnInRoutineExite m6 : 9|1@1+ (1,0) [0|0] "" Vector__XXX
 SG_ VCFRONT2_a546_leftLowOrHighBeamL m9 : 9|1@1+ (1,0) [0|0] "" Vector__XXX
 SG_ VCFRONT2_a606_chillerBattHeating m10 : 9|1@1+ (1,0) [0|0] "" Vector__XXX
 SG_ VCFRONT2_a005_CANTXError m0 : 8|1@1+ (1,0) [0|0] "" Vector__XXX
 SG_ VCFRONT2_a125_SCCM_MIA m2 : 8|1@1+ (1,0) [0|0] "" Vector__XXX
 SG_ VCFRONT2_a365_burnInRoutineEnter m6 : 8|1@1+ (1,0) [0|0] "" Vector__XXX
 SG_ VCFRONT2_a665_leftHeadlampRetryI m11 : 8|1@1+ (1,0) [0|0] "" Vector__XXX
 SG_ VCFRONT2_a064_busSleepReqTimeout m1 : 7|1@1+ (1,0) [0|0] "" Vector__XXX
 SG_ VCFRONT2_a124_BB_MIA m2 : 7|1@1+ (1,0) [0|0] "" Vector__XXX
 SG_ VCFRONT2_a184_cabinCoolingPerfor m3 : 7|1@1+ (1,0) [0|0] "" Vector__XXX
 SG_ VCFRONT2_a003_SWAssertion m0 : 6|1@1+ (1,0) [0|0] "" Vector__XXX
 SG_ VCFRONT2_a063_SwitchFault m1 : 6|1@1+ (1,0) [0|0] "" Vector__XXX
 SG_ VCFRONT2_a123_VC_SECONDARY_LIGHT m2 : 6|1@1+ (1,0) [0|0] "" Vector__XXX
 SG_ VCFRONT2_a423_rtosSleepFailed m7 : 6|1@1+ (1,0) [0|0] "" Vector__XXX
 SG_ VCFRONT2_a543_compressorLowFlowD m9 : 6|1@1+ (1,0) [0|0] "" Vector__XXX
 SG_ VCFRONT2_a663_leftHeadlampUartWa m11 : 6|1@1+ (1,0) [0|0] "" Vector__XXX
 SG_ VCFRONT2_a002_PowerLossReset m0 : 5|1@1+ (1,0) [0|0] "" Vector__XXX
 SG_ VCFRONT2_a062_XCPWasConnected m1 : 5|1@1+ (1,0) [0|0] "" Vector__XXX
 SG_ VCFRONT2_a122_ICR_MIA m2 : 5|1@1+ (1,0) [0|0] "" Vector__XXX
 SG_ VCFRONT2_a302_wiperCommError m5 : 5|1@1+ (1,0) [0|0] "" Vector__XXX
 SG_ VCFRONT2_a542_refrigerantReclaim m9 : 5|1@1+ (1,0) [0|0] "" Vector__XXX
 SG_ VCFRONT2_a001_WatchdogReset m0 : 4|1@1+ (1,0) [0|0] "" Vector__XXX
 SG_ VCFRONT2_a061_XCPConnected m1 : 4|1@1+ (1,0) [0|0] "" Vector__XXX
 SG_ VCFRONT2_a301_wipersFactoryDisab m5 : 4|1@1+ (1,0) [0|0] "" Vector__XXX
 SG_ VCFRONT2_a421_leftHeadlampUartCo m7 : 4|1@1+ (1,0) [0|0] "" Vector__XXX
 SG_ VCFRONT2_a601_autopilotAirPurgeL m10 : 4|1@1+ (1,0) [0|0] "" Vector__XXX
 SG_ VCFRONT2_a661_mculessLeftHeadlam m11 : 4|1@1+ (1,0) [0|0] "" Vector__XXX
 SG_ VCFRONT2_matrixIndex M : 0|4@1+ (1,0) [0|0] "" Vector__XXX

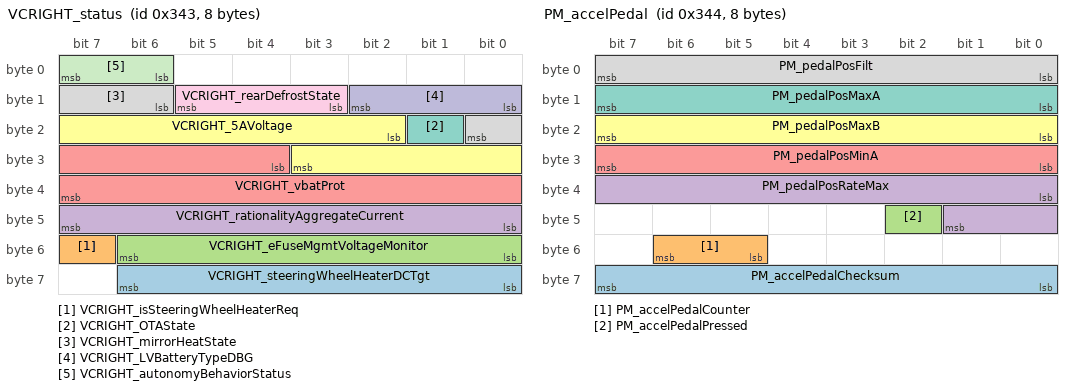
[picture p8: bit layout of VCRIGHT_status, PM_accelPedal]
BO_ 835 VCRIGHT_status: 8 Vector__XXX
 SG_ VCRIGHT_steeringWheelHeaterDCTgt : 56|7@1+ (0.01,0) [0|0] "" Vector__XXX
 SG_ VCRIGHT_isSteeringWheelHeaterReq : 55|1@1+ (1,0) [0|0] "" Vector__XXX
 SG_ VCRIGHT_eFuseMgmtVoltageMonitor : 48|7@1+ (0.125,0) [0|0] "" Vector__XXX
 SG_ VCRIGHT_rationalityAggregateCurrent : 40|8@1+ (0.5,0) [0|0] "" Vector__XXX
 SG_ VCRIGHT_vbatProt : 28|12@1+ (0.005443676098,0) [0|0] "" Vector__XXX
 SG_ VCRIGHT_5AVoltage : 18|10@1+ (0.005443676098,0) [0|0] "" Vector__XXX
 SG_ VCRIGHT_OTAState : 17|1@1+ (1,0) [0|0] "" Vector__XXX
 SG_ VCRIGHT_mirrorHeatState : 14|3@1+ (1,0) [0|0] "" Vector__XXX
 SG_ VCRIGHT_rearDefrostState : 11|3@1+ (1,0) [0|0] "" Vector__XXX
 SG_ VCRIGHT_LVBatteryTypeDBG : 8|3@1+ (1,0) [0|0] "" Vector__XXX
 SG_ VCRIGHT_autonomyBehaviorStatus : 6|2@1+ (1,0) [0|0] "" Vector__XXX

BO_ 836 PM_accelPedal: 8 Vector__XXX
 SG_ PM_accelPedalChecksum : 56|8@1+ (1,0) [0|0] "" Vector__XXX
 SG_ PM_accelPedalCounter : 53|2@1+ (1,0) [0|0] "" Vector__XXX
 SG_ PM_accelPedalPressed : 42|1@1+ (1,0) [0|0] "" Vector__XXX
 SG_ PM_pedalPosRateMax : 32|10@1+ (3,0) [0|0] "" Vector__XXX
 SG_ PM_pedalPosMinA : 24|8@1+ (0.4,0) [0|0] "" Vector__XXX
 SG_ PM_pedalPosMaxB : 16|8@1+ (0.4,0) [0|0] "" Vector__XXX
 SG_ PM_pedalPosMaxA : 8|8@1+ (0.4,0) [0|0] "" Vector__XXX
 SG_ PM_pedalPosFilt : 0|8@1+ (0.4,0) [0|0] "" Vector__XXX

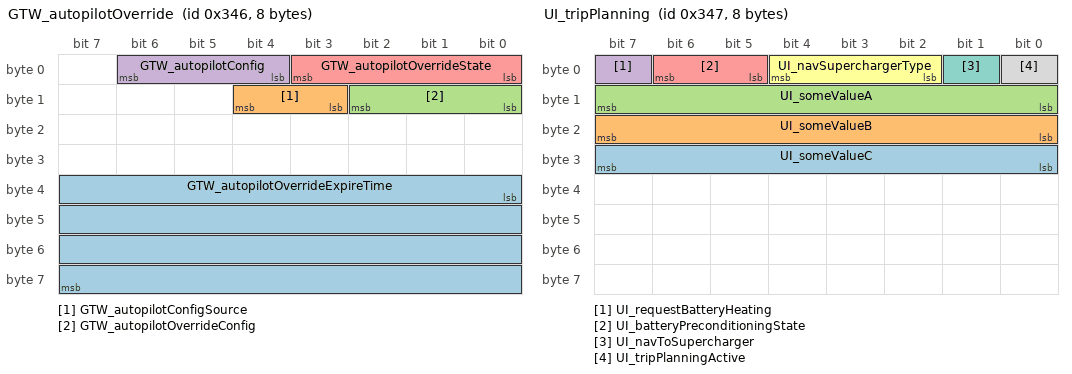
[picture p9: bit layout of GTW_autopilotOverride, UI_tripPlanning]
BO_ 838 GTW_autopilotOverride: 8 Vector__XXX
 SG_ GTW_autopilotOverrideExpireTime : 32|32@1+ (1,0) [0|0] "" Vector__XXX
 SG_ GTW_autopilotConfigSource : 11|2@1+ (1,0) [0|0] "" Vector__XXX
 SG_ GTW_autopilotOverrideConfig : 8|3@1+ (1,0) [0|0] "" Vector__XXX
 SG_ GTW_autopilotConfig : 4|3@1+ (1,0) [0|0] "" Vector__XXX
 SG_ GTW_autopilotOverrideState : 0|4@1+ (1,0) [0|0] "" Vector__XXX

BO_ 839 UI_tripPlanning: 8 VEH
 SG_ UI_someValueC : 24|8@1+ (1,0) [0|255] ""  X
 SG_ UI_someValueB : 16|8@1+ (1,0) [0|255] ""  X
 SG_ UI_someValueA : 8|8@1+ (1,0) [0|255] ""  X
 SG_ UI_requestBatteryHeating : 7|1@1+ (1,0) [0|1] ""  X
 SG_ UI_batteryPreconditioningState : 5|2@1+ (1,0) [0|3] ""  X
 SG_ UI_navSuperchargerType : 2|3@1+ (1,0) [0|7] ""  X
 SG_ UI_navToSupercharger : 1|1@1+ (1,0) [0|1] ""  X
 SG_ UI_tripPlanningActive : 0|1@1+ (1,0) [0|1] ""  X

BO_ 842 VCSEC_NFCDebug: 8 Vector__XXX
 SG_ VCSEC_BPillarNFCStateReasonL m0 : 60|3@1+ (1,0) [0|0] "" Vector__XXX
 SG_ VCSEC_BPillarNFCStateReasonR m1 : 60|3@1+ (1,0) [0|0] "" Vector__XXX
 SG_ VCSEC_CenterNFCStateReason m2 : 60|4@1+ (1,0) [0|0] "" Vector__XXX
 SG_ VCSEC_BPillarNFCAntennaCalResultL m0 : 52|8@1+ (1,0) [0|0] "" Vector__XXX
 SG_ VCSEC_BPillarNFCAntennaCalResultR m1 : 52|8@1+ (1,0) [0|0] "" Vector__XXX
 SG_ VCSEC_CenterNFCAntennaCalResult m2 : 52|8@1+ (1,0) [0|0] "" Vector__XXX
 SG_ VCSEC_BPillarNFCDevLayerStateL m0 : 44|8@1+ (1,0) [0|0] "" Vector__XXX
 SG_ VCSEC_BPillarNFCDevLayerStateR m1 : 44|8@1+ (1,0) [0|0] "" Vector__XXX
 SG_ VCSEC_CenterNFCDevLayerState m2 : 44|8@1+ (1,0) [0|0] "" Vector__XXX
 SG_ VCSEC_BPillarNFCAmplitudeL m0 : 36|8@1+ (1,0) [0|0] "" Vector__XXX
 SG_ VCSEC_BPillarNFCAmplitudeR m1 : 36|8@1+ (1,0) [0|0] "" Vector__XXX
 SG_ VCSEC_CenterNFCAmplitude m2 : 36|8@1+ (1,0) [0|0] "" Vector__XXX
 SG_ VCSEC_BPillarNFCReaderStateL m0 : 28|2@1+ (1,0) [0|0] "" Vector__XXX
 SG_ VCSEC_BPillarNFCReaderStateR m1 : 28|2@1+ (1,0) [0|0] "" Vector__XXX
 SG_ VCSEC_CenterNFCReaderState m2 : 28|2@1+ (1,0) [0|0] "" Vector__XXX
 SG_ VCSEC_CenterNFCPhase m3 : 19|8@1+ (1,0) [0|0] "" Vector__XXX
 SG_ VCSEC_BPillarNFCWakeUpCounterL m0 : 12|16@1+ (1,0) [0|0] "" Vector__XXX
 SG_ VCSEC_BPillarNFCWakeUpCounterR m1 : 12|16@1+ (1,0) [0|0] "" Vector__XXX
 SG_ VCSEC_CenterNFCCardATQa m2 : 12|16@1+ (1,0) [0|0] "" Vector__XXX
 SG_ VCSEC_BPillarNFCPhaseR m3 : 11|8@1+ (1,0) [0|0] "" Vector__XXX
 SG_ VCSEC_BPillarNFCTrimSettingL m0 : 8|4@1+ (1,0) [0|0] "" Vector__XXX
 SG_ VCSEC_BPillarNFCTrimSettingR m1 : 8|4@1+ (1,0) [0|0] "" Vector__XXX
 SG_ VCSEC_CenterNFCTrimSetting m2 : 8|4@1+ (1,0) [0|0] "" Vector__XXX
 SG_ VCSEC_BPillarNFCCardUIDSizeL m0 : 4|4@1+ (1,0) [0|0] "" Vector__XXX
 SG_ VCSEC_BPillarNFCCardUIDSizeR m1 : 4|4@1+ (1,0) [0|0] "" Vector__XXX
 SG_ VCSEC_CenterNFCCardUIDSize m2 : 4|4@1+ (1,0) [0|0] "" Vector__XXX
 SG_ VCSEC_BPillarNFCCardCollisionL m0 : 3|1@1+ (1,0) [0|0] "" Vector__XXX
 SG_ VCSEC_BPillarNFCCardCollisionR m1 : 3|1@1+ (1,0) [0|0] "" Vector__XXX
 SG_ VCSEC_BPillarNFCPhaseL m3 : 3|8@1+ (1,0) [0|0] "" Vector__XXX
 SG_ VCSEC_CenterNFCCardCollision m2 : 3|1@1+ (1,0) [0|0] "" Vector__XXX
 SG_ VCSEC_NFCReaderIndexDebug M : 0|2@1+ (1,0) [0|0] "" Vector__XXX

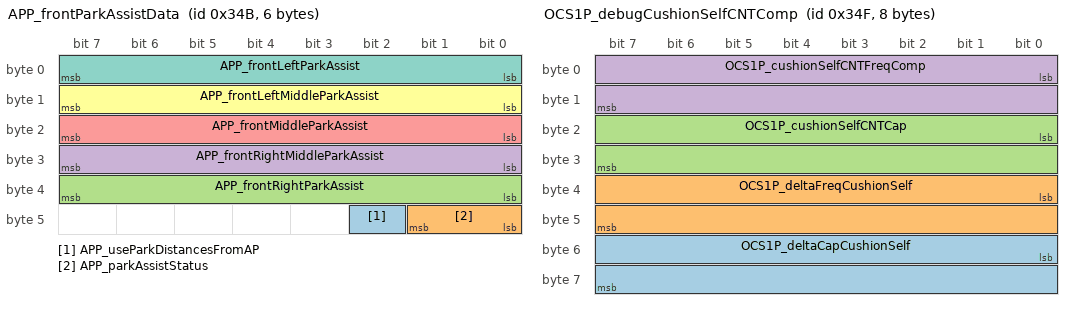
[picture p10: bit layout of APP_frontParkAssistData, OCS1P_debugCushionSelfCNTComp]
BO_ 843 APP_frontParkAssistData: 6 Vector__XXX
 SG_ APP_useParkDistancesFromAP : 42|1@1+ (1,0) [0|0] "" Vector__XXX
 SG_ APP_parkAssistStatus : 40|2@1+ (1,0) [0|0] "" Vector__XXX
 SG_ APP_frontRightParkAssist : 32|8@1+ (1,0) [0|0] "" Vector__XXX
 SG_ APP_frontRightMiddleParkAssist : 24|8@1+ (1,0) [0|0] "" Vector__XXX
 SG_ APP_frontMiddleParkAssist : 16|8@1+ (1,0) [0|0] "" Vector__XXX
 SG_ APP_frontLeftMiddleParkAssist : 8|8@1+ (1,0) [0|0] "" Vector__XXX
 SG_ APP_frontLeftParkAssist : 0|8@1+ (1,0) [0|0] "" Vector__XXX

BO_ 847 OCS1P_debugCushionSelfCNTComp: 8 Vector__XXX
 SG_ OCS1P_deltaCapCushionSelf : 48|16@1- (0.0025,0) [0|0] "" Vector__XXX
 SG_ OCS1P_deltaFreqCushionSelf : 32|16@1- (1,0) [0|0] "" Vector__XXX
 SG_ OCS1P_cushionSelfCNTCap : 16|16@1+ (0.005,0) [0|0] "" Vector__XXX
 SG_ OCS1P_cushionSelfCNTFreqComp : 0|16@1+ (1,0) [0|0] "" Vector__XXX

BO_ 852 UI_uiHealthStatus: 6 Vector__XXX
 SG_ UI_rearDisplayCompositorOk : 31|1@1+ (1,0) [0|0] "" Vector__XXX
 SG_ UI_rearDisplayWindowManagerOk : 30|1@1+ (1,0) [0|0] "" Vector__XXX
 SG_ UI_rearDisplayHardwareOk : 29|1@1+ (1,0) [0|0] "" Vector__XXX
 SG_ UI_rearDisplayCrtcOk : 28|1@1+ (1,0) [0|0] "" Vector__XXX
 SG_ UI_rearDisplaySM : 25|3@1+ (1,0) [0|0] "" Vector__XXX
 SG_ UI_rearDisplayPowerOn : 24|1@1+ (1,0) [0|0] "" Vector__XXX
 SG_ UI_rearDisplayRunning : 23|1@1+ (1,0) [0|0] "" Vector__XXX
 SG_ UI_autonomyDASServerStatus : 21|2@1+ (1,0) [0|0] "" Vector__XXX
 SG_ UI_autonomyQtCarRearStatus : 19|2@1+ (1,0) [0|0] "" Vector__XXX
 SG_ UI_autonomyQtCarStatus : 17|2@1+ (1,0) [0|0] "" Vector__XXX
 SG_ UI_autonomyConnectivtyHWOk : 16|1@1+ (1,0) [0|0] "" Vector__XXX
 SG_ UI_autonomyConnectivityStatus : 14|2@1+ (1,0) [0|0] "" Vector__XXX
 SG_ UI_autonomyRearDispStatus : 12|2@1+ (1,0) [0|0] "" Vector__XXX
 SG_ UI_autonomyCenterDispStatus : 10|2@1+ (1,0) [0|0] "" Vector__XXX
 SG_ UI_apVisualizationOk : 9|1@1+ (1,0) [0|0] "" Vector__XXX
 SG_ UI_centerDisplayCompositorOk : 8|1@1+ (1,0) [0|0] "" Vector__XXX
 SG_ UI_centerDisplayWindowManagerOk : 7|1@1+ (1,0) [0|0] "" Vector__XXX
 SG_ UI_centerDisplayHardwareOk : 6|1@1+ (1,0) [0|0] "" Vector__XXX
 SG_ UI_centerDisplayCrtcOk : 5|1@1+ (1,0) [0|0] "" Vector__XXX
 SG_ UI_centerDisplayPowerOn : 4|1@1+ (1,0) [0|0] "" Vector__XXX
 SG_ UI_centerDisplaySM : 1|3@1+ (1,0) [0|0] "" Vector__XXX
 SG_ UI_centerDisplayRunning : 0|1@1+ (1,0) [0|0] "" Vector__XXX

BO_ 853 UI_vehicleControlThermal: 7 Vector__XXX
 SG_ UI_enableAutopilotAirPurge : 49|1@1+ (1,0) [0|0] "" Vector__XXX
 SG_ UI_enableHVACAPFanHeaterControl : 48|1@1+ (1,0) [0|0] "" Vector__XXX
 SG_ UI_enableThermalPowerBudget : 46|1@1+ (1,0) [0|0] "" Vector__XXX
 SG_ UI_isAtTeslaFacility : 45|1@1+ (1,0) [0|0] "" Vector__XXX
 SG_ UI_disablePhoneChargingPads : 43|1@1+ (1,0) [0|0] "" Vector__XXX
 SG_ UI_enableHVACCompressorWasteHeat : 42|1@1+ (1,0) [0|0] "" Vector__XXX
 SG_ UI_enableDefaultApTempTarget : 41|1@1+ (1,0) [0|0] "" Vector__XXX
 SG_ UI_enableConservativeBatteryHeating : 40|1@1+ (1,0) [0|0] "" Vector__XXX
 SG_ UI_allowConvenienceFeatures : 39|1@1+ (1,0) [0|0] "" Vector__XXX
 SG_ UI_convenienceFeatureLimit : 32|7@1+ (1,0) [0|0] "" Vector__XXX
 SG_ UI_geofencedLiftgateHeight : 24|8@1+ (1,0) [0|0] "" Vector__XXX
 SG_ UI_enableCoolantDasTarget : 23|1@1+ (1,0) [0|0] "" Vector__XXX
 SG_ UI_enableThermalDriverlessSelfTest : 22|1@1+ (1,0) [0|0] "" Vector__XXX
 SG_ UI_enableEXVFastCalibration : 21|1@1+ (1,0) [0|0] "" Vector__XXX
 SG_ UI_disableHvacCameraOnlyDefog : 20|1@1+ (1,0) [0|0] "" Vector__XXX
 SG_ UI_enableUserFacingLowFlowDeliveryAlert : 19|1@1+ (1,0) [0|0] "" Vector__XXX
 SG_ UI_enableLouverAutoDetection : 18|1@1+ (1,0) [0|0] "" Vector__XXX
 SG_ UI_enableCOP1CabinHeatingBatteryHeating : 17|1@1+ (1,0) [0|0] "" Vector__XXX
 SG_ UI_enableCOP1BatteryHeating : 16|1@1+ (1,0) [0|0] "" Vector__XXX
 SG_ UI_enableIncreasedEvapRampRate : 15|1@1+ (1,0) [0|0] "" Vector__XXX
 SG_ UI_enableCOP1HighSHOperation : 14|1@1+ (1,0) [0|0] "" Vector__XXX
 SG_ UI_enableCompLiquidPumpOut : 13|1@1+ (1,0) [0|0] "" Vector__XXX
 SG_ UI_disableHVPTThermalLoads : 12|1@1+ (1,0) [0|0] "" Vector__XXX
 SG_ UI_inletActiveCoolTarget : 5|7@1+ (1,0) [0|0] "" Vector__XXX
 SG_ UI_coolantFlowRequest : 0|5@1+ (1,0) [0|0] "" Vector__XXX

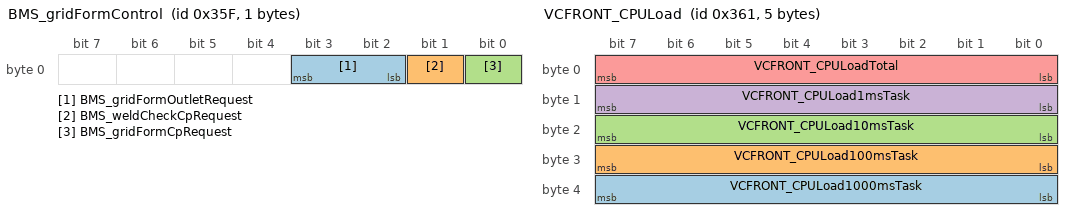
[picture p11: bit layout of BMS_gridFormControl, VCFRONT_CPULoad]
BO_ 863 BMS_gridFormControl: 1 Vector__XXX
 SG_ BMS_gridFormOutletRequest : 2|2@1+ (1,0) [0|0] "" Vector__XXX
 SG_ BMS_weldCheckCpRequest : 1|1@1+ (1,0) [0|0] "" Vector__XXX
 SG_ BMS_gridFormCpRequest : 0|1@1+ (1,0) [0|0] "" Vector__XXX

BO_ 865 VCFRONT_CPULoad: 5 Vector__XXX
 SG_ VCFRONT_CPULoad1000msTask : 32|8@1+ (1,0) [0|0] "" Vector__XXX
 SG_ VCFRONT_CPULoad100msTask : 24|8@1+ (1,0) [0|0] "" Vector__XXX
 SG_ VCFRONT_CPULoad10msTask : 16|8@1+ (1,0) [0|0] "" Vector__XXX
 SG_ VCFRONT_CPULoad1msTask : 8|8@1+ (1,0) [0|0] "" Vector__XXX
 SG_ VCFRONT_CPULoadTotal : 0|8@1+ (1,0) [0|0] "" Vector__XXX

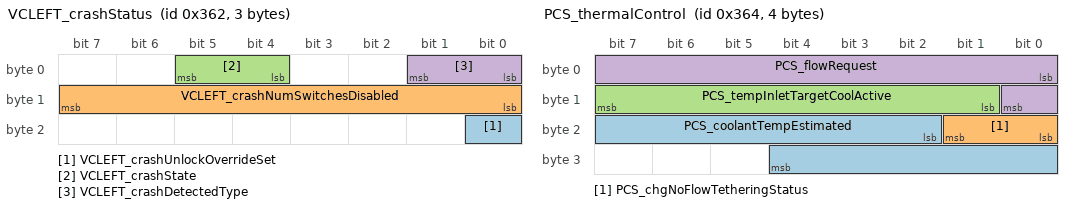
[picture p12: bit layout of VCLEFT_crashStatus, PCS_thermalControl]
BO_ 866 VCLEFT_crashStatus: 3 Vector__XXX
 SG_ VCLEFT_crashUnlockOverrideSet : 16|1@1+ (1,0) [0|0] "" Vector__XXX
 SG_ VCLEFT_crashNumSwitchesDisabled : 8|8@1+ (1,0) [0|0] "" Vector__XXX
 SG_ VCLEFT_crashState : 4|2@1+ (1,0) [0|0] "" Vector__XXX
 SG_ VCLEFT_crashDetectedType : 0|2@1+ (1,0) [0|0] "" Vector__XXX

BO_ 868 PCS_thermalControl: 4 Vector__XXX
 SG_ PCS_coolantTempEstimated : 18|11@1- (0.1,40) [0|0] "" Vector__XXX
 SG_ PCS_chgNoFlowTetheringStatus : 16|2@1+ (1,0) [0|0] "" Vector__XXX
 SG_ PCS_tempInletTargetCoolActive : 9|7@1+ (1,0) [0|0] "" Vector__XXX
 SG_ PCS_flowRequest : 0|9@1+ (0.1,0) [0|0] "" Vector__XXX

BO_ 870 CMPD_info: 8 Vector__XXX
 SG_ CMPD_infoComponentId m10 : 48|16@1+ (1,0) [0|0] "" Vector__XXX
 SG_ CMPD_infoSubUsageId m11 : 48|16@1+ (1,0) [0|0] "" Vector__XXX
 SG_ CMPD_infoBootCrc m20 : 32|32@1+ (1,0) [0|0] "" Vector__XXX
 SG_ CMPD_infoHardwareId m10 : 32|16@1+ (1,0) [0|0] "" Vector__XXX
 SG_ CMPD_infoUsageId m11 : 32|16@1+ (1,0) [0|0] "" Vector__XXX
 SG_ CMPD_infoAppCrc m13 : 39|32@0+ (1,0) [0|0] "" Vector__XXX
 SG_ CMPD_infoAssemblyId m11 : 24|8@1+ (1,0) [0|0] "" Vector__XXX
 SG_ CMPD_infoBuildConfigId m10 : 16|16@1+ (1,0) [0|0] "" Vector__XXX
 SG_ CMPD_infoPcbaId m11 : 16|8@1+ (1,0) [0|0] "" Vector__XXX
 SG_ CMPD_infoBootUdsProtoVersion m20 : 8|8@1+ (1,0) [0|0] "" Vector__XXX
 SG_ CMPD_infoBuildType m10 : 8|8@1+ (1,0) [0|0] "" Vector__XXX
 SG_ CMPD_infoPlatformType m13 : 8|8@1+ (1,0) [0|0] "" Vector__XXX
 SG_ CMPD_infoIndex M : 0|8@1+ (1,0) [0|0] "" Vector__XXX

BO_ 871 DI_alertMatrix1: 8 Vector__XXX
 SG_ DI_a064_pmsrmUnitMiaWithHvDown : 63|1@1+ (1,0) [0|0] "" Vector__XXX
 SG_ DI_a063_systemGracefulPowerOff : 62|1@1+ (1,0) [0|0] "" Vector__XXX
 SG_ DI_a062_systemLimpMode : 61|1@1+ (1,0) [0|0] "" Vector__XXX
 SG_ DI_a061_canHardwareBusE : 60|1@1+ (1,0) [0|0] "" Vector__XXX
 SG_ DI_a060_canOverrunBusE : 59|1@1+ (1,0) [0|0] "" Vector__XXX
 SG_ DI_a059_canDataBusE : 58|1@1+ (1,0) [0|0] "" Vector__XXX
 SG_ DI_a058_canHardwareBusD : 57|1@1+ (1,0) [0|0] "" Vector__XXX
 SG_ DI_a057_canOverrunBusD : 56|1@1+ (1,0) [0|0] "" Vector__XXX
 SG_ DI_a056_canDataBusD : 55|1@1+ (1,0) [0|0] "" Vector__XXX
 SG_ DI_a055_canHardwareBusC : 54|1@1+ (1,0) [0|0] "" Vector__XXX
 SG_ DI_a054_canOverrunBusC : 53|1@1+ (1,0) [0|0] "" Vector__XXX
 SG_ DI_a053_canDataBusC : 52|1@1+ (1,0) [0|0] "" Vector__XXX
 SG_ DI_a052_dirMIA : 51|1@1+ (1,0) [0|0] "" Vector__XXX
 SG_ DI_a051_batteryOvercurrent : 50|1@1+ (1,0) [0|0] "" Vector__XXX
 SG_ DI_a048_ecuLogAvailable : 47|1@1+ (1,0) [0|0] "" Vector__XXX
 SG_ DI_a043_pmrMIA : 42|1@1+ (1,0) [0|0] "" Vector__XXX
 SG_ DI_a042_pmfMIA : 41|1@1+ (1,0) [0|0] "" Vector__XXX
 SG_ DI_a041_driverBrakeApplyStuck : 40|1@1+ (1,0) [0|0] "" Vector__XXX
 SG_ DI_a040_difMIA : 39|1@1+ (1,0) [0|0] "" Vector__XXX
 SG_ DI_a036_sysStandbyUnitLimitedWait : 35|1@1+ (1,0) [0|0] "" Vector__XXX
 SG_ DI_a031_closureAccelerationLimit : 30|1@1+ (1,0) [0|0] "" Vector__XXX
 SG_ DI_a027_steeringAngleOffsetService : 26|1@1+ (1,0) [0|0] "" Vector__XXX
 SG_ DI_a026_parkPressedWithHighAPedal : 25|1@1+ (1,0) [0|0] "" Vector__XXX
 SG_ DI_a025_regenBackfillUnavailable : 24|1@1+ (1,0) [0|0] "" Vector__XXX
 SG_ DI_a024_holdNForNeutral : 23|1@1+ (1,0) [0|0] "" Vector__XXX
 SG_ DI_a023_carNotParked : 22|1@1+ (1,0) [0|0] "" Vector__XXX
 SG_ DI_a022_hw5vSupplyUV : 21|1@1+ (1,0) [0|0] "" Vector__XXX
 SG_ DI_a021_packOvervoltage : 20|1@1+ (1,0) [0|0] "" Vector__XXX
 SG_ DI_a019_hwAccelPedalPower : 18|1@1+ (1,0) [0|0] "" Vector__XXX
 SG_ DI_a018_hwLVSupplyUV : 17|1@1+ (1,0) [0|0] "" Vector__XXX
 SG_ DI_a017_hwPedalMonitor : 16|1@1+ (1,0) [0|0] "" Vector__XXX
 SG_ DI_a016_parkRequestByPM : 15|1@1+ (1,0) [0|0] "" Vector__XXX
 SG_ DI_a015_immobilizer : 14|1@1+ (1,0) [0|0] "" Vector__XXX
 SG_ DI_a013_eccError : 12|1@1+ (1,0) [0|0] "" Vector__XXX
 SG_ DI_a012_accel5VSupply : 11|1@1+ (1,0) [0|0] "" Vector__XXX
 SG_ DI_a010_unintendedReset : 9|1@1+ (1,0) [0|0] "" Vector__XXX
 SG_ DI_a005_stalkPanicked : 4|1@1+ (1,0) [0|0] "" Vector__XXX
 SG_ DI_a002_parkButtonDuringStalkReq : 1|1@1+ (1,0) [0|0] "" Vector__XXX
 SG_ DI_a001_frunkSpeedLimitActive : 0|1@1+ (1,0) [0|0] "" Vector__XXX

BO_ 875 DI_alertMatrix3_36B: 8 Vector__XXX
 SG_ DI_a192_invalidOdometer : 63|1@1+ (1,0) [0|0] "" Vector__XXX
 SG_ DI_a191_brakeShiftReq : 62|1@1+ (1,0) [0|0] "" Vector__XXX
 SG_ DI_a190_tireRotationRecommended : 61|1@1+ (1,0) [0|0] "" Vector__XXX
 SG_ DI_a189_garageShiftWithPedal : 60|1@1+ (1,0) [0|0] "" Vector__XXX
 SG_ DI_a188_tireRotationRecommendedG : 59|1@1+ (1,0) [0|0] "" Vector__XXX
 SG_ DI_a187_pedalMisapplication : 58|1@1+ (1,0) [0|0] "" Vector__XXX
 SG_ DI_a186_brakeStand : 57|1@1+ (1,0) [0|0] "" Vector__XXX
 SG_ DI_a185_autoparkAborted : 56|1@1+ (1,0) [0|0] "" Vector__XXX
 SG_ DI_a184_autoparkCanceled : 55|1@1+ (1,0) [0|0] "" Vector__XXX
 SG_ DI_a183_holdReleaseRqrd : 54|1@1+ (1,0) [0|0] "" Vector__XXX
 SG_ DI_a182_frontMotorMode : 53|1@1+ (1,0) [0|0] "" Vector__XXX
 SG_ DI_a181_rearMotorMode : 52|1@1+ (1,0) [0|0] "" Vector__XXX
 SG_ DI_a180_crsSeatbeltUnbuckled : 51|1@1+ (1,0) [0|0] "" Vector__XXX
 SG_ DI_a179_steeringAngleOffsetWarni : 50|1@1+ (1,0) [0|0] "" Vector__XXX
 SG_ DI_a178_steeringAngleOffsetFault : 49|1@1+ (1,0) [0|0] "" Vector__XXX
 SG_ DI_a177_tireFitmentChanged : 48|1@1+ (1,0) [0|0] "" Vector__XXX
 SG_ DI_a176_EBRreleased : 47|1@1+ (1,0) [0|0] "" Vector__XXX
 SG_ DI_a175_crsNotAvailable : 46|1@1+ (1,0) [0|0] "" Vector__XXX
 SG_ DI_a174_notOkToStartDrive : 45|1@1+ (1,0) [0|0] "" Vector__XXX
 SG_ DI_a173_bothPedalsPressed : 44|1@1+ (1,0) [0|0] "" Vector__XXX
 SG_ DI_a172_accelPressedInNP : 43|1@1+ (1,0) [0|0] "" Vector__XXX
 SG_ DI_a171_driveRailNotRequested : 42|1@1+ (1,0) [0|0] "" Vector__XXX
 SG_ DI_a170_tireConfigUpdated : 41|1@1+ (1,0) [0|0] "" Vector__XXX
 SG_ DI_a169_regenOffOverride : 40|1@1+ (1,0) [0|0] "" Vector__XXX
 SG_ DI_a168_proximityDriveDenial : 39|1@1+ (1,0) [0|0] "" Vector__XXX
 SG_ DI_a167_keyNotAuthenticated : 38|1@1+ (1,0) [0|0] "" Vector__XXX
 SG_ DI_a166_driverLeft : 37|1@1+ (1,0) [0|0] "" Vector__XXX
 SG_ DI_a165_cruiseCancelled : 36|1@1+ (1,0) [0|0] "" Vector__XXX
 SG_ DI_a164_brakeOverride : 35|1@1+ (1,0) [0|0] "" Vector__XXX
 SG_ DI_a163_shiftMotorSpeed : 34|1@1+ (1,0) [0|0] "" Vector__XXX
 SG_ DI_a162_shiftDenied : 33|1@1+ (1,0) [0|0] "" Vector__XXX
 SG_ DI_a161_epas3pMIA : 32|1@1+ (1,0) [0|0] "" Vector__XXX
 SG_ DI_a160_fastLearnComplete : 31|1@1+ (1,0) [0|0] "" Vector__XXX
 SG_ DI_a159_cruiseSelfCheck : 30|1@1+ (1,0) [0|0] "" Vector__XXX
 SG_ DI_a158_ibstMIA : 29|1@1+ (1,0) [0|0] "" Vector__XXX
 SG_ DI_a157_rcmMIA : 28|1@1+ (1,0) [0|0] "" Vector__XXX
 SG_ DI_a155_vcfrontMIA : 26|1@1+ (1,0) [0|0] "" Vector__XXX
 SG_ DI_a154_vdcRearSteering : 25|1@1+ (1,0) [0|0] "" Vector__XXX
 SG_ DI_a146_pbrkPanicEpbFault : 17|1@1+ (1,0) [0|0] "" Vector__XXX
 SG_ DI_a144_configMismatch : 15|1@1+ (1,0) [0|0] "" Vector__XXX
 SG_ DI_a143_mcuLimitActive : 14|1@1+ (1,0) [0|0] "" Vector__XXX
 SG_ DI_a142_potholeDetected : 13|1@1+ (1,0) [0|0] "" Vector__XXX
 SG_ DI_a141_dasMIA : 12|1@1+ (1,0) [0|0] "" Vector__XXX
 SG_ DI_a140_ptcMIA : 11|1@1+ (1,0) [0|0] "" Vector__XXX
 SG_ DI_a139_rearUnitDisabled : 10|1@1+ (1,0) [0|0] "" Vector__XXX
 SG_ DI_a138_frontUnitDisabled : 9|1@1+ (1,0) [0|0] "" Vector__XXX
 SG_ DI_a137_noCapableDriveUnits : 8|1@1+ (1,0) [0|0] "" Vector__XXX
 SG_ DI_a135_vehicleHoldFault : 6|1@1+ (1,0) [0|0] "" Vector__XXX
 SG_ DI_a134_wheelSpeedIrrational : 5|1@1+ (1,0) [0|0] "" Vector__XXX
 SG_ DI_a133_vehicleHoldTimedOut : 4|1@1+ (1,0) [0|0] "" Vector__XXX
 SG_ DI_a131_highSpeedWearLimit : 2|1@1+ (1,0) [0|0] "" Vector__XXX
 SG_ DI_a130_aebFault : 1|1@1+ (1,0) [0|0] "" Vector__XXX
 SG_ DI_a129_epbNotApplied : 0|1@1+ (1,0) [0|0] "" Vector__XXX

BO_ 878 DI_alertMatrix4_36E: 8 Vector__XXX
 SG_ DI_a255_manualRecoveryMode : 62|1@1+ (1,0) [0|0] "" Vector__XXX
 SG_ DI_a254_vehicleStuckDetected : 61|1@1+ (1,0) [0|0] "" Vector__XXX
 SG_ DI_a253_accelSynchWarn : 60|1@1+ (1,0) [0|0] "" Vector__XXX
 SG_ DI_a251_diPowerOnStateMismatch : 58|1@1+ (1,0) [0|0] "" Vector__XXX
 SG_ DI_a250_tasSpeedLimitActive : 57|1@1+ (1,0) [0|0] "" Vector__XXX
 SG_ DI_a249_spinDownLearningInProgre : 56|1@1+ (1,0) [0|0] "" Vector__XXX
 SG_ DI_a248_vdcPreControlHighDynamic : 55|1@1+ (1,0) [0|0] "" Vector__XXX
 SG_ DI_a246_opdUnavailable : 53|1@1+ (1,0) [0|0] "" Vector__XXX
 SG_ DI_a245_opdReducedWithoutEbr : 52|1@1+ (1,0) [0|0] "" Vector__XXX
 SG_ DI_a244_vseRLSMassMismatch : 51|1@1+ (1,0) [0|0] "" Vector__XXX
 SG_ DI_a242_vdcTrailerSwayDetected : 49|1@1+ (1,0) [0|0] "" Vector__XXX
 SG_ DI_a241_vdcMotorSpeed_dir : 48|1@1+ (1,0) [0|0] "" Vector__XXX
 SG_ DI_a240_torqueSplitStuck : 47|1@1+ (1,0) [0|0] "" Vector__XXX
 SG_ DI_a239_neutralRequestByPM : 46|1@1+ (1,0) [0|0] "" Vector__XXX
 SG_ DI_a238_secondaryCollisionMitiga : 45|1@1+ (1,0) [0|0] "" Vector__XXX
 SG_ DI_a237_undersideAbuse : 44|1@1+ (1,0) [0|0] "" Vector__XXX
 SG_ DI_a236_tasMIA : 43|1@1+ (1,0) [0|0] "" Vector__XXX
 SG_ DI_a235_trackModeActive : 42|1@1+ (1,0) [0|0] "" Vector__XXX
 SG_ DI_a233_frontWheelImpactDetected : 40|1@1+ (1,0) [0|0] "" Vector__XXX
 SG_ DI_a232_velocityEstimatorDegrade : 39|1@1+ (1,0) [0|0] "" Vector__XXX
 SG_ DI_a231_softSystemLimpMode : 38|1@1+ (1,0) [0|0] "" Vector__XXX
 SG_ DI_a230_cmpMIA : 37|1@1+ (1,0) [0|0] "" Vector__XXX
 SG_ DI_a228_brakeTempEstUnavailable : 35|1@1+ (1,0) [0|0] "" Vector__XXX
 SG_ DI_a227_contactorsNotClosed : 34|1@1+ (1,0) [0|0] "" Vector__XXX
 SG_ DI_a226_sysStartConditionNotMet : 33|1@1+ (1,0) [0|0] "" Vector__XXX
 SG_ DI_a224_brakeOverTemp : 31|1@1+ (1,0) [0|0] "" Vector__XXX
 SG_ DI_a223_tractionControlDisabled : 30|1@1+ (1,0) [0|0] "" Vector__XXX
 SG_ DI_a222_vdcDisabled : 29|1@1+ (1,0) [0|0] "" Vector__XXX
 SG_ DI_a221_vdcUndersteerdMzActive : 28|1@1+ (1,0) [0|0] "" Vector__XXX
 SG_ DI_a220_vdcUndersteerDecelActive : 27|1@1+ (1,0) [0|0] "" Vector__XXX
 SG_ DI_a219_vdcOversteerdMzActive : 26|1@1+ (1,0) [0|0] "" Vector__XXX
 SG_ DI_a218_vdcOSPreControlActive : 25|1@1+ (1,0) [0|0] "" Vector__XXX
 SG_ DI_a217_vdcOutputIrrational : 24|1@1+ (1,0) [0|0] "" Vector__XXX
 SG_ DI_a216_vdcMBPAlmostTripped : 23|1@1+ (1,0) [0|0] "" Vector__XXX
 SG_ DI_a215_vdcWheelSpeedRe : 22|1@1+ (1,0) [0|0] "" Vector__XXX
 SG_ DI_a214_vdcWheelSpeedFr : 21|1@1+ (1,0) [0|0] "" Vector__XXX
 SG_ DI_a213_lowMuProbabilityChange : 20|1@1+ (1,0) [0|0] "" Vector__XXX
 SG_ DI_a212_vdcWheelRotations : 19|1@1+ (1,0) [0|0] "" Vector__XXX
 SG_ DI_a211_vdcMotorSpeed_dif : 18|1@1+ (1,0) [0|0] "" Vector__XXX
 SG_ DI_a210_vdcOtherControllerStates : 17|1@1+ (1,0) [0|0] "" Vector__XXX
 SG_ DI_a208_vdcPowertrainTorque_dir : 15|1@1+ (1,0) [0|0] "" Vector__XXX
 SG_ DI_a207_vdcPowertrainTorque_dif : 14|1@1+ (1,0) [0|0] "" Vector__XXX
 SG_ DI_a206_vdcRcmVertical : 13|1@1+ (1,0) [0|0] "" Vector__XXX
 SG_ DI_a205_vdcRcmLateral : 12|1@1+ (1,0) [0|0] "" Vector__XXX
 SG_ DI_a204_vdcRcmLongitudinal : 11|1@1+ (1,0) [0|0] "" Vector__XXX
 SG_ DI_a203_TCReducedByADD : 10|1@1+ (1,0) [0|0] "" Vector__XXX
 SG_ DI_a202_excessHeatUnavailable : 9|1@1+ (1,0) [0|0] "" Vector__XXX
 SG_ DI_a201_decelTorqueLimited : 8|1@1+ (1,0) [0|0] "" Vector__XXX
 SG_ DI_a200_vdcModelBasedPlausibilit : 7|1@1+ (1,0) [0|0] "" Vector__XXX
 SG_ DI_a199_vdcFaulted : 6|1@1+ (1,0) [0|0] "" Vector__XXX
 SG_ DI_a198_vdcEspMCPressAndSteering : 5|1@1+ (1,0) [0|0] "" Vector__XXX
 SG_ DI_a197_vdcEspWheelSaturations : 4|1@1+ (1,0) [0|0] "" Vector__XXX
 SG_ DI_a196_vdcEspSlipRe : 3|1@1+ (1,0) [0|0] "" Vector__XXX
 SG_ DI_a195_vdcEspSlipFr : 2|1@1+ (1,0) [0|0] "" Vector__XXX
 SG_ DI_a194_vdcBrakeTorqueRe : 1|1@1+ (1,0) [0|0] "" Vector__XXX
 SG_ DI_a193_vdcBrakeTorqueFr : 0|1@1+ (1,0) [0|0] "" Vector__XXX

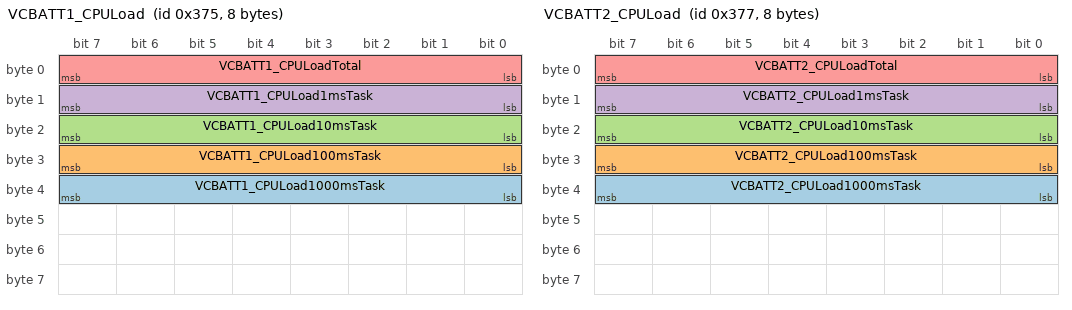
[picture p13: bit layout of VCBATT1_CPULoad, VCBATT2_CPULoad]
BO_ 885 VCBATT1_CPULoad: 8 Vector__XXX
 SG_ VCBATT1_CPULoad1000msTask : 32|8@1+ (1,0) [0|0] "" Vector__XXX
 SG_ VCBATT1_CPULoad100msTask : 24|8@1+ (1,0) [0|0] "" Vector__XXX
 SG_ VCBATT1_CPULoad10msTask : 16|8@1+ (1,0) [0|0] "" Vector__XXX
 SG_ VCBATT1_CPULoad1msTask : 8|8@1+ (1,0) [0|0] "" Vector__XXX
 SG_ VCBATT1_CPULoadTotal : 0|8@1+ (1,0) [0|0] "" Vector__XXX

BO_ 887 VCBATT2_CPULoad: 8 Vector__XXX
 SG_ VCBATT2_CPULoad1000msTask : 32|8@1+ (1,0) [0|0] "" Vector__XXX
 SG_ VCBATT2_CPULoad100msTask : 24|8@1+ (1,0) [0|0] "" Vector__XXX
 SG_ VCBATT2_CPULoad10msTask : 16|8@1+ (1,0) [0|0] "" Vector__XXX
 SG_ VCBATT2_CPULoad1msTask : 8|8@1+ (1,0) [0|0] "" Vector__XXX
 SG_ VCBATT2_CPULoadTotal : 0|8@1+ (1,0) [0|0] "" Vector__XXX

BO_ 889 VCSEC_BLERadioStatus: 8 Vector__XXX
 SG_ VCSEC_BLEGAPAdvertisingC m7 : 58|1@1+ (1,0) [0|0] "" Vector__XXX
 SG_ VCSEC_BLEGAPScanningC m7 : 57|1@1+ (1,0) [0|0] "" Vector__XXX
 SG_ VCSEC_BLEGAPInitiatingConnection m7 : 56|1@1+ (1,0) [0|0] "" Vector__XXX
 SG_ VCSEC_CMPacketMatchL0 m6 : 56|8@1+ (1,0) [0|0] "" Vector__XXX
 SG_ VCSEC_CMPacketMatchRe0 m5 : 56|8@1+ (1,0) [0|0] "" Vector__XXX
 SG_ VCSEC_CMPacketMatchRi0 m4 : 56|8@1+ (1,0) [0|0] "" Vector__XXX
 SG_ VCSEC_queueLengthMaxC m11 : 56|8@1+ (1,0) [0|0] "" Vector__XXX
 SG_ VCSEC_queueLengthMaxL m10 : 56|8@1+ (1,0) [0|0] "" Vector__XXX
 SG_ VCSEC_queueLengthMaxR m8 : 56|8@1+ (1,0) [0|0] "" Vector__XXX
 SG_ VCSEC_queueLengthMaxRe m9 : 56|8@1+ (1,0) [0|0] "" Vector__XXX
 SG_ VCSEC_CMPeripheralMissingMatchL0 m6 : 48|8@1+ (1,0) [0|0] "" Vector__XXX
 SG_ VCSEC_CMPeripheralMissingMatchRe m5 : 48|8@1+ (1,0) [0|0] "" Vector__XXX
 SG_ VCSEC_CMPeripheralMissingMatchRi m4 : 48|8@1+ (1,0) [0|0] "" Vector__XXX
 SG_ VCSEC_queueSizeMaxC m11 : 48|8@1+ (1,0) [0|0] "" Vector__XXX
 SG_ VCSEC_queueSizeMaxL m10 : 48|8@1+ (1,0) [0|0] "" Vector__XXX
 SG_ VCSEC_queueSizeMaxR m8 : 48|8@1+ (1,0) [0|0] "" Vector__XXX
 SG_ VCSEC_queueSizeMaxRe m9 : 48|8@1+ (1,0) [0|0] "" Vector__XXX
 SG_ VCSEC_BLEHeapMaxUsageC m3 : 47|7@1+ (1,0) [0|0] "" Vector__XXX
 SG_ VCSEC_BLEHeapMaxUsageL m2 : 47|7@1+ (1,0) [0|0] "" Vector__XXX
 SG_ VCSEC_BLEHeapMaxUsageRe m1 : 47|7@1+ (1,0) [0|0] "" Vector__XXX
 SG_ VCSEC_BLEHeapMaxUsageRi m0 : 47|7@1+ (1,0) [0|0] "" Vector__XXX
 SG_ VCSEC_BLEAdvPeriodC m7 : 45|11@1+ (1,0) [0|0] "" Vector__XXX
 SG_ VCSEC_connectionMonitorConn_0001 m6 : 45|3@1+ (1,0) [0|0] "" Vector__XXX
 SG_ VCSEC_connectionMonitorConn_0004 m5 : 45|3@1+ (1,0) [0|0] "" Vector__XXX
 SG_ VCSEC_connectionMonitorConn_0007 m4 : 45|3@1+ (1,0) [0|0] "" Vector__XXX
 SG_ VCSEC_BLENonWhitelistedScanEnabl m7 : 44|1@1+ (1,0) [0|0] "" Vector__XXX
 SG_ VCSEC_connectionMonitorConn_0000 m6 : 42|3@1+ (1,0) [0|0] "" Vector__XXX
 SG_ VCSEC_connectionMonitorConn_0003 m5 : 42|3@1+ (1,0) [0|0] "" Vector__XXX
 SG_ VCSEC_connectionMonitorConn_0006 m4 : 42|3@1+ (1,0) [0|0] "" Vector__XXX
 SG_ VCSEC_BLEHeapUsageC m3 : 40|7@1+ (1,0) [0|0] "" Vector__XXX
 SG_ VCSEC_BLEHeapUsageL m2 : 40|7@1+ (1,0) [0|0] "" Vector__XXX
 SG_ VCSEC_BLEHeapUsageRe m1 : 40|7@1+ (1,0) [0|0] "" Vector__XXX
 SG_ VCSEC_BLEHeapUsageRi m0 : 40|7@1+ (1,0) [0|0] "" Vector__XXX
 SG_ VCSEC_BLERSSITrackingPercentC2 m7 : 40|4@1+ (8,0) [0|0] "" Vector__XXX
 SG_ VCSEC_connectionMonitorConnectio m6 : 39|3@1+ (1,0) [0|0] "" Vector__XXX
 SG_ VCSEC_connectionMonitorConn_0002 m5 : 39|3@1+ (1,0) [0|0] "" Vector__XXX
 SG_ VCSEC_connectionMonitorConn_0005 m4 : 39|3@1+ (1,0) [0|0] "" Vector__XXX
 SG_ VCSEC_BLENonWhitelistedScan_0000 m6 : 38|1@1+ (1,0) [0|0] "" Vector__XXX
 SG_ VCSEC_BLENonWhitelistedScan_0001 m5 : 38|1@1+ (1,0) [0|0] "" Vector__XXX
 SG_ VCSEC_BLENonWhitelistedScan_0002 m4 : 38|1@1+ (1,0) [0|0] "" Vector__XXX
 SG_ VCSEC_BLERSSITrackingPercentC1 m7 : 36|4@1+ (8,0) [0|0] "" Vector__XXX
 SG_ VCSEC_BLEWhitelistEntriesL m6 : 34|4@1+ (1,0) [0|0] "" Vector__XXX
 SG_ VCSEC_BLEWhitelistEntriesRe m5 : 34|4@1+ (1,0) [0|0] "" Vector__XXX
 SG_ VCSEC_BLEWhitelistEntriesRi m4 : 34|4@1+ (1,0) [0|0] "" Vector__XXX
 SG_ VCSEC_BLERSSITrackingPercentC0 m7 : 32|4@1+ (8,0) [0|0] "" Vector__XXX
 SG_ VCSEC_BLEScheduleErrorsL m6 : 32|2@1+ (1,0) [0|0] "" Vector__XXX
 SG_ VCSEC_BLEScheduleErrorsRe m5 : 32|2@1+ (1,0) [0|0] "" Vector__XXX
 SG_ VCSEC_BLEScheduleErrorsRi m4 : 32|2@1+ (1,0) [0|0] "" Vector__XXX
 SG_ VCSEC_totalVCSECRetransmitsC m11 : 32|16@1+ (1,0) [0|0] "" Vector__XXX
 SG_ VCSEC_totalVCSECRetransmitsL m10 : 32|16@1+ (1,0) [0|0] "" Vector__XXX
 SG_ VCSEC_totalVCSECRetransmitsR m8 : 32|16@1+ (1,0) [0|0] "" Vector__XXX
 SG_ VCSEC_totalVCSECRetransmitsRe m9 : 32|16@1+ (1,0) [0|0] "" Vector__XXX
 SG_ VCSEC_BLEHeapSizeC m3 : 24|14@1+ (1,0) [0|0] "" Vector__XXX
 SG_ VCSEC_BLEHeapSizeL m2 : 24|14@1+ (1,0) [0|0] "" Vector__XXX
 SG_ VCSEC_BLEHeapSizeRe m1 : 24|14@1+ (1,0) [0|0] "" Vector__XXX
 SG_ VCSEC_BLEHeapSizeRi m0 : 24|14@1+ (1,0) [0|0] "" Vector__XXX
 SG_ VCSEC_BLEPacketsReceivedL m6 : 24|8@1+ (1,0) [0|0] "" Vector__XXX
 SG_ VCSEC_BLEPacketsReceivedRe m5 : 24|8@1+ (1,0) [0|0] "" Vector__XXX
 SG_ VCSEC_BLEPacketsReceivedRi m4 : 24|8@1+ (1,0) [0|0] "" Vector__XXX
 SG_ VCSEC_BLECPULoadC m3 : 16|7@1+ (1,0) [0|0] "" Vector__XXX
 SG_ VCSEC_BLECPULoadL m2 : 16|7@1+ (1,0) [0|0] "" Vector__XXX
 SG_ VCSEC_BLECPULoadRe m1 : 16|7@1+ (1,0) [0|0] "" Vector__XXX
 SG_ VCSEC_BLECPULoadRi m0 : 16|7@1+ (1,0) [0|0] "" Vector__XXX
 SG_ VCSEC_BLETimesScheduledL m6 : 16|8@1+ (1,0) [0|0] "" Vector__XXX
 SG_ VCSEC_BLETimesScheduledRe m5 : 16|8@1+ (1,0) [0|0] "" Vector__XXX
 SG_ VCSEC_BLETimesScheduledRi m4 : 16|8@1+ (1,0) [0|0] "" Vector__XXX
 SG_ VCSEC_totalEndpointNacksC m11 : 16|16@1+ (1,0) [0|0] "" Vector__XXX
 SG_ VCSEC_totalEndpointNacksL m10 : 16|16@1+ (1,0) [0|0] "" Vector__XXX
 SG_ VCSEC_totalEndpointNacksR m8 : 16|16@1+ (1,0) [0|0] "" Vector__XXX
 SG_ VCSEC_totalEndpointNacksRe m9 : 16|16@1+ (1,0) [0|0] "" Vector__XXX
 SG_ VCSEC_BLEAdvCounterC m7 : 13|16@1+ (1,0) [0|0] "" Vector__XXX
 SG_ VCSEC_BLEAdvStatusC m3 : 13|3@1+ (1,0) [0|0] "" Vector__XXX
 SG_ VCSEC_BLEDevicePacketCounter : 6|7@1+ (1,0) [0|0] "" Vector__XXX
 SG_ VCSEC_BLERadioStatusIndex M : 0|4@1+ (1,0) [0|0] "" Vector__XXX

BO_ 893 CP_thermalStatus: 8 Vector__XXX
 SG_ CP_pinTemp3Velocity m0 : 53|10@1- (0.15748,0) [0|0] "" Vector__XXX
 SG_ CP_pinTemp2Velocity m0 : 43|10@1- (0.15748,0) [0|0] "" Vector__XXX
 SG_ CP_pinTemp4Velocity m1 : 40|10@1- (0.15748,0) [0|0] "" Vector__XXX
 SG_ CP_pinTemp1Velocity m0 : 33|10@1- (0.15748,0) [0|0] "" Vector__XXX
 SG_ CP_pinTemperature4 m1 : 32|8@1+ (0.8039215686,-55) [0|0] "" Vector__XXX
 SG_ CP_acPinTemperature2 m0 : 25|8@1+ (0.8039215686,-55) [0|0] "" Vector__XXX
 SG_ CP_pinTemperature3 m1 : 24|8@1+ (0.8039215686,-55) [0|0] "" Vector__XXX
 SG_ CP_acPinTemperature m0 : 17|8@1+ (0.8039215686,-55) [0|0] "" Vector__XXX
 SG_ CP_pinTemperature2 m1 : 16|8@1+ (0.8039215686,-55) [0|0] "" Vector__XXX
 SG_ CP_dcPinTemperature2 m0 : 9|8@1+ (0.8039215686,-55) [0|0] "" Vector__XXX
 SG_ CP_pinTemperature1 m1 : 8|8@1+ (0.8039215686,-55) [0|0] "" Vector__XXX
 SG_ CP_dcPinTemperature m0 : 1|8@1+ (0.8039215686,-55) [0|0] "" Vector__XXX
 SG_ CP_thermalStatusSelect M : 0|1@1+ (1,0) [0|0] "" Vector__XXX

BO_ 896 PM_alertMatrix2: 8 Vector__XXX
 SG_ PM_a125_btcOutputIrrational : 60|1@1+ (1,0) [0|0] "" Vector__XXX
 SG_ PM_a121_unintendedReset2 : 56|1@1+ (1,0) [0|0] "" Vector__XXX
 SG_ PM_a120_indirectTPMSFaulted : 55|1@1+ (1,0) [0|0] "" Vector__XXX
 SG_ PM_a117_ITPMSPermeabilityCalibra : 52|1@1+ (1,0) [0|0] "" Vector__XXX
 SG_ PM_a116_ITPMSBlowoutDetected : 51|1@1+ (1,0) [0|0] "" Vector__XXX
 SG_ PM_a115_indirectTPMSFaultedGhost : 50|1@1+ (1,0) [0|0] "" Vector__XXX
 SG_ PM_a113_btcMonitor : 48|1@1+ (1,0) [0|0] "" Vector__XXX
 SG_ PM_a112_indirectTPMSPressureLoss : 47|1@1+ (1,0) [0|0] "" Vector__XXX
 SG_ PM_a111_unintendedResetCausedNeu : 46|1@1+ (1,0) [0|0] "" Vector__XXX
 SG_ PM_a110_indirectTPMSPressureLoss : 45|1@1+ (1,0) [0|0] "" Vector__XXX
 SG_ PM_a100_diTraceInfo1 : 35|1@1+ (1,0) [0|0] "" Vector__XXX
 SG_ PM_a099_ITPMSCalibrated : 34|1@1+ (1,0) [0|0] "" Vector__XXX
 SG_ PM_a098_ITPMSTriggerDebug : 33|1@1+ (1,0) [0|0] "" Vector__XXX
 SG_ PM_a097_ITPMSRelativeCalibratedF : 32|1@1+ (1,0) [0|0] "" Vector__XXX
 SG_ PM_a096_ITPMSConvergedGNSSAbsRad : 31|1@1+ (1,0) [0|0] "" Vector__XXX
 SG_ PM_a095_ITPMSTimeoutGNSSConverge : 30|1@1+ (1,0) [0|0] "" Vector__XXX
 SG_ PM_a093_accelPedalSupply : 28|1@1+ (1,0) [0|0] "" Vector__XXX
 SG_ PM_a092_xtalOscillator : 27|1@1+ (1,0) [0|0] "" Vector__XXX
 SG_ PM_a086_exceptionUndefinedInstru : 21|1@1+ (1,0) [0|0] "" Vector__XXX
 SG_ PM_a084_exceptionMpuFirewall : 19|1@1+ (1,0) [0|0] "" Vector__XXX
 SG_ PM_a083_ahbWriteError : 18|1@1+ (1,0) [0|0] "" Vector__XXX
 SG_ PM_a082_exceptionDataAbort2 : 17|1@1+ (1,0) [0|0] "" Vector__XXX
 SG_ PM_a081_exceptionDataAbort : 16|1@1+ (1,0) [0|0] "" Vector__XXX
 SG_ PM_a080_exceptionPrefetchAbort : 15|1@1+ (1,0) [0|0] "" Vector__XXX
 SG_ PM_a067_pmrMIA : 2|1@1+ (1,0) [0|0] "" Vector__XXX
 SG_ PM_a066_pmfMIA : 1|1@1+ (1,0) [0|0] "" Vector__XXX

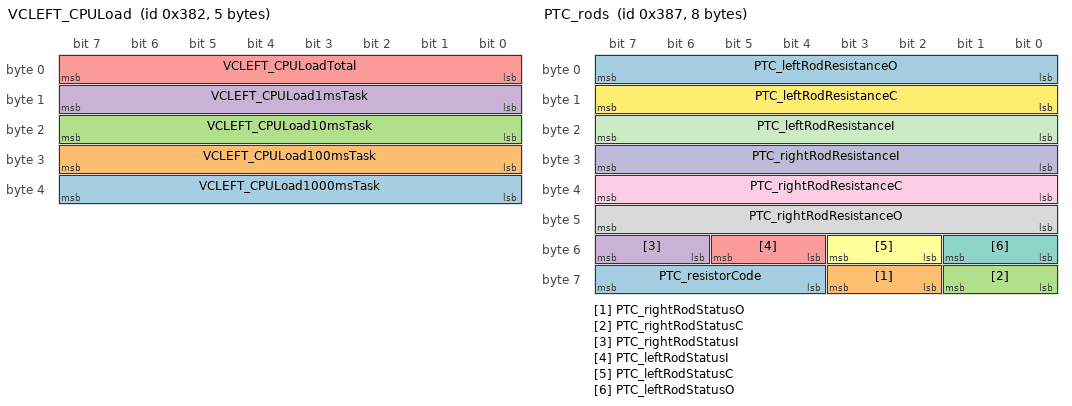
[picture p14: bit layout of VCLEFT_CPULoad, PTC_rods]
BO_ 898 VCLEFT_CPULoad: 5 Vector__XXX
 SG_ VCLEFT_CPULoad1000msTask : 32|8@1+ (1,0) [0|0] "" Vector__XXX
 SG_ VCLEFT_CPULoad100msTask : 24|8@1+ (1,0) [0|0] "" Vector__XXX
 SG_ VCLEFT_CPULoad10msTask : 16|8@1+ (1,0) [0|0] "" Vector__XXX
 SG_ VCLEFT_CPULoad1msTask : 8|8@1+ (1,0) [0|0] "" Vector__XXX
 SG_ VCLEFT_CPULoadTotal : 0|8@1+ (1,0) [0|0] "" Vector__XXX

BO_ 902 PMR_alertMatrix1: 8 Vector__XXX
 SG_ PMR_a064_torqueIntervention : 63|1@1+ (1,0) [0|0] "" Vector__XXX
 SG_ PMR_a062_eccError : 61|1@1+ (1,0) [0|0] "" Vector__XXX
 SG_ PMR_a061_DIPMVersionMismatch : 60|1@1+ (1,0) [0|0] "" Vector__XXX
 SG_ PMR_a057_canDataBusB : 56|1@1+ (1,0) [0|0] "" Vector__XXX
 SG_ PMR_a056_canHardwareBusB : 55|1@1+ (1,0) [0|0] "" Vector__XXX
 SG_ PMR_a055_resolver : 54|1@1+ (1,0) [0|0] "" Vector__XXX
 SG_ PMR_a054_uiMIA : 53|1@1+ (1,0) [0|0] "" Vector__XXX
 SG_ PMR_a053_vcfrontMIA : 52|1@1+ (1,0) [0|0] "" Vector__XXX
 SG_ PMR_a045_motorMovementDetected : 44|1@1+ (1,0) [0|0] "" Vector__XXX
 SG_ PMR_a042_gtwMIA : 41|1@1+ (1,0) [0|0] "" Vector__XXX
 SG_ PMR_a040_pmMIA : 39|1@1+ (1,0) [0|0] "" Vector__XXX
 SG_ PMR_a039_disMIA : 38|1@1+ (1,0) [0|0] "" Vector__XXX
 SG_ PMR_a037_hvpMIA : 36|1@1+ (1,0) [0|0] "" Vector__XXX
 SG_ PMR_a036_preWatchdog : 35|1@1+ (1,0) [0|0] "" Vector__XXX
 SG_ PMR_a035_udsTransactionInitiated : 34|1@1+ (1,0) [0|0] "" Vector__XXX
 SG_ PMR_a034_trqCrossCheck : 33|1@1+ (1,0) [0|0] "" Vector__XXX
 SG_ PMR_a033_selfTest : 32|1@1+ (1,0) [0|0] "" Vector__XXX
 SG_ PMR_a032_registerConfigError : 31|1@1+ (1,0) [0|0] "" Vector__XXX
 SG_ PMR_a031_highStackUsage : 30|1@1+ (1,0) [0|0] "" Vector__XXX
 SG_ PMR_a028_torqueCmdError : 27|1@1+ (1,0) [0|0] "" Vector__XXX
 SG_ PMR_a027_torqueEstimationOutOfBounds : 26|1@1+ (1,0) [0|0] "" Vector__XXX
 SG_ PMR_a026_diHeartBeatMIA : 25|1@1+ (1,0) [0|0] "" Vector__XXX
 SG_ PMR_a025_unintendedReset : 24|1@1+ (1,0) [0|0] "" Vector__XXX
 SG_ PMR_a019_statorTempIrrational : 18|1@1+ (1,0) [0|0] "" Vector__XXX
 SG_ PMR_a018_encoderIrrational : 17|1@1+ (1,0) [0|0] "" Vector__XXX
 SG_ PMR_a017_brakeMIA : 16|1@1+ (1,0) [0|0] "" Vector__XXX
 SG_ PMR_a013_canHardwareBusA : 12|1@1+ (1,0) [0|0] "" Vector__XXX
 SG_ PMR_a012_canDataBusA : 11|1@1+ (1,0) [0|0] "" Vector__XXX
 SG_ PMR_a011_phaseCurrentIrrational : 10|1@1+ (1,0) [0|0] "" Vector__XXX
 SG_ PMR_a010_diMIA : 9|1@1+ (1,0) [0|0] "" Vector__XXX
 SG_ PMR_a008_memoryError : 7|1@1+ (1,0) [0|0] "" Vector__XXX
 SG_ PMR_a005_torqueInNeutralOrPark : 4|1@1+ (1,0) [0|0] "" Vector__XXX
 SG_ PMR_a004_excessiveDecelTorque : 3|1@1+ (1,0) [0|0] "" Vector__XXX
 SG_ PMR_a003_excessiveReversalTorque : 2|1@1+ (1,0) [0|0] "" Vector__XXX
 SG_ PMR_a002_excessiveAccelTorque : 1|1@1+ (1,0) [0|0] "" Vector__XXX
 SG_ PMR_a001_absoluteTorque : 0|1@1+ (1,0) [0|0] "" Vector__XXX

BO_ 903 PTC_rods: 8 Vector__XXX
 SG_ PTC_resistorCode : 60|4@1+ (1,0) [0|0] "" Vector__XXX
 SG_ PTC_rightRodStatusO : 58|2@1+ (1,0) [0|0] "" Vector__XXX
 SG_ PTC_rightRodStatusC : 56|2@1+ (1,0) [0|0] "" Vector__XXX
 SG_ PTC_rightRodStatusI : 54|2@1+ (1,0) [0|0] "" Vector__XXX
 SG_ PTC_leftRodStatusI : 52|2@1+ (1,0) [0|0] "" Vector__XXX
 SG_ PTC_leftRodStatusC : 50|2@1+ (1,0) [0|0] "" Vector__XXX
 SG_ PTC_leftRodStatusO : 48|2@1+ (1,0) [0|0] "" Vector__XXX
 SG_ PTC_rightRodResistanceO : 40|8@1+ (2,0) [0|0] "" Vector__XXX
 SG_ PTC_rightRodResistanceC : 32|8@1+ (2,0) [0|0] "" Vector__XXX
 SG_ PTC_rightRodResistanceI : 24|8@1+ (2,0) [0|0] "" Vector__XXX
 SG_ PTC_leftRodResistanceI : 16|8@1+ (2,0) [0|0] "" Vector__XXX
 SG_ PTC_leftRodResistanceC : 8|8@1+ (2,0) [0|0] "" Vector__XXX
 SG_ PTC_leftRodResistanceO : 0|8@1+ (2,0) [0|0] "" Vector__XXX

BO_ 906 VCSEC_NFCCurrentCardUID: 8 Vector__XXX
 SG_ VCSEC_BPillarNFCCardUIDL m0 : 8|56@1+ (1,0) [0|0] "" Vector__XXX
 SG_ VCSEC_BPillarNFCCardUIDR m1 : 8|56@1+ (1,0) [0|0] "" Vector__XXX
 SG_ VCSEC_CenterNFCCardUID m3 : 8|56@1+ (1,0) [0|0] "" Vector__XXX
 SG_ VCSEC_NFCReaderIndexUID M : 0|2@1+ (1,0) [0|0] "" Vector__XXX

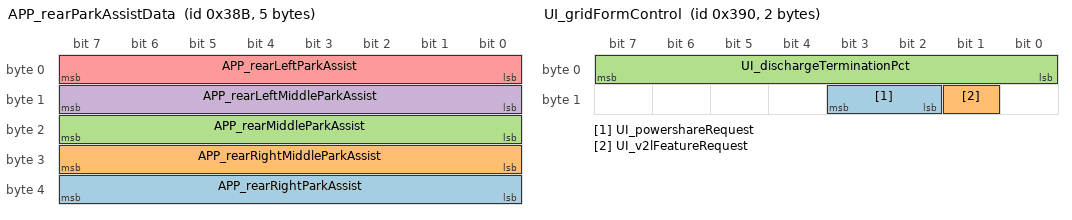
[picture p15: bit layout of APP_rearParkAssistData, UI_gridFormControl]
BO_ 907 APP_rearParkAssistData: 5 Vector__XXX
 SG_ APP_rearRightParkAssist : 32|8@1+ (1,0) [0|0] "" Vector__XXX
 SG_ APP_rearRightMiddleParkAssist : 24|8@1+ (1,0) [0|0] "" Vector__XXX
 SG_ APP_rearMiddleParkAssist : 16|8@1+ (1,0) [0|0] "" Vector__XXX
 SG_ APP_rearLeftMiddleParkAssist : 8|8@1+ (1,0) [0|0] "" Vector__XXX
 SG_ APP_rearLeftParkAssist : 0|8@1+ (1,0) [0|0] "" Vector__XXX

BO_ 912 UI_gridFormControl: 2 Vector__XXX
 SG_ UI_powershareRequest : 10|2@1+ (1,0) [0|0] "" Vector__XXX
 SG_ UI_v2lFeatureRequest : 9|1@1+ (1,0) [0|0] "" Vector__XXX
 SG_ UI_dischargeTerminationPct : 0|8@1+ (1,0) [0|0] "" Vector__XXX

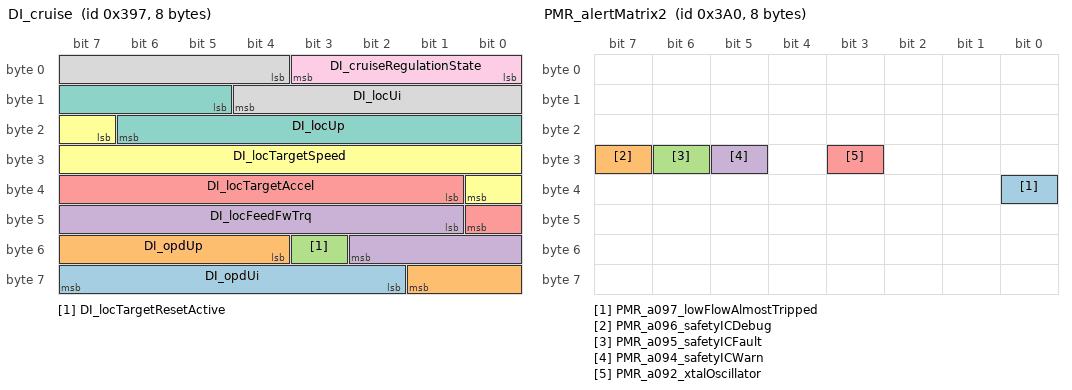
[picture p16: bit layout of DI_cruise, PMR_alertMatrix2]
BO_ 919 DI_cruise: 8 Vector__XXX
 SG_ DI_opdUi : 58|6@1- (40,0) [0|0] "" Vector__XXX
 SG_ DI_opdUp : 52|6@1- (40,0) [0|0] "" Vector__XXX
 SG_ DI_locTargetResetActive : 51|1@1+ (1,0) [0|0] "" Vector__XXX
 SG_ DI_locFeedFwTrq : 41|10@1- (19.569471624266146,0) [0|0] "" Vector__XXX
 SG_ DI_locTargetAccel : 33|8@1- (0.1094488188976378,-1.5322834645669292) [0|0] "" Vector__XXX
 SG_ DI_locTargetSpeed : 23|10@1- (0.25,20) [0|0] "" Vector__XXX
 SG_ DI_locUp : 13|10@1- (19.569471624266146,0) [0|0] "" Vector__XXX
 SG_ DI_locUi : 4|9@1- (19.607843137254903,0) [0|0] "" Vector__XXX
 SG_ DI_cruiseRegulationState : 0|4@1+ (1,0) [0|0] "" Vector__XXX

BO_ 922 VCSEC_RSSI: 8 Vector__XXX
 SG_ VCSEC_RSSI2ConnectionType m1 : 61|2@1+ (1,0) [0|0] "" Vector__XXX
 SG_ VCSEC_BLEDevicePresence0 m0 : 59|5@1+ (1,0) [0|0] "" Vector__XXX
 SG_ VCSEC_RSSI1ConnectionType m1 : 59|2@1+ (1,0) [0|0] "" Vector__XXX
 SG_ VCSEC_UnknownBLEDevicePresent m0 : 58|1@1+ (1,0) [0|0] "" Vector__XXX
 SG_ VCSEC_RSSI0ConnectionType m1 : 57|2@1+ (1,0) [0|0] "" Vector__XXX
 SG_ VCSEC_BLEDevicePresence3 m1 : 52|5@1+ (1,0) [0|0] "" Vector__XXX
 SG_ VCSEC_rearBLEAntennaRSSI1 m0 : 50|8@1- (1,0) [0|0] "" Vector__XXX
 SG_ VCSEC_BLEDevicePresence2 m1 : 47|5@1+ (1,0) [0|0] "" Vector__XXX
 SG_ VCSEC_BLEDevicePresence1 m1 : 42|5@1+ (1,0) [0|0] "" Vector__XXX
 SG_ VCSEC_rightBLEAntennaRSSI1 m0 : 42|8@1- (1,0) [0|0] "" Vector__XXX
 SG_ VCSEC_centerBLEAntennaRSSI2 m1 : 34|8@1- (1,0) [0|0] "" Vector__XXX
 SG_ VCSEC_leftBLEAntennaRSSI1 m0 : 34|8@1- (1,0) [0|0] "" Vector__XXX
 SG_ VCSEC_centerBLEAntennaRSSI0 m0 : 26|8@1- (1,0) [0|0] "" Vector__XXX
 SG_ VCSEC_rearBLEAntennaRSSI2 m1 : 26|8@1- (1,0) [0|0] "" Vector__XXX
 SG_ VCSEC_rearBLEAntennaRSSI0 m0 : 18|8@1- (1,0) [0|0] "" Vector__XXX
 SG_ VCSEC_rightBLEAntennaRSSI2 m1 : 18|8@1- (1,0) [0|0] "" Vector__XXX
 SG_ VCSEC_leftBLEAntennaRSSI2 m1 : 10|8@1- (1,0) [0|0] "" Vector__XXX
 SG_ VCSEC_rightBLEAntennaRSSI0 m0 : 10|8@1- (1,0) [0|0] "" Vector__XXX
 SG_ VCSEC_centerBLEAntennaRSSI1 m1 : 2|8@1- (1,0) [0|0] "" Vector__XXX
 SG_ VCSEC_leftBLEAntennaRSSI0 m0 : 2|8@1- (1,0) [0|0] "" Vector__XXX
 SG_ VCSEC_RSSIIndex M : 0|2@1+ (1,0) [0|0] "" Vector__XXX

BO_ 923 DAS_status_39B: 8 Vector__XXX
 SG_ DAS_statusChecksum : 56|8@1+ (1,0) [0|0] "" Vector__XXX
 SG_ DAS_statusCounter : 52|4@1+ (1,0) [0|0] "" Vector__XXX
 SG_ DAS_summonAvailable : 51|1@1+ (1,0) [0|0] "" Vector__XXX
 SG_ DAS_autoLaneChangeState : 46|5@1+ (1,0) [0|0] "" Vector__XXX
 SG_ DAS_autopilotHandsOnState : 42|4@1+ (1,0) [0|0] "" Vector__XXX
 SG_ DAS_fleetSpeedState : 40|2@1+ (1,0) [0|0] "" Vector__XXX
 SG_ DAS_laneDepartureWarning : 37|3@1+ (1,0) [0|0] "" Vector__XXX
 SG_ DAS_sideCollisionInhibit : 36|1@1+ (1,0) [0|0] "" Vector__XXX
 SG_ DAS_sideCollisionWarning : 34|2@1+ (1,0) [0|0] "" Vector__XXX
 SG_ DAS_sideCollisionAvoid : 32|2@1+ (1,0) [0|0] "" Vector__XXX
 SG_ DAS_lssState : 29|3@1+ (1,0) [0|0] "" Vector__XXX
 SG_ DAS_summonRvsLeashReached : 28|1@1+ (1,0) [0|0] "" Vector__XXX
 SG_ DAS_summonFwdLeashReached : 27|1@1+ (1,0) [0|0] "" Vector__XXX
 SG_ DAS_autoparkActive : 26|1@1+ (1,0) [0|0] "" Vector__XXX
 SG_ DAS_autoParked : 25|1@1+ (1,0) [0|0] "" Vector__XXX
 SG_ DAS_autoparkReady : 24|1@1+ (1,0) [0|0] "" Vector__XXX
 SG_ DAS_forwardCollisionWarning : 22|2@1+ (1,0) [0|0] "" Vector__XXX
 SG_ DAS_heaterState : 21|1@1+ (1,0) [0|0] "" Vector__XXX
 SG_ DAS_visionOnlySpeedLimit : 16|5@1+ (5,0) [0|0] "" Vector__XXX
 SG_ DAS_summonClearedGate : 15|1@1+ (1,0) [0|0] "" Vector__XXX
 SG_ DAS_summonObstacle : 14|1@1+ (1,0) [0|0] "" Vector__XXX
 SG_ DAS_suppressSpeedWarning : 13|1@1+ (1,0) [0|0] "" Vector__XXX
 SG_ DAS_fusedSpeedLimit : 8|5@1+ (5,0) [0|0] "" Vector__XXX
 SG_ DAS_blindSpotRearRight : 6|2@1+ (1,0) [0|0] "" Vector__XXX
 SG_ DAS_blindSpotRearLeft : 4|2@1+ (1,0) [0|0] "" Vector__XXX
 SG_ DAS_autopilotState : 0|4@1+ (1,0) [0|0] "" Vector__XXX

BO_ 928 PMR_alertMatrix2: 8 Vector__XXX
 SG_ PMR_a097_lowFlowAlmostTripped : 32|1@1+ (1,0) [0|0] "" Vector__XXX
 SG_ PMR_a096_safetyICDebug : 31|1@1+ (1,0) [0|0] "" Vector__XXX
 SG_ PMR_a095_safetyICFault : 30|1@1+ (1,0) [0|0] "" Vector__XXX
 SG_ PMR_a094_safetyICWarn : 29|1@1+ (1,0) [0|0] "" Vector__XXX
 SG_ PMR_a092_xtalOscillator : 27|1@1+ (1,0) [0|0] "" Vector__XXX

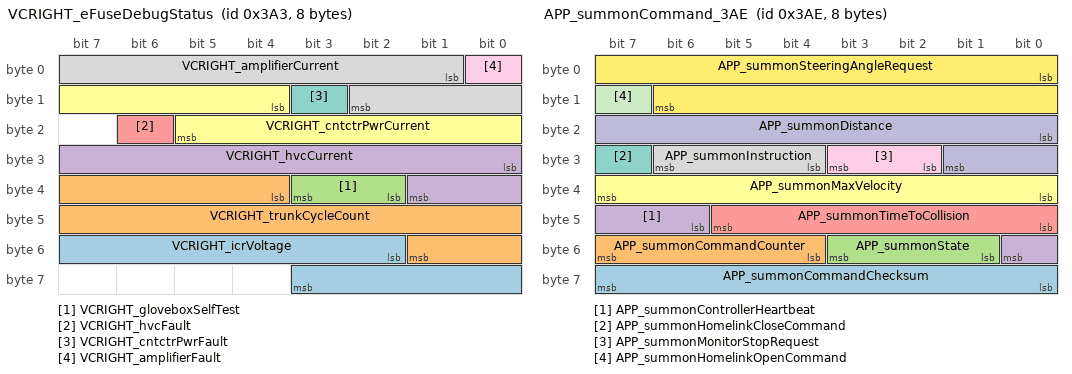
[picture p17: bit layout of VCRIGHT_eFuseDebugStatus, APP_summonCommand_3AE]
BO_ 931 VCRIGHT_eFuseDebugStatus: 8 Vector__XXX
 SG_ VCRIGHT_icrVoltage : 50|10@1+ (0.02,0) [0|0] "" Vector__XXX
 SG_ VCRIGHT_trunkCycleCount : 36|14@1+ (10,0) [0|0] "" Vector__XXX
 SG_ VCRIGHT_gloveboxSelfTest : 34|2@1+ (1,0) [0|0] "" Vector__XXX
 SG_ VCRIGHT_hvcCurrent : 24|10@1+ (0.1,0) [0|0] "" Vector__XXX
 SG_ VCRIGHT_hvcFault : 22|1@1+ (1,0) [0|0] "" Vector__XXX
 SG_ VCRIGHT_cntctrPwrCurrent : 12|10@1+ (0.1,0) [0|0] "" Vector__XXX
 SG_ VCRIGHT_cntctrPwrFault : 11|1@1+ (1,0) [0|0] "" Vector__XXX
 SG_ VCRIGHT_amplifierCurrent : 1|10@1+ (0.1,0) [0|0] "" Vector__XXX
 SG_ VCRIGHT_amplifierFault : 0|1@1+ (1,0) [0|0] "" Vector__XXX

BO_ 935 DIR_alertMatrix1: 8 Vector__XXX
 SG_ DIR_a064_torqueIntervention : 63|1@1+ (1,0) [0|0] "" Vector__XXX
 SG_ DIR_a062_systemLimpMode : 61|1@1+ (1,0) [0|0] "" Vector__XXX
 SG_ DIR_a061_heatsinkSensor : 60|1@1+ (1,0) [0|0] "" Vector__XXX
 SG_ DIR_a060_heatsinkUT : 59|1@1+ (1,0) [0|0] "" Vector__XXX
 SG_ DIR_a059_heatsinkOT : 58|1@1+ (1,0) [0|0] "" Vector__XXX
 SG_ DIR_a058_ambientSensor : 57|1@1+ (1,0) [0|0] "" Vector__XXX
 SG_ DIR_a057_ambientUT : 56|1@1+ (1,0) [0|0] "" Vector__XXX
 SG_ DIR_a056_ambientOT : 55|1@1+ (1,0) [0|0] "" Vector__XXX
 SG_ DIR_a055_trqCrossCheck : 54|1@1+ (1,0) [0|0] "" Vector__XXX
 SG_ DIR_a054_driveInverterOT : 53|1@1+ (1,0) [0|0] "" Vector__XXX
 SG_ DIR_a053_unexpectedLatchState : 52|1@1+ (1,0) [0|0] "" Vector__XXX
 SG_ DIR_a052_dirMIA : 51|1@1+ (1,0) [0|0] "" Vector__XXX
 SG_ DIR_a050_noStatorSensor : 49|1@1+ (1,0) [0|0] "" Vector__XXX
 SG_ DIR_a049_statorSensorDiff : 48|1@1+ (1,0) [0|0] "" Vector__XXX
 SG_ DIR_a048_statorSensor2 : 47|1@1+ (1,0) [0|0] "" Vector__XXX
 SG_ DIR_a047_statorSensor1 : 46|1@1+ (1,0) [0|0] "" Vector__XXX
 SG_ DIR_a046_statorOT : 45|1@1+ (1,0) [0|0] "" Vector__XXX
 SG_ DIR_a045_outletSensor : 44|1@1+ (1,0) [0|0] "" Vector__XXX
 SG_ DIR_a044_outletUT : 43|1@1+ (1,0) [0|0] "" Vector__XXX
 SG_ DIR_a043_outletOT : 42|1@1+ (1,0) [0|0] "" Vector__XXX
 SG_ DIR_a042_inletSensor : 41|1@1+ (1,0) [0|0] "" Vector__XXX
 SG_ DIR_a041_sdcMIA : 40|1@1+ (1,0) [0|0] "" Vector__XXX
 SG_ DIR_a040_difMIA : 39|1@1+ (1,0) [0|0] "" Vector__XXX
 SG_ DIR_a038_busVsensor : 37|1@1+ (1,0) [0|0] "" Vector__XXX
 SG_ DIR_a037_busUV : 36|1@1+ (1,0) [0|0] "" Vector__XXX
 SG_ DIR_a036_busOV : 35|1@1+ (1,0) [0|0] "" Vector__XXX
 SG_ DIR_a035_phaseCurrentBalance : 34|1@1+ (1,0) [0|0] "" Vector__XXX
 SG_ DIR_a034_phaseBcurrentSensor : 33|1@1+ (1,0) [0|0] "" Vector__XXX
 SG_ DIR_a033_phaseAcurrentSensor : 32|1@1+ (1,0) [0|0] "" Vector__XXX
 SG_ DIR_a032_phaseBcurrentOffset : 31|1@1+ (1,0) [0|0] "" Vector__XXX
 SG_ DIR_a031_phaseAcurrentOffset : 30|1@1+ (1,0) [0|0] "" Vector__XXX
 SG_ DIR_a030_phaseCrms : 29|1@1+ (1,0) [0|0] "" Vector__XXX
 SG_ DIR_a029_phaseBrms : 28|1@1+ (1,0) [0|0] "" Vector__XXX
 SG_ DIR_a028_phaseArms : 27|1@1+ (1,0) [0|0] "" Vector__XXX
 SG_ DIR_a027_phaseCpeak : 26|1@1+ (1,0) [0|0] "" Vector__XXX
 SG_ DIR_a026_phaseBpeak : 25|1@1+ (1,0) [0|0] "" Vector__XXX
 SG_ DIR_a025_phaseApeak : 24|1@1+ (1,0) [0|0] "" Vector__XXX
 SG_ DIR_a024_selfTest : 23|1@1+ (1,0) [0|0] "" Vector__XXX
 SG_ DIR_a022_hw5vSupplyUV : 21|1@1+ (1,0) [0|0] "" Vector__XXX
 SG_ DIR_a021_hwBusOV : 20|1@1+ (1,0) [0|0] "" Vector__XXX
 SG_ DIR_a020_hwMotorEncoder : 19|1@1+ (1,0) [0|0] "" Vector__XXX
 SG_ DIR_a018_hwLVSupplyUV : 17|1@1+ (1,0) [0|0] "" Vector__XXX
 SG_ DIR_a017_hwPedalMonitor : 16|1@1+ (1,0) [0|0] "" Vector__XXX
 SG_ DIR_a016_safeStateApplied : 15|1@1+ (1,0) [0|0] "" Vector__XXX
 SG_ DIR_a015_mechSafeStateAnomaly : 14|1@1+ (1,0) [0|0] "" Vector__XXX
 SG_ DIR_a014_activeDamping : 13|1@1+ (1,0) [0|0] "" Vector__XXX
 SG_ DIR_a013_eccError : 12|1@1+ (1,0) [0|0] "" Vector__XXX
 SG_ DIR_a011_swPowerStageNotReady : 10|1@1+ (1,0) [0|0] "" Vector__XXX
 SG_ DIR_a010_unintendedReset : 9|1@1+ (1,0) [0|0] "" Vector__XXX
 SG_ DIR_a009_hwEncoderB : 8|1@1+ (1,0) [0|0] "" Vector__XXX
 SG_ DIR_a008_hwEncoderA : 7|1@1+ (1,0) [0|0] "" Vector__XXX
 SG_ DIR_a007_statorAnomalyDetected : 6|1@1+ (1,0) [0|0] "" Vector__XXX
 SG_ DIR_a006_hwPhaseCpeak : 5|1@1+ (1,0) [0|0] "" Vector__XXX
 SG_ DIR_a005_hwPhaseBpeak : 4|1@1+ (1,0) [0|0] "" Vector__XXX
 SG_ DIR_a004_hwPhaseApeak : 3|1@1+ (1,0) [0|0] "" Vector__XXX
 SG_ DIR_a003_hwPhaseCgateDrive : 2|1@1+ (1,0) [0|0] "" Vector__XXX
 SG_ DIR_a002_hwPhaseBgateDrive : 1|1@1+ (1,0) [0|0] "" Vector__XXX
 SG_ DIR_a001_hwPhaseAgateDrive : 0|1@1+ (1,0) [0|0] "" Vector__XXX

BO_ 936 VCLEFT_logging1Hz: 8 Vector__XXX
 SG_ VCLEFT_tpmsCurrent m2 : 61|3@1+ (0.01,0) [0|0] "" Vector__XXX
 SG_ VCLEFT_sideMirrorHeaterCurrent m1 : 60|4@1+ (0.5,0) [0|0] "" Vector__XXX
 SG_ VCLEFT_ocsCurrent m2 : 58|3@1+ (0.01,0) [0|0] "" Vector__XXX
 SG_ VCLEFT_sideMirrorCurrent m1 : 56|4@1+ (0.2,0) [0|0] "" Vector__XXX
 SG_ VCLEFT_vbatFused3Current m2 : 53|5@1+ (0.1,0) [0|0] "" Vector__XXX
 SG_ VCLEFT_dirDischargeCurrent m1 : 52|4@1+ (0.1,0) [0|0] "" Vector__XXX
 SG_ VCLEFT_sccmCurrent m1 : 48|4@1+ (0.05,0) [0|0] "" Vector__XXX
 SG_ VCLEFT_vbatFused0Current m2 : 48|5@1+ (0.1,0) [0|0] "" Vector__XXX
 SG_ VCLEFT_accessoryFeed2Current m2 : 43|5@1+ (0.2,0) [0|0] "" Vector__XXX
 SG_ VCLEFT_frontSeatHeatBackrestPwr m0 : 40|7@1+ (1,0) [0|0] "" Vector__XXX
 SG_ VCLEFT_swcCurrent m1 : 40|8@1+ (0.05,0) [0|0] "" Vector__XXX
 SG_ VCLEFT_accessoryFeed1Current m2 : 37|6@1+ (0.1,0) [0|0] "" Vector__XXX
 SG_ VCLEFT_bleBPillarRearHdlrCurrent m1 : 36|4@1+ (0.05,0) [0|0] "" Vector__XXX
 SG_ VCLEFT_trunkFoldFlatSwLEDCurrent m2 : 34|3@1+ (5,0) [0|0] "" Vector__XXX
 SG_ VCLEFT_usbPortsRearCurrentAvg m4 : 34|10@1+ (0.001,0) [0|0] "" Vector__XXX
 SG_ VCLEFT_frontSeatHeatCushionPwr m0 : 32|7@1+ (1,0) [0|0] "" Vector__XXX
 SG_ VCLEFT_lumbarEcuCurrent m1 : 32|4@1+ (0.1,0) [0|0] "" Vector__XXX
 SG_ VCLEFT_rearPuddleLEDCurrent m2 : 31|3@1+ (2,0) [0|0] "" Vector__XXX
 SG_ VCLEFT_frontPuddleLEDCurrent m2 : 28|3@1+ (2,0) [0|0] "" Vector__XXX
 SG_ VCLEFT_mapPocketLEDsCurrent m2 : 25|3@1+ (10,0) [0|0] "" Vector__XXX
 SG_ VCLEFT_rcmCurrent m1 : 24|7@1+ (0.025,0) [0|0] "" Vector__XXX
 SG_ VCLEFT_rgbLedIPFROutput m3 : 24|1@1+ (1,0) [0|0] "" Vector__XXX
 SG_ VCLEFT_swcResistance m0 : 24|7@1+ (0.025,0) [0|0] "" Vector__XXX
 SG_ VCLEFT_usbPortsCurrentAvg m4 : 24|10@1+ (0.001,0) [0|0] "" Vector__XXX
 SG_ VCLEFT_rgbLedIPFLOutput m3 : 23|1@1+ (1,0) [0|0] "" Vector__XXX
 SG_ VCLEFT_intDoorHandleLEDCurrent m2 : 22|3@1+ (2,0) [0|0] "" Vector__XXX
 SG_ VCLEFT_windowSwitchLEDCurrent m2 : 19|3@1+ (10,0) [0|0] "" Vector__XXX
 SG_ VCLEFT_phoneChargingFR m0 : 17|1@1+ (1,0) [0|0] "" Vector__XXX
 SG_ VCLEFT_phoneChargingFL m0 : 16|1@1+ (1,0) [0|0] "" Vector__XXX
 SG_ VCLEFT_tlcCurrent m1 : 16|6@1+ (0.5,0) [0|0] "" Vector__XXX
 SG_ VCLEFT_trunkInteriorLEDCurrent m2 : 15|4@1+ (5,0) [0|0] "" Vector__XXX
 SG_ VCLEFT_12vSocketRearCurrentAvg m4 : 13|10@1+ (0.01,0) [0|0] "" Vector__XXX
 SG_ VCLEFT_rgbLedIPFRCurrent m3 : 13|10@1+ (0.0004887585532746823,0) [0|0] "" Vector__XXX
 SG_ VCLEFT_stopReverseTurnLightCurrent m2 : 11|4@1+ (0.1,0) [0|0] "" Vector__XXX
 SG_ VCLEFT_chargePortCurrent m1 : 8|6@1+ (0.05,0) [0|0] "" Vector__XXX
 SG_ VCLEFT_tohcPCBATemperature m0 : 8|8@1+ (1,-40) [0|0] "" Vector__XXX
 SG_ VCLEFT_turnTailStopLightCurrent m2 : 7|4@1+ (0.1,0) [0|0] "" Vector__XXX
 SG_ VCLEFT_12vSocketFrontCurrentAvg m4 : 3|10@1+ (0.01,0) [0|0] "" Vector__XXX
 SG_ VCLEFT_rgbLedIPFLCurrent m3 : 3|10@1+ (0.0004887585532746823,0) [0|0] "" Vector__XXX
 SG_ VCLEFT_tailLightCurrent m2 : 3|4@1+ (0.1,0) [0|0] "" Vector__XXX
 SG_ VCLEFT_logging1HzIndex M : 0|3@1+ (1,0) [0|0] "" Vector__XXX

BO_ 939 APP_driverMonitorStatus: 5 Vector__XXX
 SG_ APP_ADDWSystemStatus : 28|2@1+ (1,0) [0|0] "" Vector__XXX
 SG_ APP_cabinLowLuxHyst : 27|1@1+ (1,0) [0|0] "" Vector__XXX
 SG_ APP_cabinCamDarkHyst : 26|1@1+ (1,0) [0|0] "" Vector__XXX
 SG_ APP_handsOnInputRequired : 25|1@1+ (1,0) [0|0] "" Vector__XXX
 SG_ APP_driverSeatUnoccupied : 24|1@1+ (1,0) [0|0] "" Vector__XXX
 SG_ APP_driverHandsNotReady : 23|1@1+ (1,0) [0|0] "" Vector__XXX
 SG_ APP_driverLowEyeVisibility : 22|1@1+ (1,0) [0|0] "" Vector__XXX
 SG_ APP_driverLeaningBack : 21|1@1+ (1,0) [0|0] "" Vector__XXX
 SG_ APP_cabinCamInconsistent : 20|1@1+ (1,0) [0|0] "" Vector__XXX
 SG_ APP_cabinLowLux : 19|1@1+ (1,0) [0|0] "" Vector__XXX
 SG_ APP_driverSunglassesUseHyst : 18|1@1+ (1,0) [0|0] "" Vector__XXX
 SG_ APP_driverHeadCappedHyst : 17|1@1+ (1,0) [0|0] "" Vector__XXX
 SG_ APP_driverLowNominal : 16|1@1+ (1,0) [0|0] "" Vector__XXX
 SG_ APP_driverStateUnknownHyst : 15|1@1+ (1,0) [0|0] "" Vector__XXX
 SG_ APP_driverNotLively : 14|1@1+ (1,0) [0|0] "" Vector__XXX
 SG_ APP_driverStateUnknown : 13|1@1+ (1,0) [0|0] "" Vector__XXX
 SG_ APP_cabinCamDark : 12|1@1+ (1,0) [0|0] "" Vector__XXX
 SG_ APP_cabinCamBlinded : 11|1@1+ (1,0) [0|0] "" Vector__XXX
 SG_ APP_handsOnDetectedSource : 8|3@1+ (1,0) [0|0] "" Vector__XXX
 SG_ APP_handsOnDetected : 5|1@1+ (1,0) [0|0] "" Vector__XXX
 SG_ APP_attnBasedDriverMonitorOn : 4|1@1+ (1,0) [0|0] "" Vector__XXX
 SG_ APP_attnMonitorVersion : 1|3@1+ (1,0) [0|0] "" Vector__XXX
 SG_ APP_cabinCamTelemetryOn : 0|1@1+ (1,0) [0|0] "" Vector__XXX

BO_ 942 APP_summonCommand_3AE: 8 Vector__XXX
 SG_ APP_summonCommandChecksum : 56|8@1+ (1,0) [0|0] "" Vector__XXX
 SG_ APP_summonCommandCounter : 52|4@1+ (1,0) [0|0] "" Vector__XXX
 SG_ APP_summonState : 49|3@1+ (1,0) [0|0] "" Vector__XXX
 SG_ APP_summonControllerHeartbeat : 46|3@1+ (1,0) [0|0] "" Vector__XXX
 SG_ APP_summonTimeToCollision : 40|6@1+ (0.1,0) [0|0] "" Vector__XXX
 SG_ APP_summonMaxVelocity : 32|8@1+ (0.05,0) [0|0] "" Vector__XXX
 SG_ APP_summonHomelinkCloseCommand : 31|1@1+ (1,0) [0|0] "" Vector__XXX
 SG_ APP_summonInstruction : 28|3@1+ (1,0) [0|0] "" Vector__XXX
 SG_ APP_summonMonitorStopRequest : 26|2@1+ (1,0) [0|0] "" Vector__XXX
 SG_ APP_summonDistance : 16|10@1+ (0.02,0) [0|0] "" Vector__XXX
 SG_ APP_summonHomelinkOpenCommand : 15|1@1+ (1,0) [0|0] "" Vector__XXX
 SG_ APP_summonSteeringAngleRequest : 0|15@1+ (0.1,-1638.35) [0|0] "" Vector__XXX

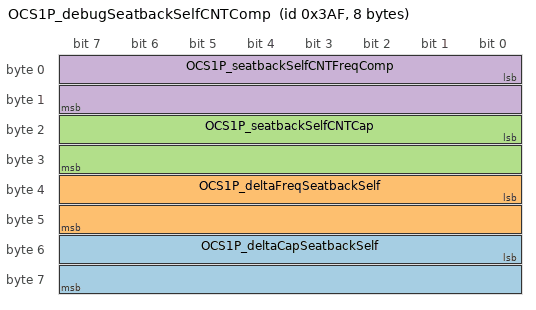
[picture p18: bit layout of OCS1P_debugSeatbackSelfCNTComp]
BO_ 943 OCS1P_debugSeatbackSelfCNTComp: 8 Vector__XXX
 SG_ OCS1P_deltaCapSeatbackSelf : 48|16@1- (0.0025,0) [0|0] "" Vector__XXX
 SG_ OCS1P_deltaFreqSeatbackSelf : 32|16@1- (1,0) [0|0] "" Vector__XXX
 SG_ OCS1P_seatbackSelfCNTCap : 16|16@1+ (0.005,0) [0|0] "" Vector__XXX
 SG_ OCS1P_seatbackSelfCNTFreqComp : 0|16@1+ (1,0) [0|0] "" Vector__XXX

CM_ BO_ 700 "ESP32-DualCAN Model3_CH. Not seen on this car in the logs.";
CM_ BO_ 701 "ESP32-DualCAN Model3_VEH. Seen on this car: 4-byte frames; fit ok (bits covered 100%, mux 100%, ranges 100%).";
CM_ BO_ 702 "ESP32-DualCAN Model3_VEH. Seen on this car: 8-byte frames; fit good (bits covered 100%, mux 100%, ranges 100%).";
VAL_ 702 FC_minVoltageLimit_value 4294934528 "SNA" ;
VAL_ 702 FC_currentLimit_value 4294934528 "SNA" ;
VAL_ 702 FC_powerLimit_value 4294934528 "SNA" ;
CM_ BO_ 703 "ESP32-DualCAN Model3_VEH. Seen on this car: 8-byte frames; fit good (bits covered 100%, mux 100%, ranges 100%).";
CM_ BO_ 704 "ESP32-DualCAN Model3_CH. Not seen on this car in the logs.";
CM_ BO_ 706 "ESP32-DualCAN Model3_VEH. Seen on this car: 8-byte frames; fit good (bits covered 100%, mux 100%, ranges 100%).";
VAL_ 706 VCLEFT_windowPositionStateLR 0 "UNKNOWN" 1 "CLOSED" 2 "CRACKED" 3 "VENT" 4 "PARTIAL_OPEN" 5 "FULL_OPEN" 6 "CLOSED_TRIM_CLEAR" ;
VAL_ 706 VCLEFT_windowPositionStateLF 0 "UNKNOWN" 1 "CLOSED" 2 "CRACKED" 3 "VENT" 4 "PARTIAL_OPEN" 5 "FULL_OPEN" 6 "CLOSED_TRIM_CLEAR" ;
VAL_ 706 VCLEFT_windowCtrlUnavailableLR 0 "NONE" 1 "UNEXPECTED" 2 "SWITCH_PRESSED" 3 "PINCH" 4 "THERMAL_LIMIT" 5 "UNCALIBRATED" 6 "VEHICLE_IN_DRIVE" 7 "WINDOW_MOVING" ;
VAL_ 706 VCLEFT_windowControlStateLR 0 "IDLE" 1 "CLOSING" 2 "GOING_TO_POSITION" ;
VAL_ 706 VCLEFT_windowCtrlUnavailableLF 0 "NONE" 1 "UNEXPECTED" 2 "SWITCH_PRESSED" 3 "PINCH" 4 "THERMAL_LIMIT" 5 "UNCALIBRATED" 6 "VEHICLE_IN_DRIVE" 7 "WINDOW_MOVING" ;
VAL_ 706 VCLEFT_windowControlStateLF 0 "IDLE" 1 "CLOSING" 2 "GOING_TO_POSITION" ;
VAL_ 706 VCLEFT_windowStateLR 0 "STOPPED" 1 "MOVING_UP" 2 "MOVING_DOWN" 3 "BACKOFF" 4 "SHORT_DROP" 5 "SHORT_DROP_REVERSE" 6 "MOVING_AUTO_UP" 7 "MOVING_AUTO_DOWN" 8 "BACKDRIVE" ;
VAL_ 706 VCLEFT_windowStopReqReasonLR 0 "NONE" 1 "SWITCH_CANCEL_AUTO_MOVEMENT" 2 "SWITCH_RELEASED" 3 "REAR_LOCKOUT" 4 "THERMAL" 5 "STALL" 6 "STATE_TIMEOUT" 7 "FULL_OPEN_SOFT_STOP" 8 "EXTERNAL_REQUEST" ;
VAL_ 706 VCLEFT_windowStopReasonLR 0 "NONE" 1 "DOOR_OPEN_TRIM_PROTECT" 2 "NEW_REQUEST" 3 "TARGET_REACHED" 4 "STOP_REQUEST" 5 "FULL_OPEN_SOFT_STOP" 6 "STATE_TIMEOUT" ;
VAL_ 706 VCLEFT_windowThermalModeLR 0 "SNA" 1 "NORMAL" 2 "ALERT" 3 "CRITICAL" ;
VAL_ 706 VCLEFT_windowStopReqReasonLF 0 "NONE" 1 "SWITCH_CANCEL_AUTO_MOVEMENT" 2 "SWITCH_RELEASED" 3 "REAR_LOCKOUT" 4 "THERMAL" 5 "STALL" 6 "STATE_TIMEOUT" 7 "FULL_OPEN_SOFT_STOP" 8 "EXTERNAL_REQUEST" ;
VAL_ 706 VCLEFT_windowStopReasonLF 0 "NONE" 1 "DOOR_OPEN_TRIM_PROTECT" 2 "NEW_REQUEST" 3 "TARGET_REACHED" 4 "STOP_REQUEST" 5 "FULL_OPEN_SOFT_STOP" 6 "STATE_TIMEOUT" ;
VAL_ 706 VCLEFT_windowThermalModeLF 0 "SNA" 1 "NORMAL" 2 "ALERT" 3 "CRITICAL" ;
VAL_ 706 VCLEFT_windowStateLF 0 "STOPPED" 1 "MOVING_UP" 2 "MOVING_DOWN" 3 "BACKOFF" 4 "SHORT_DROP" 5 "SHORT_DROP_REVERSE" 6 "MOVING_AUTO_UP" 7 "MOVING_AUTO_DOWN" 8 "BACKDRIVE" ;
VAL_ 706 VCLEFT_windowStatusIndex 0 "Mux0" 1 "Mux1" ;
CM_ BO_ 707 "ESP32-DualCAN Model3_VEH. Seen on this car: 8-byte frames; fit good (bits covered 100%, mux 100%, ranges 100%).";
VAL_ 707 VCRIGHT_windowPositionStateRR 0 "UNKNOWN" 1 "CLOSED" 2 "CRACKED" 3 "VENT" 4 "PARTIAL_OPEN" 5 "FULL_OPEN" 6 "CLOSED_TRIM_CLEAR" ;
VAL_ 707 VCRIGHT_windowPositionStateRF 0 "UNKNOWN" 1 "CLOSED" 2 "CRACKED" 3 "VENT" 4 "PARTIAL_OPEN" 5 "FULL_OPEN" 6 "CLOSED_TRIM_CLEAR" ;
VAL_ 707 VCRIGHT_windowCtrlUnavailableRR 0 "NONE" 1 "UNEXPECTED" 2 "SWITCH_PRESSED" 3 "PINCH" 4 "THERMAL_LIMIT" 5 "UNCALIBRATED" 6 "VEHICLE_IN_DRIVE" 7 "WINDOW_MOVING" ;
VAL_ 707 VCRIGHT_windowControlStateRR 0 "IDLE" 1 "CLOSING" 2 "GOING_TO_POSITION" ;
VAL_ 707 VCRIGHT_windowCtrlUnavailableRF 0 "NONE" 1 "UNEXPECTED" 2 "SWITCH_PRESSED" 3 "PINCH" 4 "THERMAL_LIMIT" 5 "UNCALIBRATED" 6 "VEHICLE_IN_DRIVE" 7 "WINDOW_MOVING" ;
VAL_ 707 VCRIGHT_windowControlStateRF 0 "IDLE" 1 "CLOSING" 2 "GOING_TO_POSITION" ;
VAL_ 707 VCRIGHT_windowStateRR 0 "STOPPED" 1 "MOVING_UP" 2 "MOVING_DOWN" 3 "BACKOFF" 4 "SHORT_DROP" 5 "SHORT_DROP_REVERSE" 6 "MOVING_AUTO_UP" 7 "MOVING_AUTO_DOWN" 8 "BACKDRIVE" ;
VAL_ 707 VCRIGHT_windowStopReqReasonRR 0 "NONE" 1 "SWITCH_CANCEL_AUTO_MOVEMENT" 2 "SWITCH_RELEASED" 3 "REAR_LOCKOUT" 4 "THERMAL" 5 "STALL" 6 "STATE_TIMEOUT" 7 "FULL_OPEN_SOFT_STOP" 8 "EXTERNAL_REQUEST" ;
VAL_ 707 VCRIGHT_windowStopReasonRR 0 "NONE" 1 "DOOR_OPEN_TRIM_PROTECT" 2 "NEW_REQUEST" 3 "TARGET_REACHED" 4 "STOP_REQUEST" 5 "FULL_OPEN_SOFT_STOP" 6 "STATE_TIMEOUT" ;
VAL_ 707 VCRIGHT_windowThermalModeRR 0 "SNA" 1 "NORMAL" 2 "ALERT" 3 "CRITICAL" ;
VAL_ 707 VCRIGHT_windowStopReqReasonRF 0 "NONE" 1 "SWITCH_CANCEL_AUTO_MOVEMENT" 2 "SWITCH_RELEASED" 3 "REAR_LOCKOUT" 4 "THERMAL" 5 "STALL" 6 "STATE_TIMEOUT" 7 "FULL_OPEN_SOFT_STOP" 8 "EXTERNAL_REQUEST" ;
VAL_ 707 VCRIGHT_windowStopReasonRF 0 "NONE" 1 "DOOR_OPEN_TRIM_PROTECT" 2 "NEW_REQUEST" 3 "TARGET_REACHED" 4 "STOP_REQUEST" 5 "FULL_OPEN_SOFT_STOP" 6 "STATE_TIMEOUT" ;
VAL_ 707 VCRIGHT_windowThermalModeRF 0 "SNA" 1 "NORMAL" 2 "ALERT" 3 "CRITICAL" ;
VAL_ 707 VCRIGHT_windowStateRF 0 "STOPPED" 1 "MOVING_UP" 2 "MOVING_DOWN" 3 "BACKOFF" 4 "SHORT_DROP" 5 "SHORT_DROP_REVERSE" 6 "MOVING_AUTO_UP" 7 "MOVING_AUTO_DOWN" 8 "BACKDRIVE" ;
VAL_ 707 VCRIGHT_windowStatusIndex 0 "Mux0" 1 "Mux1" ;
CM_ BO_ 709 "ESP32-DualCAN Model3_CH. Not seen on this car in the logs.";
CM_ BO_ 710 "ESP32-DualCAN Model3_CH. Not seen on this car in the logs.";
CM_ BO_ 711 "ESP32-DualCAN Model3_VEH. Seen on this car: 8-byte frames; fit good (bits covered 100%, mux 100%, ranges 100%).";
CM_ BO_ 727 "ESP32-DualCAN Model3_VEH. Seen on this car: 4-byte frames; fit ok (bits covered 100%, mux 100%, ranges 100%).";
VAL_ 727 VCLEFT_pitchEstimate 4294967232 "SNA" ;
CM_ BO_ 728 "ESP32-DualCAN Model3_VEH. Seen on this car: 2-byte frames; fit poor (bits covered 0%, mux 100%, ranges 100%).";
VAL_ 728 ICR_nmWakeUpReason 0 "NONE" 1 "CAN_VEH" 2 "CAN_HVS" 3 "WANTTOCHARGE" 4 "CRITICALALERT" 5 "WANTTOWARM" ;
VAL_ 728 ICR_nmKeepAwakeReason 0 "NONE_SNA" 1 "CTRS_CLOSED" 2 "CRITICAL_ALERT" 3 "FC_CTR_CLEANING" 4 "HVP_ACTIVE" 5 "BMS_ACTIVE" 6 "CP_ACTIVE" ;
CM_ BO_ 733 "ESP32-DualCAN Model3_VEH. Not seen on this car in the logs.";
CM_ BO_ 735 "ESP32-DualCAN Model3_VEH. Not seen on this car in the logs.";
CM_ BO_ 738 "ESP32-DualCAN Model3_VEH. Seen on this car: 8-byte frames; fit good (bits covered 100%, mux 100%, ranges 100%).";
VAL_ 738 VCLEFT_frontSeatHeatTmpTarget 0 "OFF" ;
VAL_ 738 VCLEFT_frontSeatHeatTmp 0 "SNA" ;
VAL_ 738 VCLEFT_seatStatus2Index 0 "SEAT_HEAT_FRONT" 1 "SEAT_HEAT_REARL_BACKREST" 2 "OCCUPANCY" 3 "SEAT_HEAT_REARL" 4 "SEAT_HEAT_REARC" 5 "SEAT_HEAT_REARR_CUSHION" 6 "SEAT_2ROW_ACTUATOR" 7 "SEAT_SWITCH_VOLTAGES_1" 8 "SEAT_SWITCH_VOLTAGES_2" 9 "SEAT_2ROW_EASY_ENTRY" 10 "SEAT_STATUS_2_INDEX_COUNT" ;
CM_ BO_ 739 "ESP32-DualCAN Model3_VEH. Seen on this car: 7-byte frames; fit ok (bits covered 100%, mux 100%, ranges 100%).";
VAL_ 739 VCRIGHT_frontSeatHeatTmpTarget 0 "OFF" ;
VAL_ 739 VCRIGHT_frontSeatHeatTmp 0 "SNA" ;
VAL_ 739 VCRIGHT_seatStatus2Index 0 "SEAT_HEAT_FRONT" 1 "SEAT_HEAT_REARL_CUSHION" 2 "SEAT_HEAT_REARC" 3 "SEAT_HEAT_REARR" 4 "OCCUPANCY" 5 "SEAT_HEAT_REARR_BACKREST" 6 "SEAT_2ROW_ACTUATOR" 7 "SEAT_SWITCH_VOLTAGES_1" 8 "SEAT_SWITCH_VOLTAGES_2" 9 "SEAT_2ROW_EASY_ENTRY" 10 "OCS_IEE" 11 "SEAT_STATUS_2_INDEX_COUNT" ;
CM_ BO_ 740 "ESP32-DualCAN Model3_VEH. Not seen on this car in the logs.";
VAL_ 740 PCS2_ambientTemp 4294966273 "SNA" ;
VAL_ 740 PCS2_lite_buck_duty 127 "SNA" ;
VAL_ 740 PCS2_lite_ambientTemp 4294966273 "SNA" ;
VAL_ 740 PCS2_lite_boost_duty 127 "SNA" ;
VAL_ 740 PCS2_logMessageSelect 0 "PHA_1" 1 "PHB_1" 2 "PHC_1" 3 "CHG_1" 4 "CHG_2" 5 "CHG_3" 6 "DCDC_1" 7 "DCDC_2" 8 "DCDC_3" 9 "SYSTEM_1" 10 "PHA_2" 11 "PHB_2" 12 "PHC_2" 13 "CHG_4" 14 "DLOG_1" 15 "DLOG_2" 16 "DLOG_3" 17 "DLOG_4" 18 "DCDC_4" 19 "DCDC_5" 20 "CHG_NO_FLOW" 21 "CHG_LINE_OFFSET" 22 "DCDC_STATISTICS" 23 "CHG_MACHINEMODEL" 24 "DCDC_HVBUS_PCHG_DATA" 25 "DCDC_IMPEDANCE_EST" 26 "PROCESSOR_DIE_ID" 27 "NUM_MSGS" ;
CM_ BO_ 745 "ESP32-DualCAN Model3_VEH. Not seen on this car in the logs.";
CM_ BO_ 748 "ESP32-DualCAN Model3_VEH. Seen on this car: 3-byte frames; fit ok (bits covered 100%, mux 100%, ranges 100%, checksum 100%).";
CM_ BO_ 760 "ESP32-DualCAN Model3_CH. Seen on this car: 8-byte frames; fit good (bits covered 100%, mux 100%, ranges 100%).";
VAL_ 760 UI_conditionalSpeedLimit 31 "SNA" ;
VAL_ 760 UI_userSpeedOffsetUnits 0 "MPH" 1 "KPH" ;
VAL_ 760 UI_mapSpeedLimitUnits 0 "MPH" 1 "KPH" ;
CM_ BO_ 761 "ESP32-DualCAN Model3_VEH. Seen on this car: 8-byte frames; fit good (bits covered 100%, mux 100%, ranges 100%).";
VAL_ 761 VCSEC_AdditionalAuthInfoIndex 0 "ACTIVE_KEY_SHA1" 1 "KEY_WITH_IN_SUMMON_RANGE_0" 2 "KEY_WITH_IN_SUMMON_RANGE_1" 3 "KEY_WITH_IN_SUMMON_RANGE_2" 4 "UNKNOWN_BLE_DEVICE_WITH_IN_SUMMON_RANGE" 5 "WALKUP_UNLOCK_BEHAVIOR" ;
VAL_ 761 VCSEC_activeKeyReason 0 "NONE" 1 "NFC_AUTH" 2 "RKE_AUTH" 3 "BLE_DEVICE_CLOSEST_TO_DOOR" 4 "RKE_ACTION" 5 "ONLY_AUTHED_DEVICE" 6 "AUTO_PRESENT_DOOR_COMMAND" ;
VAL_ 761 VCSEC_bleDisconnectionReason 0 "UNKNOWN_REASON_0" 5 "AUTHENTICATION_FAILURE" 8 "CONNECTION_SUPERVISION_TIMEOUT" 19 "REMOTE_USER_TERMINATED" 20 "REMOTE_DEVICE_LOW_RESOURCES" 21 "REMOTE_DEVICE_POWER_OFF" 22 "HOST_REQUESTED_TERMINATION" 26 "UNSUPPORTED_REMOTE_FEATURE" 34 "CONTROL_PACKET_TIMEOUT" 40 "CONTROL_PACKET_INSTANT_PASSED" 41 "KEY_PAIRING_NOT_SUPPORTED" 59 "UNACCEPTABLE_CONNECTION_INTERVAL" 61 "MIC_FAILURE" 62 "CONNECTION_FAILED_TO_ESTABLISH" 255 "UNKNOWN_REASON_FF" ;
CM_ BO_ 775 "ESP32-DualCAN Model3_VEH. Not seen on this car in the logs.";
CM_ BO_ 776 "ESP32-DualCAN Model3_VEH. Seen on this car: 8-byte frames; fit ok (bits covered 88%, mux 100%, ranges 100%, checksum 0%).";
VAL_ 776 OCS1P_occupantClassificationQF 0 "FAULTED" 1 "NOT_FAULTED" ;
VAL_ 776 OCS1P_occupantClassification 0 "EMPTY" 1 "INHIBIT" 2 "SMALL" 3 "LARGE" 4 "INIT" 5 "NOT_CONFIGURED" 7 "SNA" ;
CM_ BO_ 781 "ESP32-DualCAN Model3_CH. Not seen on this car in the logs.";
CM_ BO_ 783 "ESP32-DualCAN Model3_CH. Seen on this car: 6-byte frames; fit poor (bits covered 0%, mux 100%, ranges 100%).";
CM_ BO_ 803 "ESP32-DualCAN Model3_VEH. Seen on this car: 5-byte frames; fit ok (bits covered 100%, mux 100%, ranges 100%).";
CM_ BO_ 804 "ESP32-DualCAN Model3_VEH. Seen on this car: 8-byte frames; fit good (bits covered 100%, mux 100%, ranges 100%).";
CM_ BO_ 807 "ESP32-DualCAN Model3_CH. Not seen on this car in the logs.";
VAL_ 807 USM_infoAssemblyId 1 "ASSEMBLY1" 255 "ASSEMBLY_SNA" ;
VAL_ 807 USM_infoBuildType 0 "UNKNOWN_BUILD" 1 "PLATFORM_BUILD" 2 "LOCAL_BUILD" 3 "TRACEABLE_CI_BUILD" 4 "MFG_BUILD" ;
VAL_ 807 USM_infoIndex 0 "DEPRECATED_0" 1 "DEPRECATED_1" 2 "DEPRECATED_2" 3 "DEPRECATED_3" 4 "DEPRECATED_4" 5 "DEPRECATED_5" 6 "DEPRECATED_6" 7 "DEPRECATED_7" 8 "DEPRECATED_8" 9 "DEPRECATED_9" 10 "BUILD_HWID_COMPONENTID" 11 "PCBAID_ASSYID_USAGEID" 13 "APP_CRC" 14 "BOOTLOADER_SVN" 15 "BOOTLOADER_CRC" 16 "SUBCOMPONENT" 17 "APP_GITHASH" 18 "BOOTLOADER_GITHASH" 19 "VERSION_DEPRECATED" 20 "UDS_PROTOCOL_BOOTCRC" 22 "VARIANTCRC" 25 "PACKAGE_PN_1_7" 26 "PACKAGE_PN_8_14" 27 "PACKAGE_PN_15_20" 29 "PACKAGE_SN_1_7" 30 "PACKAGE_SN_8_14" 31 "SUBCOMPONENT_GITHASH" 255 "END" ;
CM_ BO_ 820 "ESP32-DualCAN Model3_VEH. Seen on this car: 8-byte frames; fit ok (bits covered 82%, mux 100%, ranges 100%, checksum 100%).";
VAL_ 820 UI_speedLimit 511 "SNA" ;
VAL_ 820 UI_stoppingMode 0 "STANDARD" 1 "CREEP" 2 "HOLD" ;
VAL_ 820 UI_wasteModeRegenLimit 0 "MAX" 1 "30A" 2 "10A" 3 "0A" ;
VAL_ 820 UI_wasteMode 0 "NONE" 1 "PARTIAL" 2 "FULL" 3 "BURN_IN" ;
VAL_ 820 UI_motorOnMode 0 "NORMAL" 1 "FRONT_ONLY" 2 "REAR_ONLY" ;
VAL_ 820 UI_limitMode 0 "NORMAL" 1 "VALET" 2 "FACTORY" 3 "SERVICE" ;
VAL_ 820 UI_closureConfirmed 0 "NONE" 1 "FRUNK" 2 "PROX" 3 "FALCON" ;
VAL_ 820 UI_systemTorqueLimit 63 "SNA" ;
VAL_ 820 UI_pedalMap 0 "CHILL" 1 "SPORT" 2 "PERFORMANCE" ;
VAL_ 820 UI_systemPowerLimit 31 "SNA" ;
CM_ BO_ 829 "ESP32-DualCAN Model3_VEH. Seen on this car: 8-byte frames; fit weak (bits covered 0%, mux 100%, ranges 100%).";
CM_ BO_ 833 "ESP32-DualCAN Model3_VEH. Not seen on this car in the logs.";
VAL_ 833 VCFRONT1_matrixIndex 0 "AlertMatrix0" 1 "AlertMatrix1" 2 "AlertMatrix2" ;
CM_ BO_ 834 "ESP32-DualCAN Model3_VEH. Not seen on this car in the logs.";
VAL_ 834 VCFRONT2_matrixIndex 0 "AlertMatrix0" 1 "AlertMatrix1" 2 "AlertMatrix2" ;
CM_ BO_ 835 "ESP32-DualCAN Model3_VEH. Seen on this car: 8-byte frames; fit good (bits covered 100%, mux 100%, ranges 100%).";
VAL_ 835 VCRIGHT_mirrorHeatState 0 "SNA" 1 "ON" 2 "OFF" 3 "OFF_UNAVAILABLE" 4 "FAULT" ;
CM_ BO_ 836 "ESP32-DualCAN Model3_VEH. Seen on this car: 8-byte frames; fit good (bits covered 100%, mux 100%, ranges 100%, checksum 100%).";
CM_ BO_ 838 "ESP32-DualCAN Model3_CH. Seen on this car: 8-byte frames; fit weak (bits covered 0%, mux 100%, ranges 100%).";
VAL_ 838 GTW_autopilotOverrideState 0 "BASE" 1 "SUBSCRIPTION" 2 "TRIAL" ;
CM_ BO_ 839 "DashKit DBC. Seen on this car: 8-byte frames; fit ok (bits covered 58%, mux 100%, ranges 100%).";
CM_ BO_ 842 "ESP32-DualCAN Model3_VEH. Seen on this car: 8-byte frames; fit good (bits covered 100%, mux 100%, ranges 100%).";
CM_ BO_ 843 "ESP32-DualCAN Model3_CH. Seen on this car: 6-byte frames; fit ok (bits covered 100%, mux 100%, ranges 100%).";
CM_ BO_ 847 "ESP32-DualCAN Model3_CH. Seen on this car: 8-byte frames; fit good (bits covered 100%, mux 100%, ranges 100%).";
CM_ BO_ 852 "ESP32-DualCAN Model3_CH. Seen on this car: 6-byte frames; fit ok (bits covered 100%, mux 100%, ranges 100%).";
CM_ BO_ 853 "ESP32-DualCAN Model3_VEH. Seen on this car: 7-byte frames; fit ok (bits covered 100%, mux 100%, ranges 100%).";
CM_ BO_ 863 "ESP32-DualCAN Model3_VEH. Seen on this car: 1-byte frames; fit poor (bits covered 0%, mux 100%, ranges 100%).";
CM_ BO_ 865 "ESP32-DualCAN Model3_VEH. Seen on this car: 5-byte frames; fit ok (bits covered 100%, mux 100%, ranges 100%).";
CM_ BO_ 866 "ESP32-DualCAN Model3_VEH. Seen on this car: 3-byte frames; fit poor (bits covered 0%, mux 100%, ranges 100%).";
VAL_ 866 VCLEFT_crashState 0 "IDLE" 1 "MINOR_1" 2 "MINOR_2" 3 "SEVERE" ;
VAL_ 866 VCLEFT_crashDetectedType 0 "NONE" 1 "MINOR_1" 2 "MINOR_2" 3 "SEVERE" ;
CM_ BO_ 868 "ESP32-DualCAN Model3_VEH. Seen on this car: 4-byte frames; fit ok (bits covered 100%, mux 100%, ranges 100%).";
CM_ BO_ 870 "ESP32-DualCAN Model3_VEH. Seen on this car: 8-byte frames; fit ok (bits covered 100%, mux 100%, ranges 100%).";
VAL_ 870 CMPD_infoAssemblyId 1 "ASSEMBLY1" 255 "ASSEMBLY_SNA" ;
VAL_ 870 CMPD_infoBuildType 0 "UNKNOWN_BUILD" 1 "PLATFORM_BUILD" 2 "LOCAL_BUILD" 3 "TRACEABLE_CI_BUILD" 4 "MFG_BUILD" ;
VAL_ 870 CMPD_infoIndex 0 "DEPRECATED_0" 1 "DEPRECATED_1" 2 "DEPRECATED_2" 3 "DEPRECATED_3" 4 "DEPRECATED_4" 5 "DEPRECATED_5" 6 "DEPRECATED_6" 7 "DEPRECATED_7" 8 "DEPRECATED_8" 9 "DEPRECATED_9" 10 "BUILD_HWID_COMPONENTID" 11 "PCBAID_ASSYID_USAGEID" 13 "APP_CRC" 14 "BOOTLOADER_SVN" 15 "BOOTLOADER_CRC" 16 "SUBCOMPONENT" 17 "APP_GITHASH" 18 "BOOTLOADER_GITHASH" 19 "VERSION_DEPRECATED" 20 "UDS_PROTOCOL_BOOTCRC" 22 "VARIANTCRC" 25 "PACKAGE_PN_1_7" 26 "PACKAGE_PN_8_14" 27 "PACKAGE_PN_15_20" 29 "PACKAGE_SN_1_7" 30 "PACKAGE_SN_8_14" 31 "SUBCOMPONENT_GITHASH" 255 "END" ;
CM_ BO_ 871 "ESP32-DualCAN Model3_VEH. Seen on this car: 8-byte frames; fit ok (bits covered 50%, mux 100%, ranges 100%).";
CM_ BO_ 875 "ESP32-DualCAN Model3_VEH. Not seen on this car in the logs.";
CM_ BO_ 878 "ESP32-DualCAN Model3_VEH. Not seen on this car in the logs.";
CM_ BO_ 885 "ESP32-DualCAN Model3_VEH. Not seen on this car in the logs.";
CM_ BO_ 887 "ESP32-DualCAN Model3_VEH. Not seen on this car in the logs.";
CM_ BO_ 889 "ESP32-DualCAN Model3_VEH. Seen on this car: 8-byte frames; fit good (bits covered 100%, mux 100%, ranges 100%).";
CM_ BO_ 893 "ESP32-DualCAN Model3_VEH. Seen on this car: 8-byte frames; fit good (bits covered 100%, mux 100%, ranges 100%).";
VAL_ 893 CP_thermalStatusSelect 0 "0" 1 "1" ;
CM_ BO_ 896 "ESP32-DualCAN Model3_VEH. Not seen on this car in the logs.";
CM_ BO_ 898 "ESP32-DualCAN Model3_VEH. Seen on this car: 5-byte frames; fit ok (bits covered 100%, mux 100%, ranges 100%).";
CM_ BO_ 902 "ESP32-DualCAN Model3_VEH. Seen on this car: 8-byte frames; fit ok (bits covered 67%, mux 100%, ranges 100%).";
CM_ BO_ 903 "ESP32-DualCAN Model3_VEH. Not seen on this car in the logs.";
CM_ BO_ 906 "ESP32-DualCAN Model3_VEH. Seen on this car: 8-byte frames; fit good (bits covered 100%, mux 100%, ranges 100%).";
CM_ BO_ 907 "ESP32-DualCAN Model3_CH. Seen on this car: 5-byte frames; fit ok (bits covered 100%, mux 100%, ranges 100%).";
CM_ BO_ 912 "ESP32-DualCAN Model3_VEH. Seen on this car: 2-byte frames; fit poor (bits covered 0%, mux 100%, ranges 100%).";
CM_ BO_ 919 "ESP32-DualCAN Model3_VEH. Seen on this car: 8-byte frames; fit good (bits covered 100%, mux 100%, ranges 100%).";
CM_ BO_ 922 "ESP32-DualCAN Model3_VEH. Seen on this car: 8-byte frames; fit good (bits covered 100%, mux 100%, ranges 100%).";
VAL_ 922 VCSEC_RSSI2ConnectionType 0 "NONE" 1 "PERIPHERAL" 2 "CENTRAL" ;
VAL_ 922 VCSEC_RSSI1ConnectionType 0 "NONE" 1 "PERIPHERAL" 2 "CENTRAL" ;
VAL_ 922 VCSEC_RSSI0ConnectionType 0 "NONE" 1 "PERIPHERAL" 2 "CENTRAL" ;
CM_ BO_ 923 "ESP32-DualCAN Model3_VEH. Seen on this car: 8-byte frames; fit good (bits covered 100%, mux 100%, ranges 100%, checksum 100%).";
VAL_ 923 DAS_autoLaneChangeState 0 "UNAVAILABLE_DISABLED" 1 "UNAVAILABLE_NO_LANES" 2 "UNAVAILABLE_SONICS_INVALID" 3 "UNAVAILABLE_TP_FOLLOW" 4 "UNAVAILABLE_EXITING_HIGHWAY" 5 "UNAVAILABLE_VEHICLE_SPEED" 6 "AVAILABLE_ONLY_L" 7 "AVAILABLE_ONLY_R" 8 "AVAILABLE_BOTH" 9 "IN_PROGRESS_L" 10 "IN_PROGRESS_R" 11 "WAITING_FOR_SIDE_OBST_TO_PASS_L" 12 "WAITING_FOR_SIDE_OBST_TO_PASS_R" 13 "WAITING_FOR_FWD_OBST_TO_PASS_L" 14 "WAITING_FOR_FWD_OBST_TO_PASS_R" 15 "ABORT_SIDE_OBSTACLE_PRESENT_L" 16 "ABORT_SIDE_OBSTACLE_PRESENT_R" 17 "ABORT_POOR_VIEW_RANGE" 18 "ABORT_LC_HEALTH_BAD" 19 "ABORT_BLINKER_TURNED_OFF" 20 "ABORT_OTHER_REASON" 21 "UNAVAILABLE_SOLID_LANE_LINE" 22 "BLOCKED_VEH_TTC_L" 23 "BLOCKED_VEH_TTC_AND_USS_L" 24 "BLOCKED_VEH_TTC_R" 25 "BLOCKED_VEH_TTC_AND_USS_R" 26 "BLOCKED_LANE_TYPE_L" 27 "BLOCKED_LANE_TYPE_R" 28 "WAITING_HANDS_ON" 29 "ABORT_TIMEOUT" 30 "ABORT_MISSION_PLAN_INVALID" 31 "SNA" ;
VAL_ 923 DAS_autopilotHandsOnState 0 "NOT_REQD" 1 "REQD_DETECTED" 2 "REQD_NOT_DETECTED" 3 "REQD_VISUAL" 4 "REQD_CHIME_1" 5 "REQD_CHIME_2" 6 "REQD_SLOWING" 7 "REQD_STRUCK_OUT" 8 "SUSPENDED" 9 "REQD_ESCALATED_CHIME_1" 10 "REQD_ESCALATED_CHIME_2" 15 "SNA" ;
VAL_ 923 DAS_fleetSpeedState 0 "UNAVAILABLE" 1 "AVAILABLE" 2 "ACTIVE" 3 "HOLD" ;
VAL_ 923 DAS_laneDepartureWarning 0 "NONE" 1 "LEFT_WARNING" 2 "RIGHT_WARNING" 3 "LEFT_WARNING_SEVERE" 4 "RIGHT_WARNING_SEVERE" 5 "SNA" ;
VAL_ 923 DAS_sideCollisionInhibit 0 "NO_INHIBIT" 1 "INHIBIT" ;
VAL_ 923 DAS_sideCollisionWarning 0 "NONE" 1 "WARN_LEFT" 2 "WARN_RIGHT" 3 "WARN_LEFT_RIGHT" ;
VAL_ 923 DAS_sideCollisionAvoid 0 "NONE" 1 "AVOID_LEFT" 2 "AVOID_RIGHT" 3 "SNA" ;
VAL_ 923 DAS_lssState 0 "FAULT" 1 "LDW" 2 "LKA" 3 "ELK" 4 "MONITOR" 5 "BLINDSPOT" 6 "ABORT" 7 "OFF" ;
VAL_ 923 DAS_autoparkReady 0 "UNAVAILABLE" 1 "READY" ;
VAL_ 923 DAS_forwardCollisionWarning 0 "NONE" 1 "FORWARD_COLLISION_WARNING" 3 "SNA" ;
VAL_ 923 DAS_heaterState 0 "OFF_SNA" 1 "ON" ;
VAL_ 923 DAS_visionOnlySpeedLimit 0 "UNKNOWN_SNA" 31 "NONE" ;
VAL_ 923 DAS_suppressSpeedWarning 0 "Do_Not_Suppress" 1 "Suppress_Speed_Warning" ;
VAL_ 923 DAS_fusedSpeedLimit 0 "UNKNOWN_SNA" 31 "NONE" ;
VAL_ 923 DAS_blindSpotRearRight 0 "NO_WARNING" 1 "WARNING_LEVEL_1" 2 "WARNING_LEVEL_2" 3 "SNA" ;
VAL_ 923 DAS_blindSpotRearLeft 0 "NO_WARNING" 1 "WARNING_LEVEL_1" 2 "WARNING_LEVEL_2" 3 "SNA" ;
VAL_ 923 DAS_autopilotState 0 "DISABLED" 1 "UNAVAILABLE" 2 "AVAILABLE" 3 "ACTIVE_NOMINAL" 4 "ACTIVE_RESTRICTED" 5 "ACTIVE_NAV" 6 "ACTIVE_FSD" 8 "ABORTING" 9 "ABORTED" 14 "FAULT" 15 "SNA" ;
CM_ BO_ 928 "ESP32-DualCAN Model3_VEH. Not seen on this car in the logs.";
CM_ BO_ 931 "ESP32-DualCAN Model3_VEH. Seen on this car: 8-byte frames; fit good (bits covered 100%, mux 100%, ranges 100%).";
CM_ BO_ 935 "ESP32-DualCAN Model3_VEH. Seen on this car: 8-byte frames; fit good (bits covered 100%, mux 100%, ranges 100%).";
CM_ BO_ 936 "ESP32-DualCAN Model3_VEH. Seen on this car: 8-byte frames; fit good (bits covered 100%, mux 100%, ranges 100%).";
VAL_ 936 VCLEFT_logging1HzIndex 0 "HVAC_ACTUATOR_VOLTAGES" 1 "HVAC_ACTUATOR_ENDSTOP" 2 "HVAC_ACTUATOR_ZEROSTOP" 3 "HVAC_ACTUATOR_OPERATION_MODE" 4 "END" ;
CM_ BO_ 939 "ESP32-DualCAN Model3_CH. Seen on this car: 5-byte frames; fit poor (bits covered 0%, mux 100%, ranges 100%).";
CM_ BO_ 942 "ESP32-DualCAN Model3_VEH. Seen on this car: 8-byte frames; fit ok (bits covered 100%, mux 100%, ranges 100%, checksum 0%).";
VAL_ 942 APP_summonState 0 "INIT" 1 "IDLE" 2 "ARMED" 3 "ACTIVE" 4 "COMPLETE" 5 "FAULT" 6 "UNAVAILABLE" ;
CM_ BO_ 943 "ESP32-DualCAN Model3_CH. Seen on this car: 8-byte frames; fit good (bits covered 100%, mux 100%, ranges 100%).";
